VERSION "HNNBNNNYNNNNNNNNNNNNNNNNNNNNNNNNNNNNNNNNNN/4/%%%/4/'%**4NNN///"

NS_ :

BS_:

BU_: AEM BAP_Tester E_Sound FBK FLA Gateway Gateway_PAG ISE MRR_HL MRR_HR NightVision RDK SAK SAK2 SCR STH_MLBevo TopView

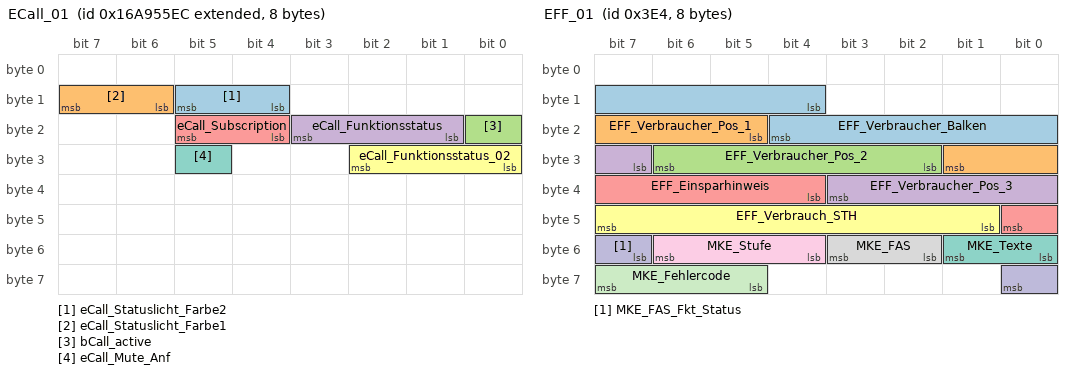
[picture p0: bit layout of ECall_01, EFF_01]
BO_ 2527679980 ECall_01: 8 Gateway
 SG_ eCall_Statuslicht_Farbe2 : 12|2@1+ (1.0,0.0) [0.0|3] ""  Vector__XXX
 SG_ eCall_Statuslicht_Farbe1 : 14|2@1+ (1.0,0.0) [0.0|3] ""  Vector__XXX
 SG_ bCall_active : 16|1@1+ (1.0,0.0) [0.0|1] ""  Vector__XXX
 SG_ eCall_Funktionsstatus : 17|3@1+ (1.0,0.0) [0.0|7] ""  Vector__XXX
 SG_ eCall_Subscription : 20|2@1+ (1.0,0.0) [0.0|3] ""  Vector__XXX
 SG_ eCall_Funktionsstatus_02 : 24|3@1+ (1.0,0.0) [0.0|7] ""  SAK,SAK2
 SG_ eCall_Mute_Anf : 29|1@1+ (1.0,0.0) [0.0|1] ""  SAK,SAK2

BO_ 996 EFF_01: 8 Gateway
 SG_ EFF_Verbraucher_Balken : 12|9@1+ (0.01,0) [0.00|5.09] "Unit_LiterPerHour"  Vector__XXX
 SG_ EFF_Verbraucher_Pos_1 : 21|5@1+ (1.0,0.0) [0.0|31] ""  Vector__XXX
 SG_ EFF_Verbraucher_Pos_2 : 26|5@1+ (1.0,0.0) [0.0|31] ""  Vector__XXX
 SG_ EFF_Verbraucher_Pos_3 : 31|5@1+ (1.0,0.0) [0.0|31] ""  Vector__XXX
 SG_ EFF_Einsparhinweis : 36|5@1+ (1.0,0.0) [0.0|31] ""  Vector__XXX
 SG_ EFF_Verbrauch_STH : 41|7@1+ (0.01,0) [0.00|1.26] "Unit_LiterPerHour"  Vector__XXX
 SG_ MKE_Texte : 48|2@1+ (1.0,0.0) [0.0|3] ""  NightVision
 SG_ MKE_FAS : 50|2@1+ (1.0,0.0) [0.0|3] ""  NightVision
 SG_ MKE_Stufe : 52|3@1+ (1.0,0.0) [0.0|7] ""  Vector__XXX
 SG_ MKE_FAS_Fkt_Status : 55|2@1+ (1.0,0.0) [0.0|3] ""  Vector__XXX
 SG_ MKE_Fehlercode : 61|3@1+ (1.0,0.0) [0.0|7] ""  Vector__XXX

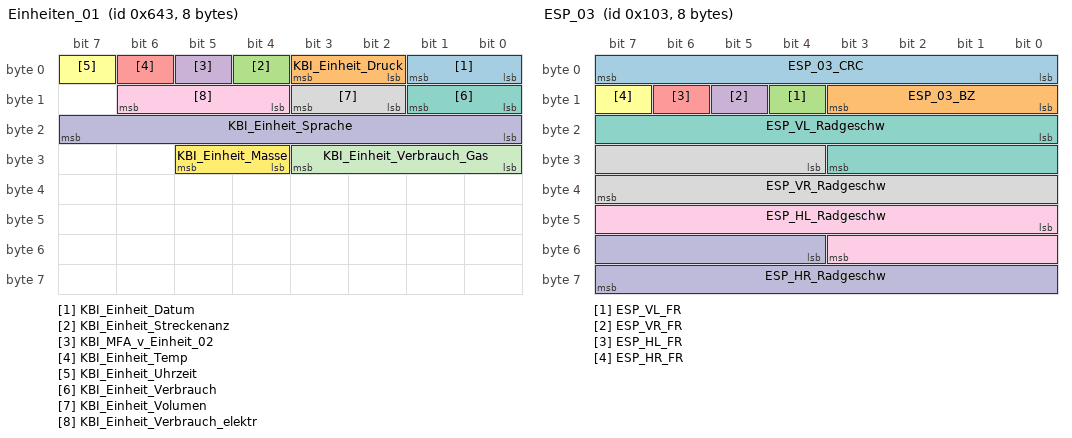
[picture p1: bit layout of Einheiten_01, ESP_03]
BO_ 1603 Einheiten_01: 8 Gateway
 SG_ KBI_Einheit_Datum : 0|2@1+ (1.0,0.0) [0.0|3] ""  Vector__XXX
 SG_ KBI_Einheit_Druck : 2|2@1+ (1.0,0.0) [0.0|3] ""  RDK
 SG_ KBI_Einheit_Streckenanz : 4|1@1+ (1.0,0.0) [0.0|1] ""  Vector__XXX
 SG_ KBI_MFA_v_Einheit_02 : 5|1@1+ (1.0,0.0) [0.0|1] ""  Vector__XXX
 SG_ KBI_Einheit_Temp : 6|1@1+ (1.0,0.0) [0.0|1] ""  RDK
 SG_ KBI_Einheit_Uhrzeit : 7|1@1+ (1.0,0.0) [0.0|1] ""  Vector__XXX
 SG_ KBI_Einheit_Verbrauch : 8|2@1+ (1.0,0.0) [0.0|3] ""  Vector__XXX
 SG_ KBI_Einheit_Volumen : 10|2@1+ (1.0,0.0) [0.0|3] ""  Vector__XXX
 SG_ KBI_Einheit_Verbrauch_elektr : 12|3@1+ (1.0,0.0) [0.0|7] ""  Vector__XXX
 SG_ KBI_Einheit_Sprache : 16|8@1+ (1,0) [0|255] ""  Vector__XXX
 SG_ KBI_Einheit_Verbrauch_Gas : 24|4@1+ (1.0,0.0) [0.0|15] ""  Vector__XXX
 SG_ KBI_Einheit_Masse : 28|2@1+ (1.0,0.0) [0.0|3] ""  Vector__XXX

BO_ 259 ESP_03: 8 Gateway
 SG_ ESP_03_CRC : 0|8@1+ (1,0) [0|255] ""  Vector__XXX
 SG_ ESP_03_BZ : 8|4@1+ (1,0) [0|15] ""  Vector__XXX
 SG_ ESP_VL_FR : 12|1@1+ (1.0,0.0) [0.0|1] ""  Vector__XXX
 SG_ ESP_VR_FR : 13|1@1+ (1.0,0.0) [0.0|1] ""  Vector__XXX
 SG_ ESP_HL_FR : 14|1@1+ (1.0,0.0) [0.0|1] ""  Vector__XXX
 SG_ ESP_HR_FR : 15|1@1+ (1.0,0.0) [0.0|1] ""  Vector__XXX
 SG_ ESP_VL_Radgeschw : 16|12@1+ (0.1,0) [0.0|409.2] "Unit_KiloMeterPerHour"  TopView
 SG_ ESP_VR_Radgeschw : 28|12@1+ (0.1,0) [0.0|409.2] "Unit_KiloMeterPerHour"  TopView
 SG_ ESP_HL_Radgeschw : 40|12@1+ (0.1,0) [0.0|409.2] "Unit_KiloMeterPerHour"  TopView
 SG_ ESP_HR_Radgeschw : 52|12@1+ (0.1,0) [0.0|409.2] "Unit_KiloMeterPerHour"  TopView

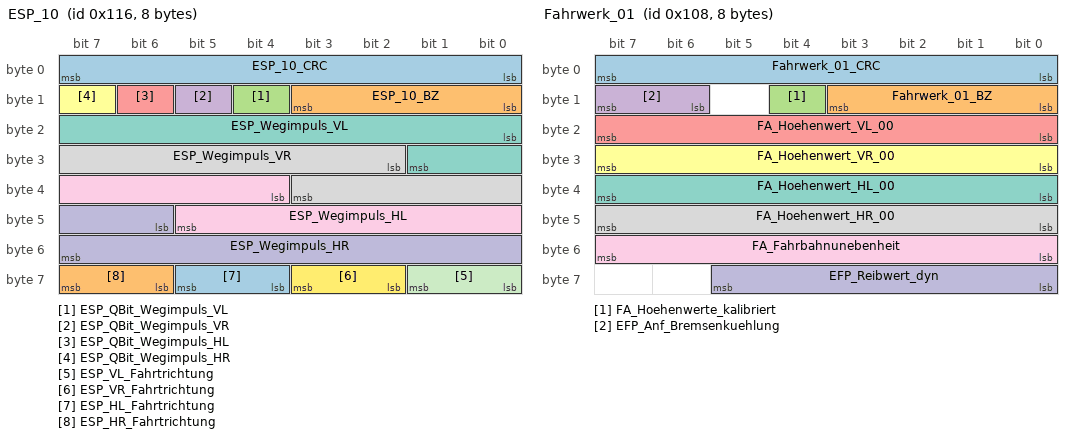
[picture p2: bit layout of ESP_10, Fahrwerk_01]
BO_ 278 ESP_10: 8 Gateway
 SG_ ESP_10_CRC : 0|8@1+ (1,0) [0|255] ""  Vector__XXX
 SG_ ESP_10_BZ : 8|4@1+ (1,0) [0|15] ""  Vector__XXX
 SG_ ESP_QBit_Wegimpuls_VL : 12|1@1+ (1.0,0.0) [0.0|1] ""  RDK,TopView
 SG_ ESP_QBit_Wegimpuls_VR : 13|1@1+ (1.0,0.0) [0.0|1] ""  RDK,TopView
 SG_ ESP_QBit_Wegimpuls_HL : 14|1@1+ (1.0,0.0) [0.0|1] ""  RDK,TopView
 SG_ ESP_QBit_Wegimpuls_HR : 15|1@1+ (1.0,0.0) [0.0|1] ""  RDK,TopView
 SG_ ESP_Wegimpuls_VL : 16|10@1+ (1,0) [0|1000] ""  RDK,TopView
 SG_ ESP_Wegimpuls_VR : 26|10@1+ (1,0) [0|1000] ""  RDK,TopView
 SG_ ESP_Wegimpuls_HL : 36|10@1+ (1,0) [0|1000] ""  RDK,TopView
 SG_ ESP_Wegimpuls_HR : 46|10@1+ (1,0) [0|1000] ""  RDK,TopView
 SG_ ESP_VL_Fahrtrichtung : 56|2@1+ (1.0,0.0) [0.0|3] ""  RDK,TopView
 SG_ ESP_VR_Fahrtrichtung : 58|2@1+ (1.0,0.0) [0.0|3] ""  RDK,TopView
 SG_ ESP_HL_Fahrtrichtung : 60|2@1+ (1.0,0.0) [0.0|3] ""  RDK,TopView
 SG_ ESP_HR_Fahrtrichtung : 62|2@1+ (1.0,0.0) [0.0|3] ""  RDK,TopView

BO_ 418 ESP_15: 8 Gateway
 SG_ ESP_15_CRC : 0|8@1+ (1,0) [0|255] ""  Vector__XXX
 SG_ ESP_15_BZ : 8|4@1+ (1,0) [0|15] ""  Vector__XXX
 SG_ HMS_P_beibehalten_GE : 12|2@1+ (1.0,0.0) [0.0|3] ""  Vector__XXX
 SG_ HMS_Konsistenz_GE : 14|1@1+ (1.0,0.0) [0.0|1] ""  Vector__XXX
 SG_ HMS_Konsistenz_IPA : 15|1@1+ (1.0,0.0) [0.0|1] ""  Vector__XXX
 SG_ HMS_Konsistenz_STA : 18|1@1+ (1.0,0.0) [0.0|1] ""  Vector__XXX
 SG_ HMS_Konsistenz_MO : 19|1@1+ (1.0,0.0) [0.0|1] ""  Vector__XXX
 SG_ HMS_halten_nicht_verfuegbar : 20|1@1+ (1.0,0.0) [0.0|1] ""  Vector__XXX
 SG_ NL_PRIM_STP_01_Status : 21|3@1+ (1.0,0.0) [0.0|7] ""  Vector__XXX
 SG_ VMM_Warnblinken : 24|1@1+ (1.0,0.0) [0.0|1] ""  Vector__XXX
 SG_ VZM_Status : 26|3@1+ (1.0,0.0) [0.0|7] ""  NightVision
 SG_ HMS_Notstopp_Status : 29|3@1+ (1.0,0.0) [0.0|7] ""  Vector__XXX
 SG_ HMS_parken_nicht_verfuegbar : 32|1@1+ (1.0,0.0) [0.0|1] ""  Vector__XXX
 SG_ HMS_Anforderung_GE : 33|3@1+ (1.0,0.0) [0.0|7] ""  Vector__XXX
 SG_ HMS_Systemstatus : 36|4@1+ (1.0,0.0) [0.0|15] ""  Vector__XXX
 SG_ HMS_Stillstand : 40|3@1+ (1.0,0.0) [0.0|7] ""  Vector__XXX
 SG_ HMS_aktives_System : 43|5@1+ (1.0,0.0) [0.0|31] ""  Vector__XXX
 SG_ HMS_Konsistenz_HVLM : 48|1@1+ (1.0,0.0) [0.0|1] ""  Vector__XXX
 SG_ HMS_Konsistenz_ACC : 49|1@1+ (1.0,0.0) [0.0|1] ""  Vector__XXX
 SG_ HMS_Fehlerstatus : 50|3@1+ (1.0,0.0) [0.0|7] ""  Vector__XXX
 SG_ ESP_Index_Haltemoment : 53|1@1+ (1.0,0.0) [0.0|1] ""  Vector__XXX
 SG_ ESP_Haltemoment : 54|10@1+ (10,0) [0|10210] "Unit_NewtoMeter"  Vector__XXX

BO_ 1629 ESP_20: 8 Gateway
 SG_ ESP_20_CRC : 0|8@1+ (1,0) [0|255] ""  Vector__XXX
 SG_ ESP_20_BZ : 8|4@1+ (1,0) [0|15] ""  Vector__XXX
 SG_ BR_Systemart : 12|2@1+ (1.0,0.0) [0.0|3] ""  Vector__XXX
 SG_ ESP_SpannungsAnf_02 : 14|2@1+ (1.0,0.0) [0.0|3] ""  Vector__XXX
 SG_ ESP_Zaehnezahl : 16|8@1+ (1,0) [0|255] ""  TopView
 SG_ ESP_Charisma_FahrPr : 24|4@1+ (1.0,0.0) [0.0|15] ""  Vector__XXX
 SG_ ESP_Charisma_Status : 28|2@1+ (1.0,0.0) [0.0|3] ""  Vector__XXX
 SG_ ESP_Wiederstart_Anz_01 : 30|1@1+ (1.0,0.0) [0.0|1] ""  Vector__XXX
 SG_ ESP_Wiederstart_Anz_02 : 31|1@1+ (1.0,0.0) [0.0|1] ""  Vector__XXX
 SG_ ESP_Wiederstart_Anz_03 : 32|1@1+ (1.0,0.0) [0.0|1] ""  Vector__XXX
 SG_ ESP_Wiederstart_Anz_04 : 33|1@1+ (1.0,0.0) [0.0|1] ""  Vector__XXX
 SG_ ESP_Stoppverbot_Anz_01 : 34|1@1+ (1.0,0.0) [0.0|1] ""  Vector__XXX
 SG_ ESP_Stoppverbot_Anz_02 : 35|1@1+ (1.0,0.0) [0.0|1] ""  Vector__XXX
 SG_ ESP_Stoppverbot_Anz_03 : 36|1@1+ (1.0,0.0) [0.0|1] ""  Vector__XXX
 SG_ ESP_Stoppverbot_Anz_04 : 37|1@1+ (1.0,0.0) [0.0|1] ""  Vector__XXX
 SG_ ESP_Stoppverbot_Anz_05 : 38|1@1+ (1.0,0.0) [0.0|1] ""  Vector__XXX
 SG_ ESP_Stoppverbot_Anz_06 : 39|1@1+ (1.0,0.0) [0.0|1] ""  Vector__XXX
 SG_ ESP_Stoppverbot_Anz_07 : 40|1@1+ (1.0,0.0) [0.0|1] ""  Vector__XXX
 SG_ ESP_Stoppverbot_Anz_Std : 41|1@1+ (1.0,0.0) [0.0|1] ""  Vector__XXX
 SG_ ESP_Dachrelingsensor : 42|2@1+ (1.0,0.0) [0.0|3] ""  Vector__XXX
 SG_ ESP_Stoppverbot_Anz_08 : 44|1@1+ (1.0,0.0) [0.0|1] ""  Vector__XXX
 SG_ HDC_Charisma_FahrPr : 45|4@1+ (1.0,0.0) [0.0|15] ""  Vector__XXX
 SG_ HDC_Charisma_Status : 49|2@1+ (1.0,0.0) [0.0|3] ""  Vector__XXX
 SG_ BR_QBit_Reifenumfang : 51|1@1+ (1.0,0.0) [0.0|1] ""  TopView
 SG_ BR_Reifenumfang : 52|12@1+ (1,0) [0|4095] "Unit_MilliMeter"  TopView

BO_ 253 ESP_21: 8 Gateway
 SG_ ESP_21_CRC : 0|8@1+ (1,0) [0|255] ""  Vector__XXX
 SG_ ESP_21_BZ : 8|4@1+ (1,0) [0|15] ""  Vector__XXX
 SG_ BR_Eingriffsmoment : 12|10@1+ (1,-509) [-509|509] ""  Vector__XXX
 SG_ MSR_verfuegbar : 22|1@1+ (1.0,0.0) [0.0|1] ""  Vector__XXX
 SG_ ESP_Diagnose : 23|1@1+ (1.0,0.0) [0.0|1] ""  Vector__XXX
 SG_ ESC_v_Signal_Qualifier_High_Low : 24|3@1+ (1.0,0.0) [0.0|7] ""  Vector__XXX
 SG_ ESP_Vorsteuerung : 28|1@1+ (1.0,0.0) [0.0|1] ""  Vector__XXX
 SG_ OBD_Schlechtweg : 30|1@1+ (1.0,0.0) [0.0|1] ""  AEM
 SG_ OBD_QBit_Schlechtweg : 31|1@1+ (1.0,0.0) [0.0|1] ""  Vector__XXX
 SG_ ESP_v_Signal : 32|16@1+ (0.01,0) [0.00|655.32] "Unit_KiloMeterPerHour"  AEM,E_Sound,FBK,FLA,ISE,NightVision,RDK,SAK,SAK2,SCR,STH_MLBevo,TopView
 SG_ ASR_Tastung_passiv : 48|1@1+ (1.0,0.0) [0.0|1] ""  TopView
 SG_ ESP_Tastung_passiv : 49|1@1+ (1.0,0.0) [0.0|1] ""  TopView
 SG_ ESP_Systemstatus : 50|1@1+ (1.0,0.0) [0.0|1] ""  TopView
 SG_ ASR_Schalteingriff : 51|2@1+ (1.0,0.0) [0.0|3] ""  Vector__XXX
 SG_ ESP_QBit_v_Signal : 55|1@1+ (1.0,0.0) [0.0|1] ""  FLA,NightVision,RDK,SCR,STH_MLBevo,TopView
 SG_ ABS_Bremsung : 56|1@1+ (1.0,0.0) [0.0|1] ""  TopView
 SG_ ASR_Anf : 57|1@1+ (1.0,0.0) [0.0|1] ""  TopView
 SG_ MSR_Anf : 58|1@1+ (1.0,0.0) [0.0|1] ""  TopView
 SG_ EBV_Eingriff : 59|1@1+ (1.0,0.0) [0.0|1] ""  TopView
 SG_ EDS_Eingriff : 60|1@1+ (1.0,0.0) [0.0|1] ""  TopView
 SG_ ESP_Eingriff : 61|1@1+ (1.0,0.0) [0.0|1] ""  ISE,TopView
 SG_ ESP_ASP : 62|1@1+ (1.0,0.0) [0.0|1] ""  Vector__XXX
 SG_ ESC_Neutralschaltung : 63|1@1+ (1.0,0.0) [0.0|1] ""  Vector__XXX

BO_ 427 ESP_33: 8 Gateway
 SG_ ESP_33_CRC : 0|8@1+ (1,0) [0|255] ""  Vector__XXX
 SG_ ESP_33_BZ : 8|4@1+ (1,0) [0|15] ""  Vector__XXX
 SG_ ESC_AHW_aktiv : 12|3@1+ (1.0,0.0) [0.0|7] ""  Vector__XXX
 SG_ ESC_AHW_nicht_verfuegbar : 15|1@1+ (1.0,0.0) [0.0|1] ""  Vector__XXX
 SG_ ESC_ANB_CM_aktiv : 16|2@1+ (1.0,0.0) [0.0|3] ""  Vector__XXX
 SG_ ESC_ANB_CM_nicht_verfuegbar : 18|1@1+ (1.0,0.0) [0.0|1] ""  Vector__XXX
 SG_ ESC_Warnruck_aktiv : 19|4@1+ (1.0,0.0) [0.0|15] ""  Vector__XXX
 SG_ ESC_Warnruck_nicht_verfuegbar : 23|1@1+ (1.0,0.0) [0.0|1] ""  Vector__XXX
 SG_ ESC_Prefill_aktiv : 24|1@1+ (1.0,0.0) [0.0|1] ""  NightVision
 SG_ ESC_Prefill_nicht_verfuegbar : 25|1@1+ (1.0,0.0) [0.0|1] ""  NightVision
 SG_ ESC_HBA_aktiv : 26|1@1+ (1.0,0.0) [0.0|1] ""  NightVision
 SG_ ESC_HBA_nicht_verfuegbar : 27|1@1+ (1.0,0.0) [0.0|1] ""  NightVision
 SG_ ESC_TSK_SRBM_Anf : 28|1@1+ (1.0,0.0) [0.0|1] ""  Vector__XXX
 SG_ ESC_TSK_SRBM_nicht_verfuegbar : 29|1@1+ (1.0,0.0) [0.0|1] ""  Vector__XXX
 SG_ ESC_Verz_Reg_aktiv : 30|4@1+ (1.0,0.0) [0.0|15] ""  Vector__XXX
 SG_ ESC_Verz_Reg_nicht_verfuegbar : 34|1@1+ (1.0,0.0) [0.0|1] ""  Vector__XXX
 SG_ ESC_Verz_Reg_TB_nicht_verfuegbar : 35|1@1+ (1.0,0.0) [0.0|1] ""  Vector__XXX
 SG_ ESC_Verz_Reg_ZB_nicht_verfuegbar : 36|1@1+ (1.0,0.0) [0.0|1] ""  Vector__XXX
 SG_ ESC_Bremslicht_unplausibel : 37|1@1+ (1.0,0.0) [0.0|1] ""  Vector__XXX
 SG_ ESC_Konsistenz_ACC : 38|1@1+ (1.0,0.0) [0.0|1] ""  Vector__XXX
 SG_ ESC_Konsistenz_AWV : 39|1@1+ (1.0,0.0) [0.0|1] ""  Vector__XXX
 SG_ ESC_Konsistenz_ARA : 40|1@1+ (1.0,0.0) [0.0|1] ""  Vector__XXX
 SG_ ESC_Konsistenz_IPA : 41|1@1+ (1.0,0.0) [0.0|1] ""  Vector__XXX
 SG_ ESC_Konsistenz_FCW : 42|1@1+ (1.0,0.0) [0.0|1] ""  Vector__XXX
 SG_ ESC_Konsistenz_NV : 43|1@1+ (1.0,0.0) [0.0|1] ""  NightVision
 SG_ ESC_Konsistenz_RCTA : 44|1@1+ (1.0,0.0) [0.0|1] ""  Vector__XXX
 SG_ ESC_Konsistenz_TSK : 45|1@1+ (1.0,0.0) [0.0|1] ""  Vector__XXX
 SG_ ESC_Konsistenz_vFGS : 46|1@1+ (1.0,0.0) [0.0|1] ""  Vector__XXX
 SG_ ESC_Konsistenz_STA : 47|1@1+ (1.0,0.0) [0.0|1] ""  Vector__XXX
 SG_ ESC_Fahrer_Bremsdruck_bestimmend : 48|1@1+ (1.0,0.0) [0.0|1] ""  Vector__XXX
 SG_ ESC_Konsistenz_EA : 49|1@1+ (1.0,0.0) [0.0|1] ""  Vector__XXX
 SG_ ESC_Konsistenz_BFF : 50|1@1+ (1.0,0.0) [0.0|1] ""  Vector__XXX
 SG_ ESC_Konsistenz_MKB : 51|1@1+ (1.0,0.0) [0.0|1] ""  Vector__XXX
 SG_ ESC_Verz_ASIL_Verfuegbarkeit : 52|3@1+ (1.0,0.0) [0.0|7] ""  Vector__XXX
 SG_ ESC_Pumpenanlauf_aktiv : 55|1@1+ (1.0,0.0) [0.0|1] ""  Vector__XXX
 SG_ ESC_Konsistenz_AGW : 56|1@1+ (1.0,0.0) [0.0|1] ""  Vector__XXX
 SG_ ESC_Konsistenz_KAS : 57|1@1+ (1.0,0.0) [0.0|1] ""  Vector__XXX
 SG_ ESC_Konsistenz_PCF : 58|1@1+ (1.0,0.0) [0.0|1] ""  Vector__XXX
 SG_ ESC_Konsistenz_FAS_VK : 59|1@1+ (1.0,0.0) [0.0|1] ""  Vector__XXX
 SG_ ESC_Verz_Begrenzung : 60|1@1+ (1.0,0.0) [0.0|1] ""  Vector__XXX
 SG_ ESC_Konsistenz_AWA : 61|1@1+ (1.0,0.0) [0.0|1] ""  Vector__XXX

BO_ 264 Fahrwerk_01: 8 Gateway
 SG_ Fahrwerk_01_CRC : 0|8@1+ (1,0) [0|255] ""  Vector__XXX
 SG_ Fahrwerk_01_BZ : 8|4@1+ (1,0) [0|15] ""  Vector__XXX
 SG_ FA_Hoehenwerte_kalibriert : 12|1@1+ (1.0,0.0) [0.0|1] ""  TopView
 SG_ EFP_Anf_Bremsenkuehlung : 14|2@1+ (1.0,0.0) [0.0|3] ""  Vector__XXX
 SG_ FA_Hoehenwert_VL_00 : 16|8@1+ (1,-127) [-127|126] "Unit_MilliMeter"  TopView
 SG_ FA_Hoehenwert_VR_00 : 24|8@1+ (1,-127) [-127|126] "Unit_MilliMeter"  TopView
 SG_ FA_Hoehenwert_HL_00 : 32|8@1+ (1,-127) [-127|126] "Unit_MilliMeter"  TopView
 SG_ FA_Hoehenwert_HR_00 : 40|8@1+ (1,-127) [-127|126] "Unit_MilliMeter"  TopView
 SG_ FA_Fahrbahnunebenheit : 48|8@1+ (1,0) [0|253] ""  Vector__XXX
 SG_ EFP_Reibwert_dyn : 56|6@1+ (0.03,0) [0.00|1.50] "Unit_None"  Vector__XXX

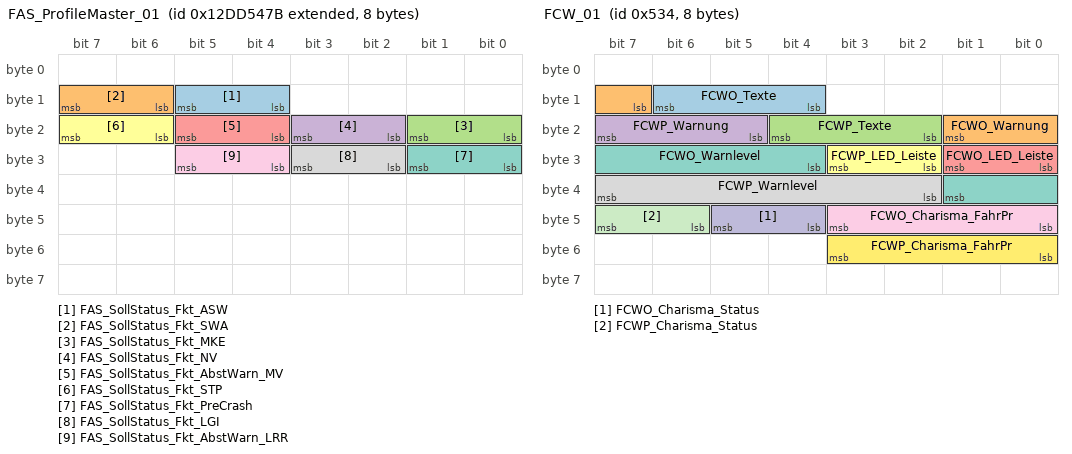
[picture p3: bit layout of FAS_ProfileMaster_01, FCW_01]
BO_ 2463978619 FAS_ProfileMaster_01: 8 Gateway
 SG_ FAS_SollStatus_Fkt_ASW : 12|2@1+ (1.0,0.0) [0.0|3] ""  MRR_HR
 SG_ FAS_SollStatus_Fkt_SWA : 14|2@1+ (1.0,0.0) [0.0|3] ""  MRR_HR
 SG_ FAS_SollStatus_Fkt_MKE : 16|2@1+ (1.0,0.0) [0.0|3] ""  Vector__XXX
 SG_ FAS_SollStatus_Fkt_NV : 18|2@1+ (1.0,0.0) [0.0|3] ""  NightVision
 SG_ FAS_SollStatus_Fkt_AbstWarn_MV : 20|2@1+ (1.0,0.0) [0.0|3] ""  Vector__XXX
 SG_ FAS_SollStatus_Fkt_STP : 22|2@1+ (1.0,0.0) [0.0|3] ""  Vector__XXX
 SG_ FAS_SollStatus_Fkt_PreCrash : 24|2@1+ (1.0,0.0) [0.0|3] ""  Vector__XXX
 SG_ FAS_SollStatus_Fkt_LGI : 26|2@1+ (1.0,0.0) [0.0|3] ""  Vector__XXX
 SG_ FAS_SollStatus_Fkt_AbstWarn_LRR : 28|2@1+ (1.0,0.0) [0.0|3] ""  Vector__XXX

BO_ 1332 FCW_01: 8 Vector__XXX
 SG_ FCWO_Texte : 12|3@1+ (1.0,0.0) [0.0|7] ""  Vector__XXX
 SG_ FCWO_Warnung : 15|3@1+ (1.0,0.0) [0.0|7] ""  NightVision
 SG_ FCWP_Texte : 18|3@1+ (1.0,0.0) [0.0|7] ""  Vector__XXX
 SG_ FCWP_Warnung : 21|3@1+ (1.0,0.0) [0.0|7] ""  NightVision
 SG_ FCWO_LED_Leiste : 24|2@1+ (1.0,0.0) [0.0|3] ""  Vector__XXX
 SG_ FCWP_LED_Leiste : 26|2@1+ (1.0,0.0) [0.0|3] ""  Vector__XXX
 SG_ FCWO_Warnlevel : 28|6@1+ (1.0,0.0) [0.0|63] ""  Vector__XXX
 SG_ FCWP_Warnlevel : 34|6@1+ (1.0,0.0) [0.0|63] ""  Vector__XXX
 SG_ FCWO_Charisma_FahrPr : 40|4@1+ (1.0,0.0) [0.0|15] ""  Vector__XXX
 SG_ FCWO_Charisma_Status : 44|2@1+ (1.0,0.0) [0.0|3] ""  Vector__XXX
 SG_ FCWP_Charisma_Status : 46|2@1+ (1.0,0.0) [0.0|3] ""  Vector__XXX
 SG_ FCWP_Charisma_FahrPr : 48|4@1+ (1.0,0.0) [0.0|15] ""  Vector__XXX

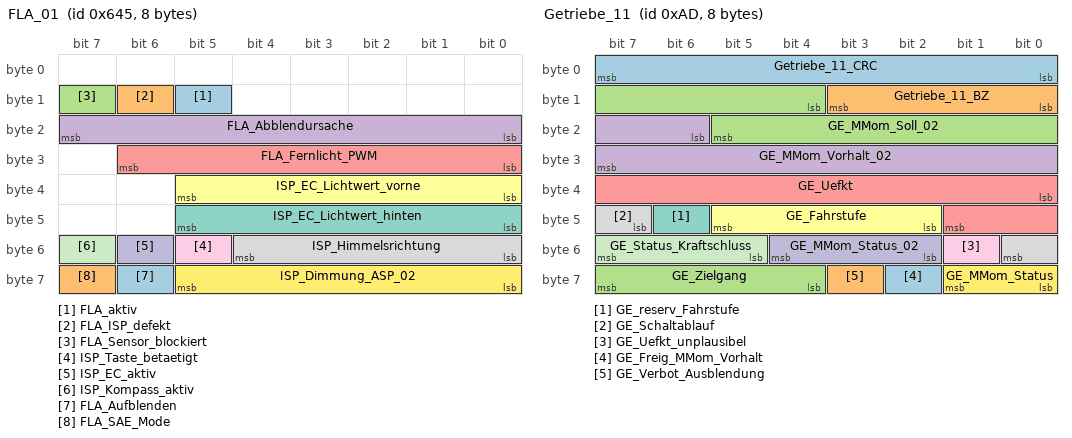
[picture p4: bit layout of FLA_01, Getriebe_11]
BO_ 1605 FLA_01: 8 FLA
 SG_ FLA_aktiv : 13|1@1+ (1.0,0.0) [0.0|1] ""  Gateway,Gateway_PAG
 SG_ FLA_ISP_defekt : 14|1@1+ (1.0,0.0) [0.0|1] ""  Gateway,Gateway_PAG
 SG_ FLA_Sensor_blockiert : 15|1@1+ (1.0,0.0) [0.0|1] ""  Gateway,Gateway_PAG
 SG_ FLA_Abblendursache : 16|8@1+ (1.0,0.0) [0.0|255] ""  Gateway,Gateway_PAG
 SG_ FLA_Fernlicht_PWM : 24|7@1+ (1,0) [0|100] "Unit_PerCent"  Gateway,Gateway_PAG
 SG_ ISP_EC_Lichtwert_vorne : 32|6@1+ (1,0) [0|61] "Unit_None"  Gateway,Gateway_PAG
 SG_ ISP_EC_Lichtwert_hinten : 40|6@1+ (1,0) [0|61] "Unit_None"  Gateway,Gateway_PAG
 SG_ ISP_Himmelsrichtung : 48|5@1+ (12,0) [0|348] "Unit_DegreOfArc"  Gateway,Gateway_PAG
 SG_ ISP_Taste_betaetigt : 53|1@1+ (1.0,0.0) [0.0|1] ""  Gateway,Gateway_PAG
 SG_ ISP_EC_aktiv : 54|1@1+ (1.0,0.0) [0.0|1] ""  Gateway,Gateway_PAG
 SG_ ISP_Kompass_aktiv : 55|1@1+ (1.0,0.0) [0.0|1] ""  Gateway,Gateway_PAG
 SG_ ISP_Dimmung_ASP_02 : 56|6@1+ (0.0226,0) [0.0000|1.4012] "Unit_Volt"  Gateway,Gateway_PAG
 SG_ FLA_Aufblenden : 62|1@1+ (1.0,0.0) [0.0|1] ""  Gateway,Gateway_PAG
 SG_ FLA_SAE_Mode : 63|1@1+ (1.0,0.0) [0.0|1] ""  Gateway,Gateway_PAG

BO_ 2589283684 FoD_01: 8 Gateway
 SG_ FoD_Transmission_Info : 60|2@1+ (1.0,0.0) [0.0|3] ""  MRR_HL,MRR_HR
 SG_ FoD_Anz_Funktionsabschaltung : 62|2@1+ (1.0,0.0) [0.0|3] ""  Vector__XXX

BO_ 2549875594 FoD_SWA_2_Req: 8 Gateway
 SG_ FoD_SWA_2_Req_Data : 0|64@1+ (1.0,0.0) [0.0|18446744073709551615] ""  MRR_HL

BO_ 2550006666 FoD_SWA_2_Resp: 8 MRR_HL
 SG_ FoD_SWA_2_Resp_Data : 0|64@1+ (1.0,0.0) [0.0|18446744073709551615] ""  Gateway,Gateway_PAG

BO_ 2549875534 FoD_SWA_Req: 8 Gateway
 SG_ FoD_SWA_Req_Data : 0|64@1+ (1.0,0.0) [0.0|18446744073709551615] ""  MRR_HR

BO_ 2550006606 FoD_SWA_Resp: 8 MRR_HR
 SG_ FoD_SWA_Resp_Data : 0|64@1+ (1.0,0.0) [0.0|18446744073709551615] ""  Gateway,Gateway_PAG

BO_ 173 Getriebe_11: 8 Gateway
 SG_ Getriebe_11_CRC : 0|8@1+ (1,0) [0|255] ""  Vector__XXX
 SG_ Getriebe_11_BZ : 8|4@1+ (1,0) [0|15] ""  Vector__XXX
 SG_ GE_MMom_Soll_02 : 12|10@1+ (1,-509) [-509|509] ""  Vector__XXX
 SG_ GE_MMom_Vorhalt_02 : 22|10@1+ (1,-509) [-509|509] ""  Vector__XXX
 SG_ GE_Uefkt : 32|10@1+ (0.1,0) [0.0|102.2] ""  Vector__XXX
 SG_ GE_Fahrstufe : 42|4@1+ (1.0,0.0) [0.0|15] ""  SAK,SAK2
 SG_ GE_reserv_Fahrstufe : 46|1@1+ (1,0) [0|1] ""  Vector__XXX
 SG_ GE_Schaltablauf : 47|2@1+ (1.0,0.0) [0.0|3] ""  Vector__XXX
 SG_ GE_Uefkt_unplausibel : 49|1@1+ (1.0,0.0) [0.0|1] ""  Vector__XXX
 SG_ GE_MMom_Status_02 : 50|3@1+ (1.0,0.0) [0.0|7] ""  Vector__XXX
 SG_ GE_Status_Kraftschluss : 53|3@1+ (1.0,0.0) [0.0|7] ""  Vector__XXX
 SG_ GE_MMom_Status : 56|2@1+ (1.0,0.0) [0.0|3] ""  Vector__XXX
 SG_ GE_Freig_MMom_Vorhalt : 58|1@1+ (1.0,0.0) [0.0|1] ""  Vector__XXX
 SG_ GE_Verbot_Ausblendung : 59|1@1+ (1.0,0.0) [0.0|1] ""  Vector__XXX
 SG_ GE_Zielgang : 60|4@1+ (1.0,0.0) [0.0|15] ""  Vector__XXX

BO_ 968 Getriebe_14: 8 Gateway
 SG_ GE_OBD_AbsperrVent : 12|4@1+ (1.0,0.0) [0.0|15] ""  Vector__XXX
 SG_ GE_amax_moeglich : 16|9@1+ (0.024,-2.016) [-2.016|10.224] "Unit_MeterPerSeconSquar"  Vector__XXX
 SG_ GE_Charisma_FahrPr : 25|4@1+ (1.0,0.0) [0.0|15] ""  Vector__XXX
 SG_ GE_Charisma_Status : 29|2@1+ (1.0,0.0) [0.0|3] ""  Vector__XXX
 SG_ GE_Freigabe_Verfallsinfo_WFS : 31|1@1+ (1.0,0.0) [0.0|1] ""  Vector__XXX
 SG_ GE_LaunchControl_LB : 32|4@1+ (1.0,0.0) [0.0|15] ""  Vector__XXX
 SG_ GE_Status_PaddleNeutral : 37|2@1+ (1.0,0.0) [0.0|3] ""  Vector__XXX
 SG_ GE_Remotestart_Betrieb : 39|1@1+ (1.0,0.0) [0.0|1] ""  Vector__XXX
 SG_ Freilauf_Charisma_FahrPr : 40|4@1+ (1.0,0.0) [0.0|15] ""  Vector__XXX
 SG_ Freilauf_Charisma_Status : 44|2@1+ (1.0,0.0) [0.0|3] ""  Vector__XXX
 SG_ GE_Freigabe_Info_WFS : 46|1@1+ (1.0,0.0) [0.0|1] ""  Vector__XXX
 SG_ GE_Sperr_Info_WFS : 47|1@1+ (1.0,0.0) [0.0|1] ""  Vector__XXX
 SG_ GE_Zustand_Kuppltemp : 48|2@1+ (1.0,0.0) [0.0|3] ""  Vector__XXX
 SG_ GE_Codierung_MSG : 50|1@1+ (1.0,0.0) [0.0|1] ""  Vector__XXX
 SG_ GE_LaunchControl : 51|1@1+ (1.0,0.0) [0.0|1] ""  E_Sound,ISE
 SG_ GE_Heizwunsch : 52|2@1+ (1.0,0.0) [0.0|3] ""  Vector__XXX
 SG_ GE_OBD_Status : 54|1@1+ (1.0,0.0) [0.0|1] ""  Vector__XXX
 SG_ GE_LFR_Adaption : 55|1@1+ (1.0,0.0) [0.0|1] ""  Vector__XXX
 SG_ GE_Sumpftemperatur : 56|8@1+ (1,-58) [-58|196] "Unit_DegreCelsi"  Vector__XXX

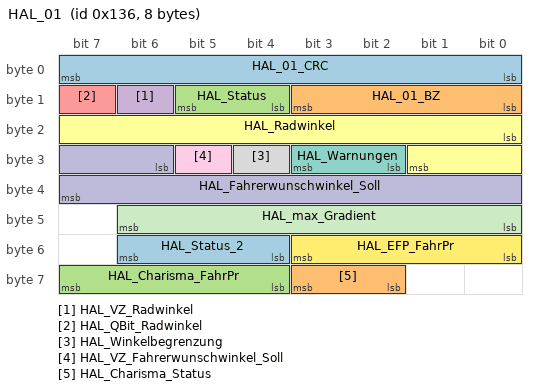
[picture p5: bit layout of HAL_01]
BO_ 310 HAL_01: 8 Gateway
 SG_ HAL_01_CRC : 0|8@1+ (1,0) [0|255] ""  Vector__XXX
 SG_ HAL_01_BZ : 8|4@1+ (1,0) [0|15] ""  Vector__XXX
 SG_ HAL_Status : 12|2@1+ (1.0,0.0) [0.0|3] ""  Vector__XXX
 SG_ HAL_VZ_Radwinkel : 14|1@1+ (1.0,0.0) [0.0|1] ""  TopView
 SG_ HAL_QBit_Radwinkel : 15|1@1+ (1.0,0.0) [0.0|1] ""  TopView
 SG_ HAL_Radwinkel : 16|10@1+ (0.01,0) [0.00|10.19] "Unit_DegreOfArc"  TopView
 SG_ HAL_Warnungen : 26|2@1+ (1.0,0.0) [0.0|3] ""  Vector__XXX
 SG_ HAL_Winkelbegrenzung : 28|1@1+ (1.0,0.0) [0.0|1] ""  Vector__XXX
 SG_ HAL_VZ_Fahrerwunschwinkel_Soll : 29|1@1+ (1.0,0.0) [0.0|1] ""  Vector__XXX
 SG_ HAL_Fahrerwunschwinkel_Soll : 30|10@1+ (0.01,0) [0.00|10.21] "Unit_DegreOfArc"  Vector__XXX
 SG_ HAL_max_Gradient : 40|7@1+ (0.1,0) [0.0|12.5] "Unit_DegreOfArcPerSecon"  Vector__XXX
 SG_ HAL_EFP_FahrPr : 48|4@1+ (1.0,0.0) [0.0|15] ""  Vector__XXX
 SG_ HAL_Status_2 : 52|3@1+ (1.0,0.0) [0.0|7] ""  Vector__XXX
 SG_ HAL_Charisma_Status : 58|2@1+ (1.0,0.0) [0.0|3] ""  Vector__XXX
 SG_ HAL_Charisma_FahrPr : 60|4@1+ (1.0,0.0) [0.0|15] ""  Vector__XXX

BO_ 1524 Innenlicht_11: 8 Gateway
 SG_ IL_Dimmung_V_Tuerkontur : 0|8@1+ (1,0) [0|100] "Unit_PerCent"  Vector__XXX
 SG_ IL_Dimmung_H_Tuerkontur : 8|8@1+ (1,0) [0|100] "Unit_PerCent"  Vector__XXX
 SG_ IL_Dimmung_Tuerinnengriff : 16|8@1+ (1,0) [0|100] "Unit_PerCent"  Vector__XXX
 SG_ IL_Dimmung_Umfeldbel : 24|8@1+ (1,0) [0|100] "Unit_PerCent"  Vector__XXX
 SG_ IL_Bel_FS_Ausstieg : 32|1@1+ (1.0,0.0) [0.0|1] ""  Vector__XXX
 SG_ IL_Bel_BFS_Ausstieg : 33|1@1+ (1.0,0.0) [0.0|1] ""  Vector__XXX
 SG_ IL_Bel_HFS_Ausstieg : 34|1@1+ (1.0,0.0) [0.0|1] ""  Vector__XXX
 SG_ IL_Bel_HBFS_Ausstieg : 35|1@1+ (1.0,0.0) [0.0|1] ""  Vector__XXX
 SG_ BCM1_Innenlicht_gedimmt_V : 36|1@1+ (1.0,0.0) [0.0|1] ""  Vector__XXX
 SG_ BCM1_Innenlicht_gedimmt_H : 37|1@1+ (1.0,0.0) [0.0|1] ""  Vector__XXX
 SG_ IL_Innenlicht_aktiv : 38|1@1+ (1.0,0.0) [0.0|1] ""  FLA
 SG_ IL_Klemme_30G_aktiv : 39|1@1+ (1.0,0.0) [0.0|1] ""  Vector__XXX
 SG_ BCM1_DI_Rampe_Innenlicht : 40|1@1+ (1.0,0.0) [0.0|1] ""  Vector__XXX
 SG_ BCM1_DI_Rampe_Leselicht : 41|1@1+ (1.0,0.0) [0.0|1] ""  Vector__XXX
 SG_ BCM1_Innenlicht_H : 42|1@1+ (1.0,0.0) [0.0|1] ""  Vector__XXX
 SG_ BCM1_Innenlicht_V : 43|1@1+ (1.0,0.0) [0.0|1] ""  Vector__XXX
 SG_ BCM1_Leselicht_Anf_hl : 44|1@1+ (1.0,0.0) [0.0|1] ""  Vector__XXX
 SG_ BCM1_Leselicht_Anf_hr : 45|1@1+ (1.0,0.0) [0.0|1] ""  Vector__XXX
 SG_ BCM1_Leselicht_Anf_vl : 46|1@1+ (1.0,0.0) [0.0|1] ""  Vector__XXX
 SG_ BCM1_Leselicht_Anf_vr : 47|1@1+ (1.0,0.0) [0.0|1] ""  Vector__XXX
 SG_ BCM1_Leuchten_Aus : 48|1@1+ (1.0,0.0) [0.0|1] ""  Vector__XXX
 SG_ AMB_Charisma_FahrPr : 49|4@1+ (1.0,0.0) [0.0|15] ""  Vector__XXX
 SG_ AMB_Charisma_Status : 53|2@1+ (1.0,0.0) [0.0|3] ""  Vector__XXX
 SG_ IL_Dimmung_Lautspr : 56|8@1+ (1,0) [0|100] "Unit_PerCent"  Vector__XXX

BO_ 1838 ISO_AEM_Req: 8 Gateway
 SG_ ISO_AEM_Req_Data : 0|64@1+ (1.0,0.0) [0.0|18446744073709551615] ""  AEM

BO_ 1944 ISO_AEM_Resp: 8 AEM
 SG_ ISO_AEM_Resp_Data : 0|64@1+ (1.0,0.0) [0.0|18446744073709551615] ""  Gateway,Gateway_PAG

BO_ 1892 ISO_AGA_Req: 8 Gateway
 SG_ ISO_AGA_Req_Data : 0|64@1+ (1.0,0.0) [0.0|18446744073709551615] ""  E_Sound,SAK2

BO_ 1998 ISO_AGA_Resp: 8 E_Sound
 SG_ ISO_AGA_Resp_Data : 0|64@1+ (1.0,0.0) [0.0|18446744073709551615] ""  Gateway,Gateway_PAG

BO_ 1840 ISO_FLA_Req: 8 Gateway
 SG_ ISO_FLA_Req_Data : 0|64@1+ (1.0,0.0) [0.0|18446744073709551615] ""  FLA

BO_ 1946 ISO_FLA_Resp: 8 FLA
 SG_ ISO_FLA_Resp_Data : 0|64@1+ (1.0,0.0) [0.0|18446744073709551615] ""  Gateway,Gateway_PAG

BO_ 1795 ISO_Funktionaler_Req_Abgas: 8 Gateway
 SG_ ISO_Funktionaler_Req_Abgas : 0|64@1+ (1.0,0.0) [0.0|18446744073709551615] ""  SCR

BO_ 1792 ISO_Funktionaler_Req_All: 8 Gateway
 SG_ ISO_ALL_01_Req_Data : 0|64@1+ (1.0,0.0) [0.0|18446744073709551615] ""  AEM,E_Sound,FLA,ISE,MRR_HL,MRR_HR,NightVision,RDK,SAK,SAK2,SCR,STH_MLBevo,TopView

BO_ 2015 ISO_Funktionaler_Req_OBD: 8 Gateway
 SG_ ISO_OBD_Funktionaler_Req_Data : 0|64@1+ (1.0,0.0) [0.0|18446744073709551615] ""  SCR

BO_ 1831 ISO_NightVision_Req: 8 Gateway
 SG_ ISO_NightVision_Req_Data : 0|64@1+ (1.0,0.0) [0.0|18446744073709551615] ""  NightVision

BO_ 1937 ISO_NightVision_Resp: 8 NightVision
 SG_ ISO_NightVision_Resp_Data : 0|64@1+ (1.0,0.0) [0.0|18446744073709551615] ""  Gateway,Gateway_PAG

BO_ 1803 ISO_RDK_Req: 8 Gateway
 SG_ ISO_RDK_Req_Data : 0|64@1+ (1.0,0.0) [0.0|18446744073709551615] ""  RDK

BO_ 1909 ISO_RDK_Resp: 8 RDK
 SG_ ISO_RDK_Resp_Data : 0|64@1+ (1.0,0.0) [0.0|18446744073709551615] ""  Gateway,Gateway_PAG

BO_ 1897 ISO_Rearview_Req: 8 Gateway
 SG_ ISO_Rearview_Req_Data : 0|64@1+ (1.0,0.0) [0.0|18446744073709551615] ""  TopView

BO_ 2003 ISO_Rearview_Resp: 8 TopView
 SG_ ISO_Rearview_Resp_Data : 0|64@1+ (1.0,0.0) [0.0|18446744073709551615] ""  Gateway,Gateway_PAG

BO_ 1834 ISO_SCR_Req: 8 Gateway
 SG_ ISO_SCR_Req_Data : 0|64@1+ (1.0,0.0) [0.0|18446744073709551615] ""  SCR

BO_ 1940 ISO_SCR_Resp: 8 SCR
 SG_ ISO_SCR_Resp_Data : 0|64@1+ (1.0,0.0) [0.0|18446744073709551615] ""  Gateway,Gateway_PAG

BO_ 1820 ISO_Soundaktor_Req: 8 Gateway
 SG_ ISO_Soundaktor_Req_Data : 0|64@1+ (1.0,0.0) [0.0|18446744073709551615] ""  ISE,SAK

BO_ 1926 ISO_Soundaktor_Resp: 8 ISE
 SG_ ISO_Soundaktor_Resp_Data : 0|64@1+ (1.0,0.0) [0.0|18446744073709551615] ""  Gateway,Gateway_PAG

BO_ 1898 ISO_STH_Req: 8 Gateway
 SG_ ISO_STH_Req_Data : 0|64@1+ (1.0,0.0) [0.0|18446744073709551615] ""  STH_MLBevo

BO_ 2004 ISO_STH_Resp: 8 STH_MLBevo
 SG_ ISO_STH_Resp_Data : 0|64@1+ (1.0,0.0) [0.0|18446744073709551615] ""  Gateway,Gateway_PAG

BO_ 1870 ISO_SWA_Req: 8 Gateway
 SG_ ISO_SWA_Req_Data : 0|64@1+ (1.0,0.0) [0.0|18446744073709551615] ""  MRR_HR

BO_ 1976 ISO_SWA_Resp: 8 MRR_HR
 SG_ ISO_SWA_Resp_Data : 0|64@1+ (1.0,0.0) [0.0|18446744073709551615] ""  Gateway,Gateway_PAG

BO_ 2549874826 ISOx_SWA_2_Req: 8 Gateway
 SG_ ISOx_SWA_2_Req_Data : 0|64@1+ (1.0,0.0) [0.0|18446744073709551615] ""  MRR_HL

BO_ 2550005898 ISOx_SWA_2_Resp: 8 MRR_HL
 SG_ ISOx_SWA_2_Resp_Data : 0|64@1+ (1.0,0.0) [0.0|18446744073709551615] ""  Gateway,Gateway_PAG

BO_ 497 Kessy_11: 8 Gateway
 SG_ KY_IDG_in_Reichweite : 12|1@1+ (1.0,0.0) [0.0|1] ""  Vector__XXX
 SG_ KY_Auf_Taste : 13|1@1+ (1.0,0.0) [0.0|1] ""  Vector__XXX
 SG_ KY_HDF_Taste : 14|1@1+ (1.0,0.0) [0.0|1] ""  Vector__XXX
 SG_ KY_Panik_Taste : 15|1@1+ (1.0,0.0) [0.0|1] ""  Vector__XXX
 SG_ KY_Zu_Taste : 16|1@1+ (1.0,0.0) [0.0|1] ""  Vector__XXX
 SG_ KY_FT_Entriegelung_Autorisiert : 17|1@1+ (1.0,0.0) [0.0|1] ""  Vector__XXX
 SG_ KY_FT_Verriegelung_Autorisiert : 18|1@1+ (1.0,0.0) [0.0|1] ""  Vector__XXX
 SG_ KY_BT_Entriegelung_Autorisiert : 19|1@1+ (1.0,0.0) [0.0|1] ""  Vector__XXX
 SG_ KY_BT_Verriegelung_Autorisiert : 20|1@1+ (1.0,0.0) [0.0|1] ""  Vector__XXX
 SG_ KY_HFS_Entriegelung_Autorisiert : 21|1@1+ (1.0,0.0) [0.0|1] ""  Vector__XXX
 SG_ KY_HFS_Verriegelung_Autorisiert : 22|1@1+ (1.0,0.0) [0.0|1] ""  Vector__XXX
 SG_ KY_HBFS_Entriegelung_Autorisiert : 23|1@1+ (1.0,0.0) [0.0|1] ""  Vector__XXX
 SG_ KY_HBFS_Verriegelung_Autorisiert : 24|1@1+ (1.0,0.0) [0.0|1] ""  Vector__XXX
 SG_ KY_Front_Entr_Autorisiert : 25|1@1+ (1.0,0.0) [0.0|1] ""  Vector__XXX
 SG_ KY_Front_Verr_Autorisiert : 26|1@1+ (1.0,0.0) [0.0|1] ""  Vector__XXX
 SG_ KY_HD_Entriegelung_Autorisiert : 27|1@1+ (1.0,0.0) [0.0|1] ""  Vector__XXX
 SG_ KY_HD_Verriegelung_Autorisiert : 28|1@1+ (1.0,0.0) [0.0|1] ""  Vector__XXX
 SG_ KY_Bereich : 29|3@1+ (1.0,0.0) [0.0|7] ""  Vector__XXX
 SG_ KY_Position : 32|3@1+ (1.0,0.0) [0.0|7] ""  Vector__XXX
 SG_ KY_ZV_Signatur : 35|11@1+ (1,0) [0|2047] "Unit_None"  Vector__XXX
 SG_ Schluesselnr_Personalisierung : 46|4@1+ (1.0,0.0) [0.0|15] ""  MRR_HL,MRR_HR,NightVision
 SG_ FFB_FDF_Taste : 50|1@1+ (1.0,0.0) [0.0|1] ""  Vector__XXX
 SG_ FFB_Joker_Taste : 51|1@1+ (1.0,0.0) [0.0|1] ""  Vector__XXX
 SG_ FFB_Park_Taste : 52|1@1+ (1.0,0.0) [0.0|1] ""  Vector__XXX
 SG_ FFB_Remotestart_Taste : 53|1@1+ (1.0,0.0) [0.0|1] ""  Vector__XXX
 SG_ FBS_Aktivierung_Pilot_Parken : 54|1@1+ (1.0,0.0) [0.0|1] ""  Vector__XXX
 SG_ KY_Schluessel_im_Fzg : 55|1@1+ (1.0,0.0) [0.0|1] ""  Vector__XXX
 SG_ KY_EasyClose_Abbruch : 56|1@1+ (1.0,0.0) [0.0|1] ""  Vector__XXX
 SG_ KY_EasyClose_Status : 57|3@1+ (1.0,0.0) [0.0|7] ""  Vector__XXX
 SG_ KY_HD_Auffahrt : 60|1@1+ (1.0,0.0) [0.0|1] ""  Vector__XXX
 SG_ KY_HD_Zufahrt : 61|1@1+ (1.0,0.0) [0.0|1] ""  Vector__XXX
 SG_ KY_LKL_1_Autorisierung : 62|1@1+ (1.0,0.0) [0.0|1] ""  Vector__XXX
 SG_ KY_LKL_2_Autorisierung : 63|1@1+ (1.0,0.0) [0.0|1] ""  Vector__XXX

BO_ 960 Klemmen_Status_01: 4 Gateway
 SG_ Klemmen_Status_01_CRC : 0|8@1+ (1,0) [0|255] ""  Vector__XXX
 SG_ Klemmen_Status_01_BZ : 8|4@1+ (1,0) [0|15] ""  Vector__XXX
 SG_ RSt_Fahrerhinweise : 12|4@1+ (1.0,0.0) [0.0|15] ""  Vector__XXX
 SG_ ZAS_Kl_S : 16|1@1+ (1.0,0.0) [0.0|1] ""  Vector__XXX
 SG_ ZAS_Kl_15 : 17|1@1+ (1.0,0.0) [0.0|1] ""  AEM,E_Sound,FBK,ISE,MRR_HL,MRR_HR,NightVision,RDK,SCR,STH_MLBevo,TopView
 SG_ ZAS_Kl_X : 18|1@1+ (1.0,0.0) [0.0|1] ""  Vector__XXX
 SG_ ZAS_Kl_50_Startanforderung : 19|1@1+ (1.0,0.0) [0.0|1] ""  MRR_HL,MRR_HR
 SG_ BCM_Remotestart_Betrieb : 20|1@1+ (1.0,0.0) [0.0|1] ""  Vector__XXX
 SG_ ZAS_Kl_Infotainment : 21|1@1+ (1.0,0.0) [0.0|1] ""  Vector__XXX
 SG_ BCM_Remotestart_KL15_Anf : 22|1@1+ (1.0,0.0) [0.0|1] ""  SCR
 SG_ BCM_Remotestart_MO_Start : 23|1@1+ (1.0,0.0) [0.0|1] ""  Vector__XXX
 SG_ KST_Warn_P1_ZST_def : 24|1@1+ (1.0,0.0) [0.0|1] ""  Vector__XXX
 SG_ KST_Warn_P2_ZST_def : 25|1@1+ (1.0,0.0) [0.0|1] ""  Vector__XXX
 SG_ KST_Fahrerhinweis_1 : 26|1@1+ (1.0,0.0) [0.0|1] ""  Vector__XXX
 SG_ KST_Fahrerhinweis_2 : 27|1@1+ (1.0,0.0) [0.0|1] ""  Vector__XXX
 SG_ BCM_Ausparken_Betrieb : 28|1@1+ (1.0,0.0) [0.0|1] ""  MRR_HL,MRR_HR,NightVision
 SG_ KST_Fahrerhinweis_4 : 29|1@1+ (1.0,0.0) [0.0|1] ""  Vector__XXX
 SG_ KST_Fahrerhinweis_5 : 30|1@1+ (1.0,0.0) [0.0|1] ""  Vector__XXX
 SG_ KST_Fahrerhinweis_6 : 31|1@1+ (1.0,0.0) [0.0|1] ""  Vector__XXX

BO_TX_BU_ 2527679980 :Gateway,Gateway_PAG;
BO_TX_BU_ 996 :Gateway,Gateway_PAG;
BO_TX_BU_ 1603 :Gateway,Gateway_PAG;
BO_TX_BU_ 259 :Gateway,Gateway_PAG;
BO_TX_BU_ 278 :Gateway,Gateway_PAG;
BO_TX_BU_ 418 :Gateway,Gateway_PAG;
BO_TX_BU_ 1629 :Gateway,Gateway_PAG;
BO_TX_BU_ 253 :Gateway,Gateway_PAG;
BO_TX_BU_ 427 :Gateway,Gateway_PAG;
BO_TX_BU_ 264 :Gateway,Gateway_PAG;
BO_TX_BU_ 2463978619 :Gateway,Gateway_PAG;
BO_TX_BU_ 2589283684 :Gateway,Gateway_PAG;
BO_TX_BU_ 2549875594 :Gateway,Gateway_PAG;
BO_TX_BU_ 2549875534 :Gateway,Gateway_PAG;
BO_TX_BU_ 173 :Gateway,Gateway_PAG;
BO_TX_BU_ 968 :Gateway,Gateway_PAG;
BO_TX_BU_ 310 :Gateway,Gateway_PAG;
BO_TX_BU_ 1524 :Gateway,Gateway_PAG;
BO_TX_BU_ 1838 :Gateway,Gateway_PAG;
BO_TX_BU_ 1892 :Gateway,Gateway_PAG;
BO_TX_BU_ 1998 :E_Sound,SAK2;
BO_TX_BU_ 1840 :Gateway,Gateway_PAG;
BO_TX_BU_ 1795 :Gateway,Gateway_PAG;
BO_TX_BU_ 1792 :Gateway,Gateway_PAG;
BO_TX_BU_ 2015 :Gateway,Gateway_PAG;
BO_TX_BU_ 1831 :Gateway,Gateway_PAG;
BO_TX_BU_ 1803 :Gateway,Gateway_PAG;
BO_TX_BU_ 1897 :Gateway,Gateway_PAG;
BO_TX_BU_ 1834 :Gateway,Gateway_PAG;
BO_TX_BU_ 1820 :Gateway,Gateway_PAG;
BO_TX_BU_ 1926 :ISE,SAK;
BO_TX_BU_ 1898 :Gateway,Gateway_PAG;
BO_TX_BU_ 1870 :Gateway,Gateway_PAG;
BO_TX_BU_ 2549874826 :Gateway,Gateway_PAG;
BO_TX_BU_ 497 :Gateway,Gateway_PAG;
BO_TX_BU_ 960 :Gateway,Gateway_PAG;
CM_ BO_ 1603 "ab MQB mit 8 Byte";
CM_ BO_ 259 "MLBevo - CRC-Absicherung";
CM_ BO_ 418 "MLBevo verlangsamte 100ms-Botschaft";
CM_ BO_ 1629 "neu im MQB";
CM_ BO_ 253 "Neue Momente im MQB
Struktur ab MQB mit CRC8 entstanden aus ESP_01";
CM_ BO_ 264 "ab MLBevo mit CRC";
CM_ BO_ 960 "MQB";

CM_ SG_ 2527679980 bCall_active "1: Breakdown call is active
0: BreakdownCall is inactive";
CM_ SG_ 2527679980 eCall_Funktionsstatus "HMI-Aufruf im Kombi (Broadcast)
Fehlerfälle die im Kombi angezeigt werden können";
CM_ SG_ 2527679980 eCall_Funktionsstatus_02 "Erweiterung des Funktionsstatus für andere Funktionen
ACN aktiv, MEC aktiv
MEC = manual emergency call = maueller Notruf
ACN = automatic emergency call = automatischer Notruf";
CM_ SG_ 2527679980 eCall_Mute_Anf "Signalisiert die Aufforderungen alle Soundquellen im Fahrzeug während eines aktiven Notrufs zu muten";
CM_ SG_ 2527679980 eCall_Statuslicht_Farbe1 "Steuerung Statuslicht (Farbe1) für Funktionsrückmeldungen Emergency Call / SOS Hilferuf,
z.B. LED-Anzeige im Dachmodul.";
CM_ SG_ 2527679980 eCall_Statuslicht_Farbe2 "Steuerung Statuslicht (Farbe2) für Funktionsrückmeldungen Emergency Call / SOS Hilferuf,
z.B. LED-Anzeige im Dachmodul.";
CM_ SG_ 2527679980 eCall_Subscription "Anzeige 'Service Unsubscribed' im Kombi - Aktualisierte Namensgebung";

CM_ SG_ 996 EFF_Einsparhinweis "Anforderung der Anzeige von veschiedenen Life-Tipps";
CM_ SG_ 996 EFF_Verbrauch_STH "Verbrauchsanteil der Standheizung im Komfortverbrauch (siehe EFF_Verbraucher_Balken)";
CM_ SG_ 996 EFF_Verbraucher_Balken "Anzeige der Zusatzverbraucher (Anzeige 0-5,09 l/h in 0,01 l/h - Schritten) für BCmE (Bordcomputer mit Effizienzprogramm)";
CM_ SG_ 996 EFF_Verbraucher_Pos_1 "Name des Zusatzverbraucher an Listenposition '1' der Top-Verbraucher für die Balkenanzeige 'Zusatzverbraucher'";
CM_ SG_ 996 EFF_Verbraucher_Pos_2 "Name des Zusatzverbraucher an Listenposition '2' der Top-Verbraucher für die Balkenanzeige 'Zusatzverbraucher'";
CM_ SG_ 996 EFF_Verbraucher_Pos_3 "Name des Zusatzverbraucher an Listenposition '3' der Top-Verbraucher für die Balkenanzeige 'Zusatzverbraucher'";
CM_ SG_ 996 MKE_FAS "Sicherheitshinweis für FAS.";
CM_ SG_ 996 MKE_FAS_Fkt_Status "Statussignal für FAS-Profilemaster.";
CM_ SG_ 996 MKE_Fehlercode "Fehlercode der Funktion Müdigkeitserkennung.";
CM_ SG_ 996 MKE_Stufe "Das Signal bildet die Müdigkeitsstufe im Kombi ab:
0 - deaktiviert
1 - nicht_verfügbar
2 - Stufe_1
3 - Stufe_2
4 - Stufe_3
5 - Stufe_4
6 - reserviert
7 - reserviert";
CM_ SG_ 996 MKE_Texte "Systemhinweis und Sicherheitshinweis für Anzeige im Kombi";

CM_ SG_ 1603 KBI_Einheit_Datum "Anzeigevariante des Datums";
CM_ SG_ 1603 KBI_Einheit_Druck "Einheit des Druckes";
CM_ SG_ 1603 KBI_Einheit_Masse "Einheit der Masse (Verwendung z.B. ASTA)";
CM_ SG_ 1603 KBI_Einheit_Sprache "Siehe BAP-Datenfestlegung UnitMaster";
CM_ SG_ 1603 KBI_Einheit_Streckenanz "Einheit der Streckenanzeige";
CM_ SG_ 1603 KBI_Einheit_Temp "Einheit der Temperatur";
CM_ SG_ 1603 KBI_Einheit_Uhrzeit "Anzeigevariante der Uhrzeit";
CM_ SG_ 1603 KBI_Einheit_Verbrauch "Einheit der Verbrauchs";
CM_ SG_ 1603 KBI_Einheit_Verbrauch_elektr "Einheit elektrischer Verbrauch";
CM_ SG_ 1603 KBI_Einheit_Verbrauch_Gas "Unterscheidung zwischen M3/h und kg/h für Komfortverbrauchsberechnung.";
CM_ SG_ 1603 KBI_Einheit_Volumen "Einheit des Volumens";
CM_ SG_ 1603 KBI_MFA_v_Einheit_02 "Einheit der Geschwindigkeit, die vom Fahrer im Car-Menü gewählt wurde. Veränderliche Grösse, im Gegensatz zur Einheit des Tachokranzes.

Redundant in der Einheiten_01 Botschaft definiert, um Konsistenz zur BAP-Festlegung zu haben.";

CM_ SG_ 259 ESP_03_CRC "Ab MQB und MLBevo:
'Berechnung siehe Lastenheft 'End-to-End Kommunikationsabsicherung''

Endwerte siehe Begleitdokument 'S-PDU Kennungsfolgen'";
CM_ SG_ 259 ESP_HL_FR "Fahrtrichtungserkennung Rad Hinten Links
";
CM_ SG_ 259 ESP_HL_Radgeschw "Radgeschwindigkeit hinten links";
CM_ SG_ 259 ESP_HR_FR "Fahrtrichtungserkennung Rad Hinten Rechts
";
CM_ SG_ 259 ESP_HR_Radgeschw "Radgeschwindigkeit hinten rechts";
CM_ SG_ 259 ESP_VL_FR "Fahrtrichtungserkennung Rad Vorne Links
";
CM_ SG_ 259 ESP_VL_Radgeschw "Radgeschwindigkeit vorne links";
CM_ SG_ 259 ESP_VR_FR "Fahrtrichtungserkennung Rad Vorne Rechts

";
CM_ SG_ 259 ESP_VR_Radgeschw "Radgeschwindigkeit vorne rechts";

CM_ SG_ 278 ESP_10_BZ "Botschaftszähler

Wird im Projekt D4 und D4Hybrid nicht verwendet!  Wird im D4 PA verwendet";
CM_ SG_ 278 ESP_10_CRC "Für MLB:
'Berechnung siehe Lastenheft 'Kommunikationsabsicherung für FlexRay und CAN''

Ab MQB und MLBevo:
'Berechnung siehe Lastenheft 'End-to-End Kommunikationsabsicherung''

Endwerte siehe Begleitdokument 'S-PDU Kennungsfolgen'

Wird im Projekt";
CM_ SG_ 278 ESP_HL_Fahrtrichtung "Drehrichtung Rad HL

Weiterführende Informationen im Lastenheft spezifiziert und in der entsprechenden Fachabteilung zu erfragen.

Wird im Projekt D4 und D4Hybrid nicht verwendet!  Wird im D4 PA verwendet";
CM_ SG_ 278 ESP_HR_Fahrtrichtung "Drehrichtung Rad HR

Weiterführende Informationen im Lastenheft spezifiziert und in der entsprechenden Fachabteilung zu erfragen.

Wird im Projekt D4 und D4Hybrid nicht verwendet!  Wird im D4 PA verwendet";
CM_ SG_ 278 ESP_QBit_Wegimpuls_HL "Qualifizierungsbit Wegimpulszähler HL

Wird im Projekt D4 und D4Hybrid nicht verwendet!  Wird im D4 PA verwendet";
CM_ SG_ 278 ESP_QBit_Wegimpuls_HR "Qualifizierungsbit Wegimpulszähler HR

Wird im Projekt D4 und D4Hybrid nicht verwendet!  Wird im D4 PA verwendet";
CM_ SG_ 278 ESP_QBit_Wegimpuls_VL "Qualifizierungsbit Wegimpulszähler VL

Wird im Projekt D4 und D4Hybrid nicht verwendet!  Wird im D4 PA verwendet";
CM_ SG_ 278 ESP_QBit_Wegimpuls_VR "Qualifizierungsbit Wegimpulszähler VR

Wird im Projekt D4 und D4Hybrid nicht verwendet!  Wird im D4 PA verwendet";
CM_ SG_ 278 ESP_VL_Fahrtrichtung "Drehrichtung Rad VL

Weiterführende Informationen im Lastenheft spezifiziert und in der entsprechenden Fachabteilung zu erfragen.

Wird im Projekt D4 und D4Hybrid nicht verwendet!  Wird im D4 PA verwendet";
CM_ SG_ 278 ESP_VR_Fahrtrichtung "Drehrichtung Rad VR

Weiterführende Informationen im Lastenheft spezifiziert und in der entsprechenden Fachabteilung zu erfragen.

Wird im Projekt D4 und D4Hybrid nicht verwendet!  Wird im D4 PA verwendet";
CM_ SG_ 278 ESP_Wegimpuls_HL "Wegimpulszähler HL.
Anzahl der Wegimpulse Hinterrad links (steigende und fallende Flanke)
Zähler läuft grundsätzlich vorwärts, auch bei Rückwärtsfahrt.
Nach SG-Reset ist immer, ohne Ausnahme, 1mal der Init Wert 1021 zu senden.

Wird im Projekt D4 und";
CM_ SG_ 278 ESP_Wegimpuls_HR "Wegimpulszähler HR.
Anzahl der Wegimpulse Hinterrad rechts (steigende und fallende Flanke)
Zähler läuft grundsätzlich vorwärts, auch bei Rückwärtsfahrt.
Nach SG-Reset ist immer, ohne Ausnahme, 1mal der Init Wert 1021 zu senden.

Wird im Projekt D4 un";
CM_ SG_ 278 ESP_Wegimpuls_VL "Wegimpulszähler VL.
Anzahl der Wegimpulse Vorderrad links (steigende und fallende Flanke)
Zähler läuft grundsätzlich vorwärts, auch bei Rückwärtsfahrt.
Nach SG-Reset ist immer, ohne Ausnahme, 1mal der Init Wert 1021 zu senden.

Wird im Projekt D4 und";
CM_ SG_ 278 ESP_Wegimpuls_VR "Wegimpulszähler VR.
Anzahl der Wegimpulse Vorderrad rechts (steigende und fallende Flanke)
Zähler läuft grundsätzlich vorwärts, auch bei Rückwärtsfahrt.
Nach SG-Reset ist immer, ohne Ausnahme, 1mal der Init Wert 1021 zu senden.

Wird im Projekt D4 un";

CM_ SG_ 418 ESP_15_BZ "Botschaftszähler
Botschaft asynchron geroutet. Zählerwert kann springen.";
CM_ SG_ 418 ESP_15_CRC "Für MLB:
'Berechnung siehe Lastenheft 'Kommunikationsabsicherung für FlexRay und CAN''

Ab MQB und MLBevo:
'Berechnung siehe Lastenheft 'End-to-End Kommunikationsabsicherung''

Endwerte siehe Begleitdokument 'S-PDU Kennungsfolgen'

Wird im Projekt";
CM_ SG_ 418 ESP_Haltemoment "Zeigt in Abhängigkeit von ESP_Index_Haltemoment das notwendige Summen-Radmoment an (bergab: Bremsmoment; bergauf: Antriebsmoment), das mindestens notwendig ist um das Fahrzeug an der aktuellen Neigung zu halten.";
CM_ SG_ 418 ESP_Index_Haltemoment "Zeigt an, ob das Summen-Radmoment von ESP_Haltemoment ein Bremsmoment (bergab) oder ein Antriebsmoment (bergauf) darstellt.";
CM_ SG_ 418 HMS_aktives_System "Zeigt an, von welchem System die Anforderung gerade umgesetzt wird.";
CM_ SG_ 418 HMS_Anforderung_GE "Fordert vom Getriebe bestimmte Schaltstellungen an.";
CM_ SG_ 418 HMS_Fehlerstatus "Zeigt den Fehlerstatus des Haltemanagementsystems HMS an.
Details zu den Werten 3/4:
3=Systemeinschränkung, Parken EPB oder GSG nicht möglich
4=Systemstörung bzw. Parken EPB und GSG nicht möglich  ";
CM_ SG_ 418 HMS_halten_nicht_verfuegbar "Rueckmeldung HMS-Teilfunktion 'Halten' nicht verfuegbar.";
CM_ SG_ 418 HMS_Konsistenz_ACC "Zeigt an, ob die Kommunikation und die Anforderungen plausibel sind.";
CM_ SG_ 418 HMS_Konsistenz_GE "Zeigt an, ob die Kommunikation und die Anforderungen plausibel sind.";
CM_ SG_ 418 HMS_Konsistenz_HVLM "Zeigt an, ob die Kommunikation und die Anforderungen plausibel sind.";
CM_ SG_ 418 HMS_Konsistenz_IPA "Zeigt an, ob die Kommunikation und die Anforderungen plausibel sind.
";
CM_ SG_ 418 HMS_Konsistenz_MO "Zeigt an, ob die Kommunikation und die Anforderungen plausibel sind.";
CM_ SG_ 418 HMS_Konsistenz_STA "Zeigt an, ob die Kommunikation und die Anforderungen plausibel sind.";
CM_ SG_ 418 HMS_Notstopp_Status "Statusinformation des Notstoppsystems an die beteiligten Systeme.";
CM_ SG_ 418 HMS_P_beibehalten_GE "Fordert das Getriebe auf in Stellung 'P' zu bleiben.";
CM_ SG_ 418 HMS_parken_nicht_verfuegbar "Rueckmeldung HMS-Teilfunktionen 'Parken' nicht verfuegbar.";
CM_ SG_ 418 HMS_Stillstand "Das Signal zeigt, basierend auf den vier ESP-Raddrehzahlinformatioen, gefiltert und/oder entprellt mehrstufig den Fahrzeuggeschwindigkeitszustand an.";
CM_ SG_ 418 HMS_Systemstatus "Zeigt den aktuellen Systemstatus des HMS an.";
CM_ SG_ 418 NL_PRIM_STP_01_Status "Das Primär- Bremsregelsystem übermittelt seinen Systemstatus an zFAS und Sekundär- Bremsregelsystem. 

Der Staupilot ermittelt sich über den Status des Primär-und des Sekundärbremsregelsystems den Gesamtzustand des Notlaufreglers.";
CM_ SG_ 418 VMM_Warnblinken "Über dieses Signal wird ein Warnblinken von Funktionen des VMM (VehicleMotionManagers) angefordert.";
CM_ SG_ 418 VZM_Status "Zeigt die Verfuegbarkeit und den Zustand der VZM Funktionen im ESC an";

CM_ SG_ 1629 BR_QBit_Reifenumfang "Gesetzt bei Ersatzwert, Init oder Fehler.";
CM_ SG_ 1629 BR_Reifenumfang "Mittlerer Radumfang gerechnet in Millimeter.
Von der Bremse plausibilisierter Wert (Kopie von KBI_Reifenumfang wenn dieser plausibel) oder Ersatzwert aus Bremse wenn KBI_Reifenumfang unplausibel. Bitte das QBit beachten!

Im MEB wird das Signal KBI_Rei";
CM_ SG_ 1629 BR_Systemart "Identifikation des verbauten Bremssystems

Dient dem Kombi zur Plausibilisierung";
CM_ SG_ 1629 ESP_20_BZ "Botschaft asynchron geroutet. Zählerwert kann springen.";
CM_ SG_ 1629 ESP_20_CRC "Für MLB:
'Berechnung siehe Lastenheft 'Kommunikationsabsicherung für FlexRay und CAN''

Ab MQB und MLBevo:
'Berechnung siehe Lastenheft 'End-to-End Kommunikationsabsicherung''

Endwerte siehe Begleitdokument 'S-PDU Kennungsfolgen'";
CM_ SG_ 1629 ESP_Charisma_FahrPr "MLBevo: Aktuelles Fahrprogramm des Charisma-Teilnehmers (siehe Systemlastenheft Drive Select)
MQB: Istwert der Kennlinie (siehe Systemlastenheft MQB FPA)";
CM_ SG_ 1629 ESP_Charisma_Status "Systemstatus des Charismateilnehmers

Wert 0x3 ist nur für Fahrzeuge ab MQB relevant";
CM_ SG_ 1629 ESP_Dachrelingsensor "Erkennung auf Verbau des Dachrelingsensors und Dachquerträger.";
CM_ SG_ 1629 ESP_SpannungsAnf_02 "Forderung des ESP-SG's zur Spannungsanhebung.";
CM_ SG_ 1629 ESP_Stoppverbot_Anz_01 "Dieses Signal gibt die detaillierte Begründung für ein Stoppverbot vom Bremsensteuergerät an.";
CM_ SG_ 1629 ESP_Stoppverbot_Anz_02 "Dieses Signal gibt die detaillierte Begründung für ein Stoppverbot vom Bremsensteuergerät an.";
CM_ SG_ 1629 ESP_Stoppverbot_Anz_03 "Dieses Signal gibt die detaillierte Begründung für ein Stoppverbot vom Bremsensteuergerät an.";
CM_ SG_ 1629 ESP_Stoppverbot_Anz_04 "Dieses Signal gibt die detaillierte Begründung für ein Stoppverbot vom Bremsensteuergerät an.";
CM_ SG_ 1629 ESP_Stoppverbot_Anz_05 "Dieses Signal gibt die detaillierte Begründung für ein Stoppverbot vom Bremsensteuergerät an.";
CM_ SG_ 1629 ESP_Stoppverbot_Anz_06 "Dieses Signal gibt die detaillierte Begründung für ein Stoppverbot vom Bremsensteuergerät an.";
CM_ SG_ 1629 ESP_Stoppverbot_Anz_07 "Dieses Signal gibt die detaillierte Begründung für ein Stoppverbot vom Bremsensteuergerät an.";
CM_ SG_ 1629 ESP_Stoppverbot_Anz_08 "Dieses Signal gibt die detaillierte Begründung für ein Stoppverbot vom Bremsensteuergerät an.";
CM_ SG_ 1629 ESP_Stoppverbot_Anz_Std "Dieses Signal gibt die detaillierte Begründung für ein Stoppverbot vom Bremsensteuergerät an.";
CM_ SG_ 1629 ESP_Wiederstart_Anz_01 "Dieses Signal gibt die detaillierte Begründung für einen Wiederstart vom Bremsensteuergerät an. ";
CM_ SG_ 1629 ESP_Wiederstart_Anz_02 "Dieses Signal gibt die detaillierte Begründung für einen Wiederstart vom Bremsensteuergerät an. ";
CM_ SG_ 1629 ESP_Wiederstart_Anz_03 "Dieses Signal gibt die detaillierte Begründung für einen Wiederstart vom Bremsensteuergerät an. ";
CM_ SG_ 1629 ESP_Wiederstart_Anz_04 "Dieses Signal gibt die detaillierte Begründung für einen Wiederstart vom Bremsensteuergerät an.";
CM_ SG_ 1629 ESP_Zaehnezahl "Konstanter Wert der Zähnezahl des verwendeten Impulsrades wird ausgegeben, jeder Empfänger der Wegimpulse muss die Zähnezahl einlesen, um eine volle Umdrehung des Rades zu erkennen. 

Weiterführende Informationen im Lastenheft spezifiziert und in der en";
CM_ SG_ 1629 HDC_Charisma_FahrPr "MLBevo: Aktuelles Fahrprogramm des Charisma-Teilnehmers (siehe Systemlastenheft Drive Select)
MQB: Istwert der Kennlinie (siehe Systemlastenheft MQB FPA)";
CM_ SG_ 1629 HDC_Charisma_Status "Systemstatus des Charismateilnehmers

Wert 0x3 ist nur für Fahrzeuge ab MQB relevant";

CM_ SG_ 253 ABS_Bremsung "Antiblockiersystem, Bit zeigt auch Druckabbau an (z.B. ESP hat zuviel Druck aufgebaut oder ungebremste Regelung auf Bahnübergang)
Weiterführende Informationen im Lastenheft spezifiziert und in der entsprechenden Fachabteilung zu erfragen.";
CM_ SG_ 253 ASR_Anf "MLB: Die Momentenanforderung 'ASR_MSR_Moment_schnell' und 'ASR_Moment_langsam' sind auszuführen
MQB: Die Momentenanforderung 'BR_Eingriffsmoment' ist auszuführen";
CM_ SG_ 253 ASR_Schalteingriff "Wunsch an das Getriebe während einer ASR Regelung

MLB: Es wird nur 0x0 und 0x1 genutzt

";
CM_ SG_ 253 ASR_Tastung_passiv "ASR deaktiviert oder Schwellen geändert (projektabhängig)
Weiterführende Informationen im Lastenheft spezifiziert und in der entsprechenden Fachabteilung zu erfragen.
";
CM_ SG_ 253 BR_Eingriffsmoment "Einheitenloser Wert! Faktor in MO_Faktor_Momente_02 in Motor_Code_01 beachten!
Schnelle reduzierende (ASR) oder erhöhende (MSR) Momentanforderung an den Motor.";
CM_ SG_ 253 EBV_Eingriff "Elektronische Bremskraftverteilung, aktueller Eingriff (Druckhalten, Druckabbau)

Im MLB: kein ABS / ESP-Eingriff ???";
CM_ SG_ 253 EDS_Eingriff "Elektronische Differentialsperre";
CM_ SG_ 253 ESC_Neutralschaltung "Aufforderung seitens ABS an das Getriebe die Momentenübertragung zu unterbrechen";
CM_ SG_ 253 ESC_v_Signal_Qualifier_High_Low "Das Qualifizerungssignal ESC_v_Signal_Qualifier_High_Low gibt eine Information über die Güte der vom Bremsregelsystem ausgegebenen Geschwindigkeitsinformation 'mittlere Geschwindigkeit', wobei Vertrauensbereiche für das ausgegebene Geschwindigkeitssignal ";
CM_ SG_ 253 ESP_21_CRC "Für MLB:
'Berechnung siehe Lastenheft 'Kommunikationsabsicherung für FlexRay und CAN''

Ab MQB und MLBevo:
'Berechnung siehe Lastenheft 'End-to-End Kommunikationsabsicherung''

Endwerte siehe Begleitdokument 'S-PDU Kennungsfolgen'";
CM_ SG_ 253 ESP_ASP "MLB: Anhaenger-Stabilisierungs-Programm
MQB: Gespannstabilisierung";
CM_ SG_ 253 ESP_Diagnose "MLB: Nach Diagnoseende wird ein SW-Reset ausgelöst welcher einen Kommunikatiosausfall für max. 150ms verursacht. Dies ist bei SG mit verschärfter Timeoutüberwachung (nicht nach Konzern-LH) zu beachten.

MQB: Weiterführende Informationen im Lastenheft sp";
CM_ SG_ 253 ESP_Eingriff "Eingriff des Fahrdynamikreglers";
CM_ SG_ 253 ESP_QBit_v_Signal "Geschwindigkeit wird vom ABS/ASR oder ESP aus Ersatzwerten errechnet, wenn Bit gesetzt ist. Güte des Signals ist verändert.";
CM_ SG_ 253 ESP_Systemstatus "Fehler steht für Stillegung ESP mit Fehlereintrag.

MLB: Flag wird bei Unterspannung im Stand bis einmalig 6km/h (AU48x) oder 10 km/h (AU641, AU57x) überschritten nicht gesetzt (Ausblendung Startvorgang)
Im AU64x, AU57x gilt ESP D4 Funktionsanforderung";
CM_ SG_ 253 ESP_Tastung_passiv "ESP deaktiviert oder Schwellen geändert (projektabhängig)
Weiterführende Informationen im Lastenheft spezifiziert und in der entsprechenden Fachabteilung zu erfragen.";
CM_ SG_ 253 ESP_v_Signal "Geschwindigkeitssignal vom ABS/ASR oder ESP. Mittelwert der angetriebenen Räder.
Bei MSR oder ABS Eingriffen wird die ABS-Referenzgeschwindigkeit für >= 200ms eingespiegelt (Zeit wird mit Aktiv-Flanke der Funktionsbits getriggert)

MQB: Bei Frontantrie";
CM_ SG_ 253 ESP_Vorsteuerung "zur Unterscheidung zwischen ESP-Vorsteuermaßnahmen und ESP-Regeleingriffen";
CM_ SG_ 253 MSR_Anf "MLB: Die Momentenanforderung 'ASR_MSR_Moment_schnell' ist auszuführen.
MQB: Die Momentenanforderung 'BR_Eingriffsmoment' ist auszuführen";
CM_ SG_ 253 MSR_verfuegbar "Anzeige Verfügbarkeit der MSR Funktion 
0 = verfuegbar (MSR_Vollsystem oder MSR_Backup)
1 = nicht_verfuegbar (Init und Fehler)";
CM_ SG_ 253 OBD_Schlechtweg "Für Ausblendung der Zündaussetzererkennung im Motorsteuergerät (Otto). Bit wird gesetzt, wenn Rad-Drehbeschleunigung im ESP > Grenzwert ist. Vorteil gegenüber Radgeschwindigkeiten, dass ESP alle 2 ms dynamisch die Rad-Drehbeschleunigung errechnet und dem ";

CM_ SG_ 427 ESC_AHW_aktiv "Rueckmeldung Anhaltewegregelung aktiv
";
CM_ SG_ 427 ESC_AHW_nicht_verfuegbar "Rueckmeldung Anhaltewegregelung nicht verfuegbar
";
CM_ SG_ 427 ESC_ANB_CM_aktiv "Rueckmeldung ANB_CM (Autom_Notbremsung_Collision_Mitigation) aktiv
";
CM_ SG_ 427 ESC_ANB_CM_nicht_verfuegbar "Rueckmeldung ANB_CM nicht verfuegbar
";
CM_ SG_ 427 ESC_Bremslicht_unplausibel "Plausibilisierung der Rückmeldeinformation von BCM/AAG bezüglich Anforderung ESC_Bremslicht";
CM_ SG_ 427 ESC_Fahrer_Bremsdruck_bestimmend "Das Signal zeigt an, dass der Fahrer Bremsdruck bestimmend ist";
CM_ SG_ 427 ESC_HBA_aktiv "Rueckmeldung HBA (hydraulischer Bremsassistent) aktiv";
CM_ SG_ 427 ESC_HBA_nicht_verfuegbar "Rueckmeldung HBA (hydraulischer Bremsassistent) nicht verfuegbar";
CM_ SG_ 427 ESC_Konsistenz_ACC "Rueckmeldung Konsistenz der ACC Botschaften";
CM_ SG_ 427 ESC_Konsistenz_AGW "Rückmeldung Konsistenz der AGW-Botschaft an das ESC.";
CM_ SG_ 427 ESC_Konsistenz_ARA "Rueckmeldung Konsistenz der ARA Botschaften";
CM_ SG_ 427 ESC_Konsistenz_AWA "Rueckmeldung Konsistenz der AWA-Botschaften";
CM_ SG_ 427 ESC_Konsistenz_AWV "Rueckmeldung Konsistenz der AWV Botschaften";
CM_ SG_ 427 ESC_Konsistenz_BFF "Rückmeldung Konsistenz der Verzögerungsanforderung an das ESC-Steuergerät der Funktion 'Bremsen im freien Fahren' vom PDC_PLA_ARA-Steuergerät";
CM_ SG_ 427 ESC_Konsistenz_EA "Rueckmeldung Konsistenz der EA Botschaften (HCA)";
CM_ SG_ 427 ESC_Konsistenz_FAS_VK "Rueckmeldung Konsistenz der FAS_VK Botschaften";
CM_ SG_ 427 ESC_Konsistenz_FCW "Rueckmeldung Konsistenz der FCW Botschaften";
CM_ SG_ 427 ESC_Konsistenz_IPA "Rueckmeldung Konsistenz der IPA Botschaften";
CM_ SG_ 427 ESC_Konsistenz_KAS "Rückmeldung Konsistenz für Kreuzungsassistent-Anforderungen";
CM_ SG_ 427 ESC_Konsistenz_MKB "Rückmeldung Konsistenz für MKB-Verzögerungsanfoorderung";
CM_ SG_ 427 ESC_Konsistenz_NV "Rueckmeldung Konsistenz der NightVision Botschaften";
CM_ SG_ 427 ESC_Konsistenz_PCF "Rückmeldung der Konsistenz der PCF-Anforderungen";
CM_ SG_ 427 ESC_Konsistenz_RCTA "Rueckmeldung Konsistenz der RCTA (Rear Cross Traffic Alert) Botschaften";
CM_ SG_ 427 ESC_Konsistenz_STA "Rueckmeldung Konsistenz der STA Botschaften";
CM_ SG_ 427 ESC_Konsistenz_TSK "Rueckmeldung Konsistenz der TSK Botschaften";
CM_ SG_ 427 ESC_Konsistenz_vFGS "Rueckmeldung Konsistenz der vFGS Botschaften";
CM_ SG_ 427 ESC_Prefill_aktiv "Rueckmeldung Prefill aktiv";
CM_ SG_ 427 ESC_Prefill_nicht_verfuegbar "Rueckmeldung Prefill nicht verfuegbar";
CM_ SG_ 427 ESC_Pumpenanlauf_aktiv "Bestätigung der Durchführung eines Vorsteuerpumpenanlaufes";
CM_ SG_ 427 ESC_TSK_SRBM_Anf "Quittierung fuer TSK (SRBM=Summenradbremsmoment) Anforderung";
CM_ SG_ 427 ESC_TSK_SRBM_nicht_verfuegbar "Rueckmeldung TSK (SRBM= Summenradbremsmoment) nicht verfuegbar";
CM_ SG_ 427 ESC_Verz_ASIL_Verfuegbarkeit "Gibt die Verfuegbarkeit der VZM-Regelung an, wobei folgende Zustaende beruecksichtigt werden:
-Nicht Verfuegbarkeit wegen Sonderbetriebszustaenden (z.B. Produktionsmodus)
-ueber VZM abgebaute Fahrzeuggeschwindigkeit bei Verzögerungen a>5m/s², wobei gilt";
CM_ SG_ 427 ESC_Verz_Begrenzung "Rückmeldung angeforderte Verzögerung oder Summenradbremsmoment wird begrenzt umgesetzt  ";
CM_ SG_ 427 ESC_Verz_Reg_aktiv "Rueckmeldung Verzoegerungsregelung aktiv";
CM_ SG_ 427 ESC_Verz_Reg_nicht_verfuegbar "Rueckmeldung Verzoegerungsregelung nicht verfuegbar";
CM_ SG_ 427 ESC_Verz_Reg_TB_nicht_verfuegbar "Rueckmeldung Verzoegerungsregelung (Teilbremsung) nicht verfuegbar";
CM_ SG_ 427 ESC_Verz_Reg_ZB_nicht_verfuegbar "Rueckmeldung Verzoegerungsregelung ZB (Zielbremsung) nicht verfuegbar";
CM_ SG_ 427 ESC_Warnruck_aktiv "Rueckmeldung Warnruck aktiv";
CM_ SG_ 427 ESC_Warnruck_nicht_verfuegbar "Rueckmeldung Warnruck nicht verfuegbar";
CM_ SG_ 427 ESP_33_BZ "Botschaft asynchron geroutet. Zählerwert kann springen.";
CM_ SG_ 427 ESP_33_CRC "Für MLB:
'Berechnung siehe Lastenheft 'Kommunikationsabsicherung für FlexRay und CAN''

Ab MQB und MLBevo:
'Berechnung siehe Lastenheft 'End-to-End Kommunikationsabsicherung''

Endwerte siehe Begleitdokument 'S-PDU Kennungsfolgen'";

CM_ SG_ 264 EFP_Anf_Bremsenkuehlung "Signal steuert das Oeffnen des Bremsenkuehlkanals und ggf. das Aktivieren eines unterstützenden Lüfters.";
CM_ SG_ 264 EFP_Reibwert_dyn "Dynamisch geschaetzter Reibwert zwischen Reifen und Strasse im Grenzbereich (Variante 2)";
CM_ SG_ 264 FA_Fahrbahnunebenheit "Informationsbeschreibung des Fahrbahnzustandes";
CM_ SG_ 264 FA_Hoehenwert_HL_00 "Aktueller Höhenwert (kalibriert) Hinten Links; ungefiltertes Signal
Einheit, Offset und Faktor sind abhänig von 'FA_Hoehenwert_kalibriert'

Achtung:
Wird im AUDI B8 nicht bedient";
CM_ SG_ 264 FA_Hoehenwert_HR_00 "Aktueller Höhenwert (kalibriert) Hinten Rechts; ungefiltertes Signal
Einheit, Offset und Faktor sind abhänig von 'FA_Hoehenwert_kalibriert'

Achtung:
Wird im AUDI B8 nicht bedient";
CM_ SG_ 264 FA_Hoehenwert_VL_00 "Aktueller Höhenwert (kalibriert) Vorne Links; ungefiltertes Signal
Einheit, Offset und Faktor sind abhänig von 'FA_Hoehenwert_kalibriert'

Achtung:
Wird im AUDI B8 nicht bedient";
CM_ SG_ 264 FA_Hoehenwert_VR_00 "Aktueller Höhenwert (kalibriert) Vorne Rechts; ungefiltertes Signal
Einheit, Offset und Faktor sind abhänig von 'FA_Hoehenwert_kalibriert'

Achtung:
Wird im AUDI B8 nicht bedient";
CM_ SG_ 264 FA_Hoehenwerte_kalibriert "Legt fest, wie die Höhensensorwerte interpretiert werden müssen. Umschaltung kalibrierte Höhenwerte / Rohsignale in Byte 3-6

Achtung:
Im AUDI B8 Konstante: 0x1. D.h. es werden nur Rohwerte bedient!
Im AUDI D4 Konstante: 0x0. D.h. es werden nur Millim";
CM_ SG_ 264 Fahrwerk_01_BZ "Botschaft asynchron geroutet. Zählerwert kann springen.";
CM_ SG_ 264 Fahrwerk_01_CRC "Für MLB:
'Berechnung siehe Lastenheft 'Kommunikationsabsicherung für FlexRay und CAN''

Ab MQB und MLBevo:
'Berechnung siehe Lastenheft 'End-to-End Kommunikationsabsicherung''

Endwerte siehe Begleitdokument 'S-PDU Kennungsfolgen'";

CM_ SG_ 2463978619 FAS_SollStatus_Fkt_AbstWarn_LRR "FAS-ProfileMaster Sollstatus der Kundenfunktion";
CM_ SG_ 2463978619 FAS_SollStatus_Fkt_AbstWarn_MV "FAS-ProfileMaster Sollstatus der Kundenfunktion";
CM_ SG_ 2463978619 FAS_SollStatus_Fkt_ASW "FAS-ProfileMaster Sollstatus der Kundenfunktion";
CM_ SG_ 2463978619 FAS_SollStatus_Fkt_LGI "FAS-ProfileMaster Sollstatus der Kundenfunktion";
CM_ SG_ 2463978619 FAS_SollStatus_Fkt_MKE "FAS-ProfileMaster Sollstatus der Kundenfunktion";
CM_ SG_ 2463978619 FAS_SollStatus_Fkt_NV "FAS-ProfileMaster Sollstatus der Kundenfunktion";
CM_ SG_ 2463978619 FAS_SollStatus_Fkt_PreCrash "FAS-ProfileMaster Sollstatus der Kundenfunktion";
CM_ SG_ 2463978619 FAS_SollStatus_Fkt_STP "FAS-ProfileMaster Sollstatus der Kundenfunktion";
CM_ SG_ 2463978619 FAS_SollStatus_Fkt_SWA "FAS-ProfileMaster Sollstatus der Kundenfunktion";

CM_ SG_ 1332 FCWO_Charisma_FahrPr "MLBevo: Aktuelles Fahrprogramm des Charisma-Teilnehmers (siehe Systemlastenheft Drive Select)";
CM_ SG_ 1332 FCWO_Charisma_Status "Verfügbarkeit der Funktion FCWO für die Ansteuerung durch den Charisma-Koordinator";
CM_ SG_ 1332 FCWO_LED_Leiste "Ansteuerung der LED-Leiste durch kamerabasierte Kollisionswarnung (FCWO)";
CM_ SG_ 1332 FCWO_Texte "Hinweisanzeige im Kombi 'Hauptdisplay' durch kamerabasierte Kollisionswarnung (FCWO)

3 = Demomodus --> nur für VW
4 = System_aus --> nur für PAG
6 = ESC_aus --> nur für AUDI";
CM_ SG_ 1332 FCWO_Warnlevel "aktueller Warnlevel des kamerabasierten Forward-Collision-Warning";
CM_ SG_ 1332 FCWO_Warnung "Warnungsanzeige im Kombi 'Hauptdisplay' durch kamerabasierte Kollisionswarnung (FCWO)";
CM_ SG_ 1332 FCWP_Charisma_FahrPr "Aktuell eingestelltes Fahrprogramm der Funktion FCWP (Forward Collision Warning Pedestrian)";
CM_ SG_ 1332 FCWP_Charisma_Status "Verfügbarkeit der Funktion FCWP für die Ansteuerung durch den Charisma-Koordinator";
CM_ SG_ 1332 FCWP_LED_Leiste "Ansteuerung der LED-Leiste durch kamerabasierte Fußgängerwarnung (FCWP)";
CM_ SG_ 1332 FCWP_Texte "Hinweisanzeige im Kombi 'Hauptdisplay' durch kamerabasierte Fußgängerwarnung (FCWP)

3 = Demomodus => nur für VW
4 = System aus => nur für PAG
6 = ESC aus => nur für AUDI";
CM_ SG_ 1332 FCWP_Warnlevel "Warnlevel der Fußgaengerwarnung";
CM_ SG_ 1332 FCWP_Warnung "Warnungsanzeige im Kombi 'Hauptdisplay' durch kamerabasierte Fußgängerwarnung (FCWP)";

CM_ SG_ 1605 FLA_Abblendursache "FLA Abblendursache
(20ms Task)";
CM_ SG_ 1605 FLA_aktiv "FLA aktiv  (200ms Task)";
CM_ SG_ 1605 FLA_Aufblenden "FLA Aufblenden (20ms Task)";
CM_ SG_ 1605 FLA_Fernlicht_PWM "FLA PWM Vorgabe Fernlicht
(20ms Task)";
CM_ SG_ 1605 FLA_ISP_defekt "FLA defekt (Innenspiegelkamera oder Multifunktionskamera)
interner Fehler  (200ms Task)";
CM_ SG_ 1605 FLA_SAE_Mode "Rückmeldung an den Fahrer, über Wechsel in den SAE Modus --> wird nur für den amerikanischen Markt benötigt.";
CM_ SG_ 1605 FLA_Sensor_blockiert "FLA Sensor blockiert
Sichtbeeinträchtigung der Kamera  (200ms Task)";
CM_ SG_ 1605 ISP_Dimmung_ASP_02 "Dimmwertvorgabe für Aussenspiegel
Es wird 1:1 die Spannung am Innenspiegel nach außen übertragen.";
CM_ SG_ 1605 ISP_EC_aktiv "Status Innenspiegel (EC-Spiegel)";
CM_ SG_ 1605 ISP_EC_Lichtwert_hinten "Innenspiegel: Lichtwert hinten
";
CM_ SG_ 1605 ISP_EC_Lichtwert_vorne "Innenspiegel: Lichtwert vorne
";
CM_ SG_ 1605 ISP_Himmelsrichtung "Himmelsrichtung Kompass im EC Spiegel
Wertebereich 0-29 (12°-Schritte, 0-348°)
";
CM_ SG_ 1605 ISP_Kompass_aktiv "Status Kompass Innenspiegel";
CM_ SG_ 1605 ISP_Taste_betaetigt "ISP Taste betätigt
(200ms Task)";

CM_ SG_ 2589283684 FoD_Anz_Funktionsabschaltung "Signal triggert Aufschaltung eines Popups, um dem Fahrer die Abschaltung einer Funktion zu melden.";
CM_ SG_ 2589283684 FoD_Transmission_Info "Mit dem Signal zeigt der FoD-Master allen FoD-Slaves den Beginn und das Ende eines Freischaltuebertragungszykluses (FS-ID-Zyklus) an.";

CM_ SG_ 2549875594 FoD_SWA_2_Req_Data "FoD - Function On Demand
ISO-TP Datenkanal - FID2NA
Request Funktion 0x03 FoD-Master

FoD-Master an Slave";

CM_ SG_ 2550006666 FoD_SWA_2_Resp_Data "FoD - Function On Demand
ISO-TP Datenkanal - FID2NA
Response Knoten 0x8A

Slave an FoD Master";

CM_ SG_ 2549875534 FoD_SWA_Req_Data "FoD - Function On Demand
ISO-TP Datenkanal - FID2NA
Request Funktion 0x03 FoD-Master

FoD-Master an Heckradar/ HRE_Gen3_Master";

CM_ SG_ 2550006606 FoD_SWA_Resp_Data "FoD - Function On Demand
ISO-TP Datenkanal - FID2NA
Response Knoten 0x4E Heckradar/ HRE_Gen3_Master

Heckradar/ HRE_Gen3_Master an FoD Master";

CM_ SG_ 173 GE_Fahrstufe "Fahrprogramm des Getriebes

Hinweis: Zwischenstellung '0x0' darf nur für Zustandswechsel P/R, R/N, N/D ausgegeben werden, nicht für D/S oder D/Tippgasse wegen Abschaltkriterium GRA/ACC";
CM_ SG_ 173 GE_Freig_MMom_Vorhalt "Freigabe für die Anforderung einer Momentenreserve durch das Getriebe über das Signal
MLB: GE_MMom_Vorhalt
MQB/MLBevo: GE_MMom_Vorhalt_02";
CM_ SG_ 173 GE_MMom_Soll_02 "Momenteneingriff an den Motor.
Fordert vom MSG eine kurzfristige Reduzierung oder Anhebung des Moments.
Das Signal ist nur gültig in Kombination mit GE_MMom_Status (bei MQB) bzw. GE_MMom_Status_02 (bei MLBevo).

Achtung:
Einheitenloser Wert! Faktor i";
CM_ SG_ 173 GE_MMom_Status "Qualifiziert 
MLB: GE_MMom_Soll
MQB: GE_MMom_Soll_02";
CM_ SG_ 173 GE_MMom_Status_02 "Das Signal qualifiziert GE_MMom_Soll_02 und gibt an, wie der Wert aus GE_MMom_soll – vorbehaltlich der Umsetzbarkeit aufgrund motorinterner Restriktionen – umgesetzt werden soll.
Werte:
0= kein Eingriff
1=   absoluter reduzierender Eingriff auf Gesamt ";
CM_ SG_ 173 GE_MMom_Vorhalt_02 "Anforderung einer Momentenreserve durch das Getriebe, gilt nur mit Freigabe durch 
GE_Freig_MMom_Vorhalt

Anforderung wird als Absolut-Wert umgesetzt, nicht als Relativ-Wert/Delta zum aktuellen Ist-Moment (d. h. eine Momentenreserve wird eingestellt, w";
CM_ SG_ 173 GE_reserv_Fahrstufe "reserviert, falls künftig Erweiterung von GE_Fahrstufe nötig";
CM_ SG_ 173 GE_Schaltablauf "Das Signal zeigt den aktuellen Status eines Schaltvorgangs.

Bei Signal = 0 liegt kein Schaltvorgang vor.
Bei Signal =2 liegt die Befüllphase der zuschaltenden Kupplung bzw. 
                      die Vorbereitungsphase dazu vor.

Mit den unterschie";
CM_ SG_ 173 GE_Status_Kraftschluss "Zeigt den Ist-Status des Kraftschlusses im Getriebe.
(Anmerkung: meist wird damit der Zustand des Anfahrelements beschrieben, d.h. bei DL/DQ die Kupplung;  bei AQ/AL der Wandler incl. Überbrückungskupplung)
0 = offen, kein Kraftschluss
1 = offen mit Kr";
CM_ SG_ 173 GE_Uefkt "Übertragungsfunktion des Getriebes
Drehzahlverhältnis = Eingangsdrehzahl / Ausgangsdrehzahl

AL: Wandlerverstärkung x Drehzahlverhältnis
VL: Drehzahlverhältnis
DL: Drehzahlverhältnis der aktiven und kraftschluß führenden Welle zum Abtrieb, bei Schalt";
CM_ SG_ 173 GE_Uefkt_unplausibel "Das Signal darf nur im Reku-Manager in Hybrid-Varianten verwendet werden.
Zeigt an, ob die Plausibilisierung Momenten-Verhältnis zu Drehzahl-Verhältnis i.O. ist.
Ein gesetztes Signal meldet eine unplausible GE_Uefkt bzw. GE_Uefkt_02.";
CM_ SG_ 173 GE_Verbot_Ausblendung "Verbot Einspritzausblendung für komfortable Schaltungen";
CM_ SG_ 173 GE_Zielgang "VL-Getriebe:
Signalisiert den Zielgang im manuellen Modus während eines Schaltvorgangs bzw. die momentane simulierte Gangstufe wenn kein Schaltvorgang aktiv ist. In den Fahrprogrammen 'D' und 'S' ist die Übersetzung variabel und somit wird dauerhaft 'Ist";
CM_ SG_ 173 Getriebe_11_BZ "Botschaftszähler
Botschaft asynchron geroutet. Zählerwert kann springen.";
CM_ SG_ 173 Getriebe_11_CRC "Für MLB:
'Berechnung siehe Lastenheft 'Kommunikationsabsicherung für FlexRay und CAN''

Ab MQB und MLBevo:
'Berechnung siehe Lastenheft 'End-to-End Kommunikationsabsicherung''

Endwerte siehe Begleitdokument 'S-PDU Kennungsfolgen'";

CM_ SG_ 968 Freilauf_Charisma_FahrPr "MLBevo: Aktuelles Fahrprogramm des Charisma-Teilnehmers (siehe Systemlastenheft Drive Select)
MQB: Istwert der Kennlinie (siehe Systemlastenheft MQB FPA)";
CM_ SG_ 968 Freilauf_Charisma_Status "Charisma Systemstatus des Charisma-Teilnehmers

Wert 0x3 ist nur für Fahrzeuge ab MQB relevant";
CM_ SG_ 968 GE_amax_moeglich "AL/DL: maximal mögliche Beschleunigung unter Berücksichtigung aller möglichen Gänge.

Eine Reduzierung des maximalen Motormoments durch Efficiency wird in dem Signal berücksichtigt.

VL: maximal mögliche Beschleunigung bei Nenndrehzahl (Efficency wird";
CM_ SG_ 968 GE_Charisma_FahrPr "MLBevo: Aktuelles Fahrprogramm des Charisma-Teilnehmers (siehe Systemlastenheft Drive Select)
MQB: Istwert der Kennlinie (siehe Systemlastenheft MQB FPA)";
CM_ SG_ 968 GE_Charisma_Status "Charisma Systemstatus des Charisma-Teilnehmers

Wert 0x3 ist nur für Fahrzeuge ab MQB relevant";
CM_ SG_ 968 GE_Codierung_MSG "Statusausgabe der Diagnose für Falschverbau. Plausibilisierung der empfangenen Motor- und Getriebevariante mit der erwarteten Motor- und Getriebevarianten.";
CM_ SG_ 968 GE_Freigabe_Info_WFS "WFS-Freigabeinformation";
CM_ SG_ 968 GE_Freigabe_Verfallsinfo_WFS "WFS";
CM_ SG_ 968 GE_LaunchControl "Während einer LaunchControl-Anfahrt sendet das Getriebesteuergerät das Bit LaunchControl aktiv.
Die Bremse wertet dieses Bit aus, um während einer solchen Anfahrt die Regelgrenzen der Schlupfregelung zu erweitern.
Im Motor Nutzung zur Verbesserung des A";
CM_ SG_ 968 GE_LaunchControl_LB "LB launch control status";
CM_ SG_ 968 GE_LFR_Adaption "Qualifiziert das ausgegeben Motorbelastungsmoment (durch GE_Vorsteuermoment) für die Verwendung zur LFR (Leerlauffüllungsregelung) im Moto";
CM_ SG_ 968 GE_OBD_AbsperrVent "Das Getriebesteuergerät führt eine elektrische Diagnose des von ihm angesteuerten Absperrventils für den Öl-Wasser-Wärmetauscher durch und übermittelt das Ergebnis an das MSG (Standard-4Bit-OBD-Status, nicht alle Zustände müssen genutzt werden; so sind z.";
CM_ SG_ 968 GE_OBD_Status "Dieses Bit steuert die MIL-Lampe an (Motorsteuergerät reicht diese Info an Kombi weiter).";
CM_ SG_ 968 GE_Remotestart_Betrieb "Das GSG ist für den Remotestart-Betrieb bereit. Nach Empfang der Motorstartanforderung für RSt-Betrieb durch BCM wird der Fahrzeugmotor gestartet und solange der Motor läuft, bleibt dieses Bit aktiv. Dieses Signal ist nur zur Verwendung durch das BCM zur ";
CM_ SG_ 968 GE_Sperr_Info_WFS "WFS-Sperrinformation";
CM_ SG_ 968 GE_Status_PaddleNeutral "Status Ablauf der Paddle Neutral Funktion";
CM_ SG_ 968 GE_Sumpftemperatur "Getriebesumpftemperatur wird über den Temperatursensor auf der Getriebeplatine ermittelt. Die absolute Sumpftemperatur wird vom Motor empfangen, um entsprechende Kühlleistung für das Getriebe einzustellen.";
CM_ SG_ 968 GE_Zustand_Kuppltemp "Dieses Signal gibt den Temperaturzustand der Kupplung im DQ-Getriebe (z. Zt. DQ2x0, DQ500) an das ACC-System.";

CM_ SG_ 310 HAL_01_CRC "Für MLB:
'Berechnung siehe Lastenheft 'Kommunikationsabsicherung für FlexRay und CAN''

Ab MQB und MLBevo:
'Berechnung siehe Lastenheft 'End-to-End Kommunikationsabsicherung''

Endwerte siehe Begleitdokument 'S-PDU Kennungsfolgen'
";
CM_ SG_ 310 HAL_Charisma_FahrPr "MLBevo: Aktuelles Fahrprogramm des Charisma-Teilnehmers (siehe Systemlastenheft Drive Select)
MQB: Istwert der Kennlinie (siehe Systemlastenheft MQB FPA)";
CM_ SG_ 310 HAL_Charisma_Status "Rückmeldung an den Charisma-Master";
CM_ SG_ 310 HAL_EFP_FahrPr "Aktueller Ist-Zustand der HAL";
CM_ SG_ 310 HAL_Fahrerwunschwinkel_Soll "Zielwinkel (=Fahrerwunschwinkel) am Rad Hinterachslenkung in Grad";
CM_ SG_ 310 HAL_max_Gradient "maximaler Zustellgradient für die Stabilisierungsfunktion mit HAL durch ESP";
CM_ SG_ 310 HAL_QBit_Radwinkel "Wenn Bit gesetzt, dann entspreicht das Signal nicht mehr ASIL-D. (z.B. Ausfall der redundanten Sensorik)";
CM_ SG_ 310 HAL_Radwinkel "Zusätzlich durch die HAL gestellter Radwinkeloffset an der Hinterachse in Grad";
CM_ SG_ 310 HAL_Status "Status der Hinterachslenkung
0: normaler Betrieb 
1: HAL verriegelt (z.B. harter Fehler, nicht kalibriert)
2: Rücknahme der Leistung, Funktion eingeschränkt/Derating aktiv 
3: HAL deaktiviert";
CM_ SG_ 310 HAL_Status_2 "Zustand der Hinterachlenkung in der Smart application";
CM_ SG_ 310 HAL_VZ_Fahrerwunschwinkel_Soll "Soll-Lenkrichtung der HAL";
CM_ SG_ 310 HAL_VZ_Radwinkel "Lenkrichtung der HAL";
CM_ SG_ 310 HAL_Warnungen "Warnmeldungsanforderung von der Hinterachslenkung an das Kombiinstrumnent";
CM_ SG_ 310 HAL_Winkelbegrenzung "Signal liefert die Info über eine aktive Winkelbegrenzung in der HAL aufgrund Bauteilschutz";

CM_ SG_ 1524 AMB_Charisma_FahrPr "MLBevo: Aktuelles Fahrprogramm des Charisma-Teilnehmers (siehe Systemlastenheft Drive Select)
MQB: Istwert der Kennlinie (siehe Systemlastenheft MQB FPA)";
CM_ SG_ 1524 AMB_Charisma_Status "Systemstatus des Charismateilnehmers

Wert 0x3 ist nur für Fahrzeuge ab MQB relevant";
CM_ SG_ 1524 BCM1_DI_Rampe_Innenlicht "Dimmrampe Innenlicht";
CM_ SG_ 1524 BCM1_DI_Rampe_Leselicht "Dimmrampe Leselicht";
CM_ SG_ 1524 BCM1_Innenlicht_gedimmt_H "Steuerung von BCM_Innenlicht_H";
CM_ SG_ 1524 BCM1_Innenlicht_gedimmt_V "Steuerung von BCM_Innenlicht_V";
CM_ SG_ 1524 BCM1_Innenlicht_H "Anforderung Innenlicht hinten";
CM_ SG_ 1524 BCM1_Innenlicht_V "Anforderung Innenlicht vorne";
CM_ SG_ 1524 BCM1_Leselicht_Anf_hl " Leselicht hinten links Anforderung";
CM_ SG_ 1524 BCM1_Leselicht_Anf_hr "Leselicht hinten rechts Anforderung";
CM_ SG_ 1524 BCM1_Leselicht_Anf_vl "Leselicht vorne links Anforderung";
CM_ SG_ 1524 BCM1_Leselicht_Anf_vr "Leselicht vorne rechts Anforderung";
CM_ SG_ 1524 BCM1_Leuchten_Aus "Innenbeleuchtung ausschalten (keine Änderung / ausschalten)";
CM_ SG_ 1524 IL_Bel_BFS_Ausstieg "Einschalten der Ausstiegsleuchten oder Türwarnleuchten in Tür oder im Schweller";
CM_ SG_ 1524 IL_Bel_FS_Ausstieg "Einschalten der Ausstiegsleuchten oder Türwarnleuchten in Tür oder im Schweller";
CM_ SG_ 1524 IL_Bel_HBFS_Ausstieg "Einschalten der Ausstiegsleuchten oder Türwarnleuchten in Tür oder im Schweller";
CM_ SG_ 1524 IL_Bel_HFS_Ausstieg "Einschalten der Ausstiegsleuchten oder Türwarnleuchten in Tür oder im Schweller";
CM_ SG_ 1524 IL_Dimmung_H_Tuerkontur "Dimmung Türkontur hinten (bei Änderung im 30 ms Raster)";
CM_ SG_ 1524 IL_Dimmung_Lautspr "Dimmung Umfeldbeleuchtung an Türaußenseite oder Außenspiegel";
CM_ SG_ 1524 IL_Dimmung_Tuerinnengriff "Dimmung Türinnengriff";
CM_ SG_ 1524 IL_Dimmung_Umfeldbel "Dimmung Umfeldbeleuchtung an Türaußenseite oder Außenspiegel";
CM_ SG_ 1524 IL_Dimmung_V_Tuerkontur "Dimmung Türkontur vorne (bei Änderung im 30 ms Raster)";
CM_ SG_ 1524 IL_Innenlicht_aktiv "Status Innenlicht";
CM_ SG_ 1524 IL_Klemme_30G_aktiv "Synchrones Abschalten";

CM_ SG_ 1838 ISO_AEM_Req_Data "OffBoard Tester Diagnose Request AEM";

CM_ SG_ 1944 ISO_AEM_Resp_Data "OffBoard Tester Diagnose Response AEM";

CM_ SG_ 1892 ISO_AGA_Req_Data "Diagnose Request Aussensoundaktuator";

CM_ SG_ 1998 ISO_AGA_Resp_Data "Diagnose Response Aussensoundaktuator";

CM_ SG_ 1840 ISO_FLA_Req_Data "Diagnose Request Fernlichtassistent";

CM_ SG_ 1946 ISO_FLA_Resp_Data "Diagnose Response Fernlichtassistent";

CM_ SG_ 1795 ISO_Funktionaler_Req_Abgas "Funktionaler Request für abgasrelevante Steuergeraete";

CM_ SG_ 1792 ISO_ALL_01_Req_Data "Funktionaler Request ALL";

CM_ SG_ 2015 ISO_OBD_Funktionaler_Req_Data "Funktionaler Request für OBD relevante Steuergeraete";

CM_ SG_ 1831 ISO_NightVision_Req_Data "Diagnose Request Nightvision Kamera";

CM_ SG_ 1937 ISO_NightVision_Resp_Data "Diagnose Response Nightvision Kamera";

CM_ SG_ 1803 ISO_RDK_Req_Data "OffBoard Tester Diagnose Request RDK";

CM_ SG_ 1909 ISO_RDK_Resp_Data "OffBoard Tester Diagnose Response RDK";

CM_ SG_ 1897 ISO_Rearview_Req_Data "OffBoard Tester Diagnose Request Rearview";

CM_ SG_ 2003 ISO_Rearview_Resp_Data "OffBoard Tester Diagnose Response Rearview";

CM_ SG_ 1834 ISO_SCR_Req_Data "OffBoard Tester Diagnose Request SCR";

CM_ SG_ 1940 ISO_SCR_Resp_Data "OffBoard Tester Diagnose Response SCR";

CM_ SG_ 1820 ISO_Soundaktor_Req_Data "Diagnose Request Soundaktuator innen";

CM_ SG_ 1926 ISO_Soundaktor_Resp_Data "Diagnose Response Soundaktuator innen";

CM_ SG_ 1898 ISO_STH_Req_Data "Diagnose Request Standheizung";

CM_ SG_ 2004 ISO_STH_Resp_Data "OffBoard Tester Diagnose Response STH";

CM_ SG_ 1870 ISO_SWA_Req_Data "Diagnose Request Spurwechselassistent (Master)";

CM_ SG_ 1976 ISO_SWA_Resp_Data "Diagnose Response Spurwechselassistent (Master)";

CM_ SG_ 2549874826 ISOx_SWA_2_Req_Data "Diagnose Request Spurwechselassistent (Slave)";

CM_ SG_ 2550005898 ISOx_SWA_2_Resp_Data "Diagnose Response Spurwechselassistent (Slave)";

CM_ SG_ 497 FBS_Aktivierung_Pilot_Parken "Aktivierung der Funktion pilotiertes Parken";
CM_ SG_ 497 FFB_FDF_Taste "FDF Taste am Funkschluessel";
CM_ SG_ 497 FFB_Joker_Taste "Frei konfigurierbare Taste auf der Funkfernbedienung (für Verdecktaste, UGDO Taste).
";
CM_ SG_ 497 FFB_Park_Taste "Parktaste Funkschluessel";
CM_ SG_ 497 FFB_Remotestart_Taste "Remotestart Taste Funkschluessel";
CM_ SG_ 497 KY_Auf_Taste "Auf-Taste Funkschluessel";
CM_ SG_ 497 KY_Bereich "Schlüsselentfernung für Funktionen Annäherungslicht, automatisches Entriegeln";
CM_ SG_ 497 KY_BT_Entriegelung_Autorisiert "Erkennung / Authorisierung Keyless BT
";
CM_ SG_ 497 KY_BT_Verriegelung_Autorisiert "Authorisierung Verriegelungssensor Keyless BT
";
CM_ SG_ 497 KY_EasyClose_Abbruch "ID-Geber während HD-Zufahrt im Nahbereich EasyClose erkannt";
CM_ SG_ 497 KY_EasyClose_Status "Signal zur LED Ansteuerung im HD-Verriegelungstaster für die Funktion EasyClose.";
CM_ SG_ 497 KY_Front_Entr_Autorisiert "Erkennung / Authorisierung Keyless Front";
CM_ SG_ 497 KY_Front_Verr_Autorisiert "Authorisierung Verriegelungssensor Keyless Front";
CM_ SG_ 497 KY_FT_Entriegelung_Autorisiert "Erkennung / Authorisierung Keyless FT
";
CM_ SG_ 497 KY_FT_Verriegelung_Autorisiert "Authorisierung Verriegelungssensor Keyless FT
";
CM_ SG_ 497 KY_HBFS_Entriegelung_Autorisiert "Erkennung / Authorisierung Keyless HBFS
";
CM_ SG_ 497 KY_HBFS_Verriegelung_Autorisiert "Authorisierung Verriegelungssensor Keyless HBFS


";
CM_ SG_ 497 KY_HD_Auffahrt "Auffahrt HD nach Wiedereintritt ID-Geber in EasyClose Nahbereich";
CM_ SG_ 497 KY_HD_Entriegelung_Autorisiert "Erkennung / Authorisierung Keyless Heck
";
CM_ SG_ 497 KY_HD_Verriegelung_Autorisiert "Autorisierung der Schließanforderung über Verriegelungsinnentaster";
CM_ SG_ 497 KY_HD_Zufahrt "Zufahrt HD nach erfolgreicher Funktion EasyClose";
CM_ SG_ 497 KY_HDF_Taste "HDF Taste am Funkschluessel";
CM_ SG_ 497 KY_HFS_Entriegelung_Autorisiert "Erkennung / Authorisierung Keyless HFS
";
CM_ SG_ 497 KY_HFS_Verriegelung_Autorisiert "Authorisierung Verriegelungssensor Keyless HFS

";
CM_ SG_ 497 KY_IDG_in_Reichweite "Für elektrisch betätigte Türen und Klappen muss für eine Betätigung über Funk eine Reichweitenbegrenzung eingeführt werden. Diese Bit zeigt an, dass sich der Funkschlüssel innerhalb der geforderten Reichweite befindet";
CM_ SG_ 497 KY_LKL_1_Autorisierung "Schlüsselstatus für Anfragen der Ladeklappe 1";
CM_ SG_ 497 KY_LKL_2_Autorisierung "Schlüsselstatus für Anfragen der Ladeklappe 2";
CM_ SG_ 497 KY_Panik_Taste "Panik Taste Funkschluessel";
CM_ SG_ 497 KY_Position "Schlüsselposition für Funktionen Annäherungslicht, automatisches Entriegeln";
CM_ SG_ 497 KY_Schluessel_im_Fzg "Zeigt einen erkannten Schlüssel im Fzg an.";
CM_ SG_ 497 KY_Zu_Taste "Zu-Taste Funkschluessel";
CM_ SG_ 497 KY_ZV_Signatur "Signatur der ZV";
CM_ SG_ 497 Schluesselnr_Personalisierung "Signal gibt die jewels aktuelle Schlüsselnummer für die Personalisierung wieder";

CM_ SG_ 960 BCM_Ausparken_Betrieb "Anforderung zur erneuten Lampenaufprüfung und Anzeige von Warnhinweisen nach einem pilotierten Ausparkvorgang (Trigger: fallende Flanke)";
CM_ SG_ 960 BCM_Remotestart_Betrieb "Zeigt den Status des RemoteStarts an, d.h. KL15_RSt ist aktiviert und der Motorlauf ist im RSt-Betrieb aktiv.";
CM_ SG_ 960 BCM_Remotestart_KL15_Anf "Zeigt den Status der Aktivierung der KL15_RST durch das BCM an.";
CM_ SG_ 960 BCM_Remotestart_MO_Start "Nachdem das BCM die Remotestart MSG Freigabe sicher erkannt hat, fordert das BCM wiederum über dieses Signal vom MSG einen Motorstart durchzuführen.";
CM_ SG_ 960 Klemmen_Status_01_BZ "4bit Botschaftszaehler; wird in jeder Sendebotschaft inkrementiert";
CM_ SG_ 960 Klemmen_Status_01_CRC "Für MLB:
'Berechnung siehe Lastenheft 'Kommunikationsabsicherung für FlexRay und CAN''

Ab MQB und MLBevo:
'Berechnung siehe Lastenheft 'End-to-End Kommunikationsabsicherung''

Endwerte siehe Begleitdokument 'S-PDU Kennungsfolgen'";
CM_ SG_ 960 KST_Fahrerhinweis_1 "Signalisierung Fahrerhinweis 1 der Klemmensteuerung an das Kombi";
CM_ SG_ 960 KST_Fahrerhinweis_2 "Signalisierung Fahrerhinweis 2 der Klemmensteuerung an das Kombi";
CM_ SG_ 960 KST_Fahrerhinweis_4 "Signalisierung Fahrerhinweis 4 der Klemmensteuerung an das Kombi";
CM_ SG_ 960 KST_Fahrerhinweis_5 "Anzeigesignal für RemoteStart";
CM_ SG_ 960 KST_Fahrerhinweis_6 "Signal aktiviert die Kombi-Anzeigeinstrumente (Drehzahl, Tankinhalt, Kühlmitteltemperatur) während aktiviertem RemoteStart-Betrieb";
CM_ SG_ 960 KST_Warn_P1_ZST_def "Kombi Prio Warnung Klemmensteuerung 
Zündschloß defekt, Service aufsuchen!";
CM_ SG_ 960 KST_Warn_P2_ZST_def "Kombi Prio Warnung Klemmensteuerung
Zündschloß defekt!
";
CM_ SG_ 960 RSt_Fahrerhinweise "Über das Signal fordert das BCM Fahrerhinweise im Kombi für die Funktion RemoteStart an.";
CM_ SG_ 960 ZAS_Kl_15 "Klemme 15: Zuendung (SW-Kl.15)
";
CM_ SG_ 960 ZAS_Kl_50_Startanforderung "Klemme 50: Startwunsch Fahrer
";
CM_ SG_ 960 ZAS_Kl_Infotainment "Separate Klemmeninformation für das Infotainment. Signal entspricht im wesentlichen einer Klemme S Information, kann aber über einen Vor - bzw. Nachlauf zu Klemme S verfügen. 
Ein konkreter Anwendungsfall für einen Nachlauf ist die Abschaltung der Klemme";
CM_ SG_ 960 ZAS_Kl_S "Klemme S: S-Kontakt (Schluessel steckt)
";
CM_ SG_ 960 ZAS_Kl_X "Klemme 75
";
BA_DEF_REL_ BU_SG_REL_  "GenSigTimeoutTime" INT 0 65535;
BA_DEF_ BO_  "DiagRequest" ENUM "No", "Yes";
BA_DEF_ BO_  "DiagResponse" ENUM "No", "Yes";
BA_DEF_ BO_  "DiagState" ENUM "No", "Yes";
BA_DEF_ BO_  "GenMsgChkConstant" HEX 0 4095;
BA_DEF_ BO_  "GenMsgCycleTime" INT 0 65535;
BA_DEF_ BO_  "GenMsgCycleTimeFast" INT 0 65535;
BA_DEF_ BO_  "GenMsgDelayTime" INT 0 100000;
BA_DEF_ BO_  "GenMsgILSupport" ENUM "No", "Yes";
BA_DEF_ BO_  "GenMsgNrOfRepetition" INT 0 100;
BA_DEF_ BO_  "GenMsgPDUConstants" STRING;
BA_DEF_ BO_  "GenMsgSendType" ENUM "Cyclic", "not_used", "not_used", "not_used", "not_used", "not_used", "not_used", "IfActive", "NoMsgSendType";
BA_DEF_ BO_  "GenMsgStartDelayTime" INT 0 100000;
BA_DEF_ BO_  "NmMessage" ENUM "No", "Yes";
BA_DEF_ BO_  "NmhMessage" ENUM "No", "Yes";
BA_DEF_ BO_  "MsgType" ENUM "Application", "NM ", "NMH", "TP2.0", "ISO-TP ", "BAP", "EID", "KS", "XCP_PRE_CONFIGURED", "XCP_RUNTIME_CONFIGURED";
BA_DEF_ BO_  "VAGTP20_API" HEX 0 255;
BA_DEF_ BO_  "VAGTP20_DynConnection" ENUM "No", "Yes";
BA_DEF_ BO_  "VAGTP20_DynSetup" ENUM "No", "Yes";
BA_DEF_ BO_  "VAGTP20_StatConnection" ENUM "No", "Yes";
BA_DEF_ SG_  "GenSigActiveRepetitions" INT -2147483648 2147483647;
BA_DEF_ SG_  "GenSigInactiveValue" INT -2147483648 2147483647;
BA_DEF_ SG_  "GenSigSendType" ENUM "Cyclic", "OnWrite", "OnWriteWithRepetition", "OnChange", "OnChangeWithRepetition", "IfActive", "IfActiveWithRepetition", "NoSigSendType", "OnChangeAndIfActive", "OnChangeAndIfActiveWithRepetition";
BA_DEF_ SG_  "GenSigStartValue" INT -2147483648 2147483647;
BA_DEF_ SG_  "NWM-WakeupAllowed" ENUM "No", "Yes";
BA_DEF_ SG_  "GenSigFuncType" ENUM "NoFunction", "MsgCounter", "CRC-8", "XOR", "XOR-2", "DatedBit", "SW-Kl15", "CHK", "Constant", "Protocol", "CRC-8-SAE_J1850", "CRC-32", "DataLength", "DataID", "MsgCounter16", "SOK-Signatur", "Cluster";
BA_DEF_ SG_  "GenSigSwitchedByIgnition" ENUM "No", "Yes";
BA_DEF_ SG_  "Fehlerwert" HEX 0 2147483647;
BA_DEF_ SG_  "GenSigMissingSourceValue" HEX 0 2147483647;
BA_DEF_DEF_REL_  "GenSigTimeoutTime" 0;
BA_DEF_DEF_  "DiagRequest" "No";
BA_DEF_DEF_  "DiagResponse" "No";
BA_DEF_DEF_  "DiagState" "No";
BA_DEF_DEF_  "GenMsgChkConstant" 0;
BA_DEF_DEF_  "GenMsgCycleTime" 0;
BA_DEF_DEF_  "GenMsgCycleTimeFast" 0;
BA_DEF_DEF_  "GenMsgDelayTime" 0;
BA_DEF_DEF_  "GenMsgILSupport" "No";
BA_DEF_DEF_  "GenMsgNrOfRepetition" 0;
BA_DEF_DEF_  "GenMsgPDUConstants" "";
BA_DEF_DEF_  "GenMsgSendType" "NoMsgSendType";
BA_DEF_DEF_  "GenMsgStartDelayTime" 0;
BA_DEF_DEF_  "NmMessage" "No";
BA_DEF_DEF_  "NmhMessage" "No";
BA_DEF_DEF_  "MsgType" "Application";
BA_DEF_DEF_  "VAGTP20_API" 0;
BA_DEF_DEF_  "VAGTP20_DynConnection" "No";
BA_DEF_DEF_  "VAGTP20_DynSetup" "No";
BA_DEF_DEF_  "VAGTP20_StatConnection" "No";
BA_DEF_DEF_  "GenSigActiveRepetitions" 0;
BA_DEF_DEF_  "GenSigInactiveValue" 0;
BA_DEF_DEF_  "GenSigSendType" "NoSigSendType";
BA_DEF_DEF_  "GenSigStartValue" 0;
BA_DEF_DEF_  "NWM-WakeupAllowed" "No";
BA_DEF_DEF_  "GenSigFuncType" "NoFunction";
BA_DEF_DEF_  "GenSigSwitchedByIgnition" "Yes";
BA_DEF_DEF_  "Fehlerwert" 0;
BA_DEF_DEF_  "GenSigMissingSourceValue" 0;
BA_ "GenMsgCycleTime" BO_ 2527679980 500;
BA_ "GenMsgDelayTime" BO_ 2527679980 50;
BA_ "GenMsgILSupport" BO_ 2527679980 1;
BA_ "GenMsgSendType" BO_ 2527679980 0;
BA_ "GenMsgCycleTime" BO_ 996 1000;
BA_ "GenMsgDelayTime" BO_ 996 50;
BA_ "GenMsgILSupport" BO_ 996 1;
BA_ "GenMsgSendType" BO_ 996 0;
BA_ "GenMsgStartDelayTime" BO_ 996 80;
BA_ "GenMsgCycleTime" BO_ 1603 1000;
BA_ "GenMsgDelayTime" BO_ 1603 100;
BA_ "GenMsgILSupport" BO_ 1603 1;
BA_ "GenMsgSendType" BO_ 1603 0;
BA_ "GenMsgChkConstant" BO_ 259 2;
BA_ "GenMsgCycleTime" BO_ 259 20;
BA_ "GenMsgILSupport" BO_ 259 1;
BA_ "GenMsgPDUConstants" BO_ 259 "0x02,0x02,0x02,0x02,0x02,0x02,0x02,0x02,0x02,0x02,0x02,0x02,0x02,0x02,0x02,0x02";
BA_ "GenMsgSendType" BO_ 259 0;
BA_ "GenMsgChkConstant" BO_ 278 172;
BA_ "GenMsgCycleTime" BO_ 278 20;
BA_ "GenMsgILSupport" BO_ 278 1;
BA_ "GenMsgPDUConstants" BO_ 278 "0xac,0xac,0xac,0xac,0xac,0xac,0xac,0xac,0xac,0xac,0xac,0xac,0xac,0xac,0xac,0xac";
BA_ "GenMsgSendType" BO_ 278 0;
BA_ "GenMsgCycleTime" BO_ 418 200;
BA_ "GenMsgDelayTime" BO_ 418 20;
BA_ "GenMsgILSupport" BO_ 418 1;
BA_ "GenMsgPDUConstants" BO_ 418 "0xcb,0x47,0xd7,0xd2,0x56,0x3e,0x20,0xea,0x6e,0x6d,0x8c,0x1b,0xdf,0x49,0xaa,0xab";
BA_ "GenMsgSendType" BO_ 418 0;
BA_ "GenMsgStartDelayTime" BO_ 418 20;
BA_ "GenMsgCycleTime" BO_ 1629 160;
BA_ "GenMsgILSupport" BO_ 1629 1;
BA_ "GenMsgPDUConstants" BO_ 1629 "0xac,0xb3,0xab,0xeb,0x7a,0xe1,0x3b,0xf7,0x73,0xba,0x7c,0x9e,0x06,0x5f,0x02,0xd9";
BA_ "GenMsgSendType" BO_ 1629 0;
BA_ "GenMsgCycleTime" BO_ 253 20;
BA_ "GenMsgILSupport" BO_ 253 1;
BA_ "GenMsgPDUConstants" BO_ 253 "0xb4,0xef,0xf8,0x49,0x1e,0xe5,0xc2,0xc0,0x97,0x19,0x3c,0xc9,0xf1,0x98,0xd6,0x61";
BA_ "GenMsgSendType" BO_ 253 0;
BA_ "GenMsgCycleTime" BO_ 427 200;
BA_ "GenMsgDelayTime" BO_ 427 20;
BA_ "GenMsgILSupport" BO_ 427 1;
BA_ "GenMsgPDUConstants" BO_ 427 "0x13,0x21,0x9b,0x6a,0x9a,0x62,0xd4,0x65,0x18,0xf1,0xab,0x16,0x32,0x89,0xe7,0x26";
BA_ "GenMsgSendType" BO_ 427 0;
BA_ "GenMsgChkConstant" BO_ 264 9;
BA_ "GenMsgCycleTime" BO_ 264 1000;
BA_ "GenMsgILSupport" BO_ 264 1;
BA_ "GenMsgPDUConstants" BO_ 264 "0x09,0x09,0x09,0x09,0x09,0x09,0x09,0x09,0x09,0x09,0x09,0x09,0x09,0x09,0x09,0x09";
BA_ "GenMsgSendType" BO_ 264 0;
BA_ "GenMsgCycleTime" BO_ 2463978619 960;
BA_ "GenMsgCycleTimeFast" BO_ 2463978619 40;
BA_ "GenMsgDelayTime" BO_ 2463978619 40;
BA_ "GenMsgILSupport" BO_ 2463978619 1;
BA_ "GenMsgNrOfRepetition" BO_ 2463978619 10;
BA_ "GenMsgSendType" BO_ 2463978619 0;
BA_ "GenMsgCycleTime" BO_ 1332 200;
BA_ "GenMsgDelayTime" BO_ 1332 40;
BA_ "GenMsgILSupport" BO_ 1332 1;
BA_ "GenMsgSendType" BO_ 1332 0;
BA_ "GenMsgCycleTime" BO_ 1605 1000;
BA_ "GenMsgDelayTime" BO_ 1605 20;
BA_ "GenMsgILSupport" BO_ 1605 1;
BA_ "GenMsgSendType" BO_ 1605 0;
BA_ "GenMsgCycleTime" BO_ 2589283684 960;
BA_ "GenMsgDelayTime" BO_ 2589283684 320;
BA_ "GenMsgILSupport" BO_ 2589283684 1;
BA_ "GenMsgSendType" BO_ 2589283684 0;
BA_ "GenMsgStartDelayTime" BO_ 2589283684 320;
BA_ "MsgType" BO_ 2549875594 4;
BA_ "MsgType" BO_ 2550006666 4;
BA_ "MsgType" BO_ 2549875534 4;
BA_ "MsgType" BO_ 2550006606 4;
BA_ "GenMsgCycleTime" BO_ 173 100;
BA_ "GenMsgDelayTime" BO_ 173 10;
BA_ "GenMsgILSupport" BO_ 173 1;
BA_ "GenMsgPDUConstants" BO_ 173 "0x3f,0x69,0x39,0xdc,0x94,0xf9,0x14,0x64,0xd8,0x6a,0x34,0xce,0xa2,0x55,0xb5,0x2c";
BA_ "GenMsgSendType" BO_ 173 0;
BA_ "GenMsgStartDelayTime" BO_ 173 5;
BA_ "GenMsgCycleTime" BO_ 968 80;
BA_ "GenMsgDelayTime" BO_ 968 20;
BA_ "GenMsgILSupport" BO_ 968 1;
BA_ "GenMsgSendType" BO_ 968 0;
BA_ "GenMsgChkConstant" BO_ 310 55;
BA_ "GenMsgCycleTime" BO_ 310 10;
BA_ "GenMsgILSupport" BO_ 310 1;
BA_ "GenMsgPDUConstants" BO_ 310 "0x37,0x37,0x37,0x37,0x37,0x37,0x37,0x37,0x37,0x37,0x37,0x37,0x37,0x37,0x37,0x37";
BA_ "GenMsgSendType" BO_ 310 0;
BA_ "GenMsgCycleTime" BO_ 1524 500;
BA_ "GenMsgDelayTime" BO_ 1524 50;
BA_ "GenMsgILSupport" BO_ 1524 1;
BA_ "GenMsgSendType" BO_ 1524 0;
BA_ "DiagRequest" BO_ 1838 1;
BA_ "MsgType" BO_ 1838 4;
BA_ "DiagResponse" BO_ 1944 1;
BA_ "MsgType" BO_ 1944 4;
BA_ "DiagRequest" BO_ 1892 1;
BA_ "MsgType" BO_ 1892 4;
BA_ "DiagResponse" BO_ 1998 1;
BA_ "MsgType" BO_ 1998 4;
BA_ "DiagRequest" BO_ 1840 1;
BA_ "MsgType" BO_ 1840 4;
BA_ "DiagResponse" BO_ 1946 1;
BA_ "MsgType" BO_ 1946 4;
BA_ "DiagState" BO_ 1795 1;
BA_ "MsgType" BO_ 1795 4;
BA_ "DiagState" BO_ 1792 1;
BA_ "MsgType" BO_ 1792 4;
BA_ "DiagState" BO_ 2015 1;
BA_ "MsgType" BO_ 2015 4;
BA_ "DiagRequest" BO_ 1831 1;
BA_ "MsgType" BO_ 1831 4;
BA_ "DiagResponse" BO_ 1937 1;
BA_ "MsgType" BO_ 1937 4;
BA_ "DiagRequest" BO_ 1803 1;
BA_ "MsgType" BO_ 1803 4;
BA_ "DiagResponse" BO_ 1909 1;
BA_ "MsgType" BO_ 1909 4;
BA_ "DiagRequest" BO_ 1897 1;
BA_ "MsgType" BO_ 1897 4;
BA_ "DiagResponse" BO_ 2003 1;
BA_ "MsgType" BO_ 2003 4;
BA_ "DiagRequest" BO_ 1834 1;
BA_ "MsgType" BO_ 1834 4;
BA_ "DiagResponse" BO_ 1940 1;
BA_ "MsgType" BO_ 1940 4;
BA_ "DiagRequest" BO_ 1820 1;
BA_ "MsgType" BO_ 1820 4;
BA_ "DiagResponse" BO_ 1926 1;
BA_ "MsgType" BO_ 1926 4;
BA_ "DiagRequest" BO_ 1898 1;
BA_ "MsgType" BO_ 1898 4;
BA_ "DiagResponse" BO_ 2004 1;
BA_ "MsgType" BO_ 2004 4;
BA_ "DiagRequest" BO_ 1870 1;
BA_ "MsgType" BO_ 1870 4;
BA_ "DiagResponse" BO_ 1976 1;
BA_ "MsgType" BO_ 1976 4;
BA_ "DiagRequest" BO_ 2549874826 1;
BA_ "MsgType" BO_ 2549874826 4;
BA_ "DiagResponse" BO_ 2550005898 1;
BA_ "MsgType" BO_ 2550005898 4;
BA_ "GenMsgCycleTime" BO_ 497 500;
BA_ "GenMsgCycleTimeFast" BO_ 497 40;
BA_ "GenMsgDelayTime" BO_ 497 20;
BA_ "GenMsgILSupport" BO_ 497 1;
BA_ "GenMsgNrOfRepetition" BO_ 497 7;
BA_ "GenMsgSendType" BO_ 497 0;
BA_ "GenMsgChkConstant" BO_ 960 195;
BA_ "GenMsgCycleTime" BO_ 960 100;
BA_ "GenMsgDelayTime" BO_ 960 10;
BA_ "GenMsgILSupport" BO_ 960 1;
BA_ "GenMsgPDUConstants" BO_ 960 "0xc3,0xc3,0xc3,0xc3,0xc3,0xc3,0xc3,0xc3,0xc3,0xc3,0xc3,0xc3,0xc3,0xc3,0xc3,0xc3";
BA_ "GenMsgSendType" BO_ 960 0;
BA_ "GenSigSendType" SG_ 2527679980 bCall_active 3;
BA_ "GenSigSwitchedByIgnition" SG_ 2527679980 bCall_active 0;
BA_ "GenSigSendType" SG_ 2527679980 eCall_Funktionsstatus 3;
BA_ "GenSigSwitchedByIgnition" SG_ 2527679980 eCall_Funktionsstatus 0;
BA_ "GenSigSendType" SG_ 2527679980 eCall_Funktionsstatus_02 3;
BA_ "GenSigStartValue" SG_ 2527679980 eCall_Funktionsstatus_02 7;
BA_ "GenSigSwitchedByIgnition" SG_ 2527679980 eCall_Funktionsstatus_02 0;
BA_ "GenSigSendType" SG_ 2527679980 eCall_Mute_Anf 3;
BA_ "GenSigSwitchedByIgnition" SG_ 2527679980 eCall_Mute_Anf 0;
BA_ "GenSigSendType" SG_ 2527679980 eCall_Statuslicht_Farbe1 3;
BA_ "GenSigSwitchedByIgnition" SG_ 2527679980 eCall_Statuslicht_Farbe1 0;
BA_ "GenSigSendType" SG_ 2527679980 eCall_Statuslicht_Farbe2 3;
BA_ "GenSigSwitchedByIgnition" SG_ 2527679980 eCall_Statuslicht_Farbe2 0;
BA_ "GenSigSendType" SG_ 2527679980 eCall_Subscription 3;
BA_ "GenSigSwitchedByIgnition" SG_ 2527679980 eCall_Subscription 0;
BA_ "GenSigSendType" SG_ 996 EFF_Einsparhinweis 3;
BA_ "GenSigSwitchedByIgnition" SG_ 996 EFF_Einsparhinweis 0;
BA_ "GenSigSendType" SG_ 996 EFF_Verbrauch_STH 3;
BA_ "GenSigSwitchedByIgnition" SG_ 996 EFF_Verbrauch_STH 0;
BA_ "Fehlerwert" SG_ 996 EFF_Verbrauch_STH 127;
BA_ "GenSigSendType" SG_ 996 EFF_Verbraucher_Balken 3;
BA_ "GenSigStartValue" SG_ 996 EFF_Verbraucher_Balken 510;
BA_ "GenSigSwitchedByIgnition" SG_ 996 EFF_Verbraucher_Balken 0;
BA_ "Fehlerwert" SG_ 996 EFF_Verbraucher_Balken 511;
BA_ "GenSigSendType" SG_ 996 EFF_Verbraucher_Pos_1 3;
BA_ "GenSigSwitchedByIgnition" SG_ 996 EFF_Verbraucher_Pos_1 0;
BA_ "GenSigSendType" SG_ 996 EFF_Verbraucher_Pos_2 3;
BA_ "GenSigSwitchedByIgnition" SG_ 996 EFF_Verbraucher_Pos_2 0;
BA_ "GenSigSendType" SG_ 996 EFF_Verbraucher_Pos_3 3;
BA_ "GenSigSwitchedByIgnition" SG_ 996 EFF_Verbraucher_Pos_3 0;
BA_ "GenSigSendType" SG_ 996 MKE_FAS 3;
BA_ "GenSigSwitchedByIgnition" SG_ 996 MKE_FAS 0;
BA_ "GenSigSendType" SG_ 996 MKE_FAS_Fkt_Status 0;
BA_ "GenSigSwitchedByIgnition" SG_ 996 MKE_FAS_Fkt_Status 0;
BA_ "Fehlerwert" SG_ 996 MKE_FAS_Fkt_Status 3;
BA_ "GenSigSendType" SG_ 996 MKE_Fehlercode 3;
BA_ "GenSigSwitchedByIgnition" SG_ 996 MKE_Fehlercode 0;
BA_ "GenSigSendType" SG_ 996 MKE_Stufe 0;
BA_ "GenSigSwitchedByIgnition" SG_ 996 MKE_Stufe 0;
BA_ "GenSigSendType" SG_ 996 MKE_Texte 0;
BA_ "GenSigSwitchedByIgnition" SG_ 996 MKE_Texte 0;
BA_ "GenSigSendType" SG_ 1603 KBI_Einheit_Datum 3;
BA_ "GenSigSwitchedByIgnition" SG_ 1603 KBI_Einheit_Datum 0;
BA_ "GenSigSendType" SG_ 1603 KBI_Einheit_Druck 3;
BA_ "GenSigSwitchedByIgnition" SG_ 1603 KBI_Einheit_Druck 0;
BA_ "GenSigSendType" SG_ 1603 KBI_Einheit_Masse 3;
BA_ "GenSigSwitchedByIgnition" SG_ 1603 KBI_Einheit_Masse 0;
BA_ "GenSigSendType" SG_ 1603 KBI_Einheit_Sprache 3;
BA_ "GenSigSwitchedByIgnition" SG_ 1603 KBI_Einheit_Sprache 0;
BA_ "GenSigSendType" SG_ 1603 KBI_Einheit_Streckenanz 3;
BA_ "GenSigSwitchedByIgnition" SG_ 1603 KBI_Einheit_Streckenanz 0;
BA_ "GenSigSendType" SG_ 1603 KBI_Einheit_Temp 3;
BA_ "GenSigSwitchedByIgnition" SG_ 1603 KBI_Einheit_Temp 0;
BA_ "GenSigSendType" SG_ 1603 KBI_Einheit_Uhrzeit 3;
BA_ "GenSigSwitchedByIgnition" SG_ 1603 KBI_Einheit_Uhrzeit 0;
BA_ "GenSigSendType" SG_ 1603 KBI_Einheit_Verbrauch 3;
BA_ "GenSigSwitchedByIgnition" SG_ 1603 KBI_Einheit_Verbrauch 0;
BA_ "GenSigSendType" SG_ 1603 KBI_Einheit_Verbrauch_elektr 3;
BA_ "GenSigSwitchedByIgnition" SG_ 1603 KBI_Einheit_Verbrauch_elektr 0;
BA_ "GenSigSendType" SG_ 1603 KBI_Einheit_Verbrauch_Gas 3;
BA_ "GenSigSwitchedByIgnition" SG_ 1603 KBI_Einheit_Verbrauch_Gas 0;
BA_ "GenSigSendType" SG_ 1603 KBI_Einheit_Volumen 3;
BA_ "GenSigSwitchedByIgnition" SG_ 1603 KBI_Einheit_Volumen 0;
BA_ "GenSigSendType" SG_ 1603 KBI_MFA_v_Einheit_02 3;
BA_ "GenSigSwitchedByIgnition" SG_ 1603 KBI_MFA_v_Einheit_02 0;
BA_ "GenSigSendType" SG_ 259 ESP_03_BZ 0;
BA_ "GenSigFuncType" SG_ 259 ESP_03_BZ 1;
BA_ "GenSigSwitchedByIgnition" SG_ 259 ESP_03_BZ 0;
BA_ "GenSigSendType" SG_ 259 ESP_03_CRC 0;
BA_ "GenSigFuncType" SG_ 259 ESP_03_CRC 2;
BA_ "GenSigSwitchedByIgnition" SG_ 259 ESP_03_CRC 0;
BA_ "GenSigSendType" SG_ 259 ESP_HL_FR 0;
BA_ "GenSigSwitchedByIgnition" SG_ 259 ESP_HL_FR 0;
BA_ "GenSigSendType" SG_ 259 ESP_HL_Radgeschw 0;
BA_ "GenSigStartValue" SG_ 259 ESP_HL_Radgeschw 4094;
BA_ "GenSigSwitchedByIgnition" SG_ 259 ESP_HL_Radgeschw 0;
BA_ "Fehlerwert" SG_ 259 ESP_HL_Radgeschw 4095;
BA_ "GenSigSendType" SG_ 259 ESP_HR_FR 0;
BA_ "GenSigSwitchedByIgnition" SG_ 259 ESP_HR_FR 0;
BA_ "GenSigSendType" SG_ 259 ESP_HR_Radgeschw 0;
BA_ "GenSigStartValue" SG_ 259 ESP_HR_Radgeschw 4094;
BA_ "GenSigSwitchedByIgnition" SG_ 259 ESP_HR_Radgeschw 0;
BA_ "Fehlerwert" SG_ 259 ESP_HR_Radgeschw 4095;
BA_ "GenSigSendType" SG_ 259 ESP_VL_FR 0;
BA_ "GenSigSwitchedByIgnition" SG_ 259 ESP_VL_FR 0;
BA_ "GenSigSendType" SG_ 259 ESP_VL_Radgeschw 0;
BA_ "GenSigStartValue" SG_ 259 ESP_VL_Radgeschw 4094;
BA_ "GenSigSwitchedByIgnition" SG_ 259 ESP_VL_Radgeschw 0;
BA_ "Fehlerwert" SG_ 259 ESP_VL_Radgeschw 4095;
BA_ "GenSigSendType" SG_ 259 ESP_VR_FR 0;
BA_ "GenSigSwitchedByIgnition" SG_ 259 ESP_VR_FR 0;
BA_ "GenSigSendType" SG_ 259 ESP_VR_Radgeschw 0;
BA_ "GenSigStartValue" SG_ 259 ESP_VR_Radgeschw 4094;
BA_ "GenSigSwitchedByIgnition" SG_ 259 ESP_VR_Radgeschw 0;
BA_ "Fehlerwert" SG_ 259 ESP_VR_Radgeschw 4095;
BA_ "GenSigSendType" SG_ 278 ESP_10_BZ 0;
BA_ "GenSigFuncType" SG_ 278 ESP_10_BZ 1;
BA_ "GenSigSwitchedByIgnition" SG_ 278 ESP_10_BZ 0;
BA_ "GenSigSendType" SG_ 278 ESP_10_CRC 0;
BA_ "GenSigFuncType" SG_ 278 ESP_10_CRC 2;
BA_ "GenSigSwitchedByIgnition" SG_ 278 ESP_10_CRC 0;
BA_ "GenSigSendType" SG_ 278 ESP_HL_Fahrtrichtung 0;
BA_ "GenSigStartValue" SG_ 278 ESP_HL_Fahrtrichtung 2;
BA_ "GenSigSwitchedByIgnition" SG_ 278 ESP_HL_Fahrtrichtung 0;
BA_ "GenSigSendType" SG_ 278 ESP_HR_Fahrtrichtung 0;
BA_ "GenSigStartValue" SG_ 278 ESP_HR_Fahrtrichtung 2;
BA_ "GenSigSwitchedByIgnition" SG_ 278 ESP_HR_Fahrtrichtung 0;
BA_ "GenSigSendType" SG_ 278 ESP_QBit_Wegimpuls_HL 0;
BA_ "GenSigStartValue" SG_ 278 ESP_QBit_Wegimpuls_HL 1;
BA_ "GenSigSwitchedByIgnition" SG_ 278 ESP_QBit_Wegimpuls_HL 0;
BA_ "GenSigSendType" SG_ 278 ESP_QBit_Wegimpuls_HR 0;
BA_ "GenSigStartValue" SG_ 278 ESP_QBit_Wegimpuls_HR 1;
BA_ "GenSigSwitchedByIgnition" SG_ 278 ESP_QBit_Wegimpuls_HR 0;
BA_ "GenSigSendType" SG_ 278 ESP_QBit_Wegimpuls_VL 0;
BA_ "GenSigStartValue" SG_ 278 ESP_QBit_Wegimpuls_VL 1;
BA_ "GenSigSwitchedByIgnition" SG_ 278 ESP_QBit_Wegimpuls_VL 0;
BA_ "GenSigSendType" SG_ 278 ESP_QBit_Wegimpuls_VR 0;
BA_ "GenSigStartValue" SG_ 278 ESP_QBit_Wegimpuls_VR 1;
BA_ "GenSigSwitchedByIgnition" SG_ 278 ESP_QBit_Wegimpuls_VR 0;
BA_ "GenSigSendType" SG_ 278 ESP_VL_Fahrtrichtung 0;
BA_ "GenSigStartValue" SG_ 278 ESP_VL_Fahrtrichtung 2;
BA_ "GenSigSwitchedByIgnition" SG_ 278 ESP_VL_Fahrtrichtung 0;
BA_ "GenSigSendType" SG_ 278 ESP_VR_Fahrtrichtung 0;
BA_ "GenSigStartValue" SG_ 278 ESP_VR_Fahrtrichtung 2;
BA_ "GenSigSwitchedByIgnition" SG_ 278 ESP_VR_Fahrtrichtung 0;
BA_ "GenSigSendType" SG_ 278 ESP_Wegimpuls_HL 0;
BA_ "GenSigStartValue" SG_ 278 ESP_Wegimpuls_HL 1021;
BA_ "GenSigSwitchedByIgnition" SG_ 278 ESP_Wegimpuls_HL 0;
BA_ "Fehlerwert" SG_ 278 ESP_Wegimpuls_HL 1023;
BA_ "GenSigSendType" SG_ 278 ESP_Wegimpuls_HR 0;
BA_ "GenSigStartValue" SG_ 278 ESP_Wegimpuls_HR 1021;
BA_ "GenSigSwitchedByIgnition" SG_ 278 ESP_Wegimpuls_HR 0;
BA_ "Fehlerwert" SG_ 278 ESP_Wegimpuls_HR 1023;
BA_ "GenSigSendType" SG_ 278 ESP_Wegimpuls_VL 0;
BA_ "GenSigStartValue" SG_ 278 ESP_Wegimpuls_VL 1021;
BA_ "GenSigSwitchedByIgnition" SG_ 278 ESP_Wegimpuls_VL 0;
BA_ "Fehlerwert" SG_ 278 ESP_Wegimpuls_VL 1023;
BA_ "GenSigSendType" SG_ 278 ESP_Wegimpuls_VR 0;
BA_ "GenSigStartValue" SG_ 278 ESP_Wegimpuls_VR 1021;
BA_ "GenSigSwitchedByIgnition" SG_ 278 ESP_Wegimpuls_VR 0;
BA_ "Fehlerwert" SG_ 278 ESP_Wegimpuls_VR 1023;
BA_ "GenSigSendType" SG_ 418 ESP_15_BZ 0;
BA_ "GenSigFuncType" SG_ 418 ESP_15_BZ 1;
BA_ "GenSigSwitchedByIgnition" SG_ 418 ESP_15_BZ 0;
BA_ "GenSigSendType" SG_ 418 ESP_15_CRC 0;
BA_ "GenSigFuncType" SG_ 418 ESP_15_CRC 2;
BA_ "GenSigSwitchedByIgnition" SG_ 418 ESP_15_CRC 0;
BA_ "GenSigSendType" SG_ 418 ESP_Haltemoment 0;
BA_ "GenSigStartValue" SG_ 418 ESP_Haltemoment 1022;
BA_ "GenSigSwitchedByIgnition" SG_ 418 ESP_Haltemoment 0;
BA_ "Fehlerwert" SG_ 418 ESP_Haltemoment 1023;
BA_ "GenSigSendType" SG_ 418 ESP_Index_Haltemoment 0;
BA_ "GenSigSwitchedByIgnition" SG_ 418 ESP_Index_Haltemoment 0;
BA_ "GenSigSendType" SG_ 418 HMS_aktives_System 3;
BA_ "GenSigSwitchedByIgnition" SG_ 418 HMS_aktives_System 0;
BA_ "GenSigSendType" SG_ 418 HMS_Anforderung_GE 0;
BA_ "GenSigSwitchedByIgnition" SG_ 418 HMS_Anforderung_GE 0;
BA_ "GenSigSendType" SG_ 418 HMS_Fehlerstatus 3;
BA_ "GenSigSwitchedByIgnition" SG_ 418 HMS_Fehlerstatus 0;
BA_ "GenSigSendType" SG_ 418 HMS_halten_nicht_verfuegbar 0;
BA_ "GenSigSwitchedByIgnition" SG_ 418 HMS_halten_nicht_verfuegbar 0;
BA_ "GenSigSendType" SG_ 418 HMS_Konsistenz_ACC 0;
BA_ "GenSigSwitchedByIgnition" SG_ 418 HMS_Konsistenz_ACC 0;
BA_ "GenSigSendType" SG_ 418 HMS_Konsistenz_GE 0;
BA_ "GenSigSwitchedByIgnition" SG_ 418 HMS_Konsistenz_GE 0;
BA_ "GenSigSendType" SG_ 418 HMS_Konsistenz_HVLM 3;
BA_ "GenSigSwitchedByIgnition" SG_ 418 HMS_Konsistenz_HVLM 0;
BA_ "GenSigSendType" SG_ 418 HMS_Konsistenz_IPA 3;
BA_ "GenSigSwitchedByIgnition" SG_ 418 HMS_Konsistenz_IPA 0;
BA_ "GenSigSendType" SG_ 418 HMS_Konsistenz_MO 0;
BA_ "GenSigSwitchedByIgnition" SG_ 418 HMS_Konsistenz_MO 0;
BA_ "GenSigSendType" SG_ 418 HMS_Konsistenz_STA 0;
BA_ "GenSigSwitchedByIgnition" SG_ 418 HMS_Konsistenz_STA 0;
BA_ "GenSigSendType" SG_ 418 HMS_Notstopp_Status 0;
BA_ "GenSigSwitchedByIgnition" SG_ 418 HMS_Notstopp_Status 0;
BA_ "GenSigSendType" SG_ 418 HMS_P_beibehalten_GE 0;
BA_ "GenSigStartValue" SG_ 418 HMS_P_beibehalten_GE 2;
BA_ "GenSigSwitchedByIgnition" SG_ 418 HMS_P_beibehalten_GE 0;
BA_ "Fehlerwert" SG_ 418 HMS_P_beibehalten_GE 3;
BA_ "GenSigSendType" SG_ 418 HMS_parken_nicht_verfuegbar 0;
BA_ "GenSigSwitchedByIgnition" SG_ 418 HMS_parken_nicht_verfuegbar 0;
BA_ "GenSigSendType" SG_ 418 HMS_Stillstand 3;
BA_ "GenSigStartValue" SG_ 418 HMS_Stillstand 6;
BA_ "GenSigSwitchedByIgnition" SG_ 418 HMS_Stillstand 0;
BA_ "Fehlerwert" SG_ 418 HMS_Stillstand 7;
BA_ "GenSigSendType" SG_ 418 HMS_Systemstatus 3;
BA_ "GenSigStartValue" SG_ 418 HMS_Systemstatus 14;
BA_ "GenSigSwitchedByIgnition" SG_ 418 HMS_Systemstatus 0;
BA_ "Fehlerwert" SG_ 418 HMS_Systemstatus 15;
BA_ "GenSigSendType" SG_ 418 NL_PRIM_STP_01_Status 0;
BA_ "GenSigSwitchedByIgnition" SG_ 418 NL_PRIM_STP_01_Status 0;
BA_ "GenSigSendType" SG_ 418 VMM_Warnblinken 3;
BA_ "GenSigSwitchedByIgnition" SG_ 418 VMM_Warnblinken 0;
BA_ "GenSigSendType" SG_ 418 VZM_Status 0;
BA_ "GenSigSwitchedByIgnition" SG_ 418 VZM_Status 0;
BA_ "Fehlerwert" SG_ 418 VZM_Status 4;
BA_ "GenSigSendType" SG_ 1629 BR_QBit_Reifenumfang 0;
BA_ "GenSigStartValue" SG_ 1629 BR_QBit_Reifenumfang 1;
BA_ "GenSigSwitchedByIgnition" SG_ 1629 BR_QBit_Reifenumfang 0;
BA_ "GenSigSendType" SG_ 1629 BR_Reifenumfang 0;
BA_ "GenSigSwitchedByIgnition" SG_ 1629 BR_Reifenumfang 0;
BA_ "GenSigSendType" SG_ 1629 BR_Systemart 0;
BA_ "GenSigFuncType" SG_ 1629 BR_Systemart 8;
BA_ "GenSigSwitchedByIgnition" SG_ 1629 BR_Systemart 0;
BA_ "GenSigSendType" SG_ 1629 ESP_20_BZ 0;
BA_ "GenSigFuncType" SG_ 1629 ESP_20_BZ 1;
BA_ "GenSigSwitchedByIgnition" SG_ 1629 ESP_20_BZ 0;
BA_ "GenSigSendType" SG_ 1629 ESP_20_CRC 0;
BA_ "GenSigFuncType" SG_ 1629 ESP_20_CRC 2;
BA_ "GenSigSwitchedByIgnition" SG_ 1629 ESP_20_CRC 0;
BA_ "GenSigSendType" SG_ 1629 ESP_Charisma_FahrPr 0;
BA_ "GenSigSwitchedByIgnition" SG_ 1629 ESP_Charisma_FahrPr 0;
BA_ "GenSigSendType" SG_ 1629 ESP_Charisma_Status 0;
BA_ "GenSigSwitchedByIgnition" SG_ 1629 ESP_Charisma_Status 0;
BA_ "GenSigSendType" SG_ 1629 ESP_Dachrelingsensor 0;
BA_ "GenSigSwitchedByIgnition" SG_ 1629 ESP_Dachrelingsensor 0;
BA_ "Fehlerwert" SG_ 1629 ESP_Dachrelingsensor 3;
BA_ "GenSigSendType" SG_ 1629 ESP_SpannungsAnf_02 0;
BA_ "GenSigSwitchedByIgnition" SG_ 1629 ESP_SpannungsAnf_02 0;
BA_ "GenSigSendType" SG_ 1629 ESP_Stoppverbot_Anz_01 0;
BA_ "GenSigSwitchedByIgnition" SG_ 1629 ESP_Stoppverbot_Anz_01 0;
BA_ "GenSigSendType" SG_ 1629 ESP_Stoppverbot_Anz_02 0;
BA_ "GenSigSwitchedByIgnition" SG_ 1629 ESP_Stoppverbot_Anz_02 0;
BA_ "GenSigSendType" SG_ 1629 ESP_Stoppverbot_Anz_03 0;
BA_ "GenSigSwitchedByIgnition" SG_ 1629 ESP_Stoppverbot_Anz_03 0;
BA_ "GenSigSendType" SG_ 1629 ESP_Stoppverbot_Anz_04 0;
BA_ "GenSigSwitchedByIgnition" SG_ 1629 ESP_Stoppverbot_Anz_04 0;
BA_ "GenSigSendType" SG_ 1629 ESP_Stoppverbot_Anz_05 0;
BA_ "GenSigSwitchedByIgnition" SG_ 1629 ESP_Stoppverbot_Anz_05 0;
BA_ "GenSigSendType" SG_ 1629 ESP_Stoppverbot_Anz_06 0;
BA_ "GenSigSwitchedByIgnition" SG_ 1629 ESP_Stoppverbot_Anz_06 0;
BA_ "GenSigSendType" SG_ 1629 ESP_Stoppverbot_Anz_07 0;
BA_ "GenSigSwitchedByIgnition" SG_ 1629 ESP_Stoppverbot_Anz_07 0;
BA_ "GenSigSendType" SG_ 1629 ESP_Stoppverbot_Anz_08 0;
BA_ "GenSigSwitchedByIgnition" SG_ 1629 ESP_Stoppverbot_Anz_08 0;
BA_ "GenSigSendType" SG_ 1629 ESP_Stoppverbot_Anz_Std 0;
BA_ "GenSigSwitchedByIgnition" SG_ 1629 ESP_Stoppverbot_Anz_Std 0;
BA_ "GenSigSendType" SG_ 1629 ESP_Wiederstart_Anz_01 0;
BA_ "GenSigSwitchedByIgnition" SG_ 1629 ESP_Wiederstart_Anz_01 0;
BA_ "GenSigSendType" SG_ 1629 ESP_Wiederstart_Anz_02 0;
BA_ "GenSigSwitchedByIgnition" SG_ 1629 ESP_Wiederstart_Anz_02 0;
BA_ "GenSigSendType" SG_ 1629 ESP_Wiederstart_Anz_03 0;
BA_ "GenSigSwitchedByIgnition" SG_ 1629 ESP_Wiederstart_Anz_03 0;
BA_ "GenSigSendType" SG_ 1629 ESP_Wiederstart_Anz_04 0;
BA_ "GenSigSwitchedByIgnition" SG_ 1629 ESP_Wiederstart_Anz_04 0;
BA_ "GenSigSendType" SG_ 1629 ESP_Zaehnezahl 0;
BA_ "GenSigFuncType" SG_ 1629 ESP_Zaehnezahl 8;
BA_ "GenSigSwitchedByIgnition" SG_ 1629 ESP_Zaehnezahl 0;
BA_ "GenSigSendType" SG_ 1629 HDC_Charisma_FahrPr 0;
BA_ "GenSigSwitchedByIgnition" SG_ 1629 HDC_Charisma_FahrPr 0;
BA_ "GenSigSendType" SG_ 1629 HDC_Charisma_Status 0;
BA_ "GenSigSwitchedByIgnition" SG_ 1629 HDC_Charisma_Status 0;
BA_ "GenSigSendType" SG_ 253 ABS_Bremsung 0;
BA_ "GenSigSwitchedByIgnition" SG_ 253 ABS_Bremsung 0;
BA_ "GenSigSendType" SG_ 253 ASR_Anf 0;
BA_ "GenSigSwitchedByIgnition" SG_ 253 ASR_Anf 0;
BA_ "GenSigSendType" SG_ 253 ASR_Schalteingriff 0;
BA_ "GenSigSwitchedByIgnition" SG_ 253 ASR_Schalteingriff 0;
BA_ "GenSigSendType" SG_ 253 ASR_Tastung_passiv 0;
BA_ "GenSigSwitchedByIgnition" SG_ 253 ASR_Tastung_passiv 0;
BA_ "GenSigSendType" SG_ 253 BR_Eingriffsmoment 0;
BA_ "GenSigStartValue" SG_ 253 BR_Eingriffsmoment 1022;
BA_ "GenSigSwitchedByIgnition" SG_ 253 BR_Eingriffsmoment 0;
BA_ "Fehlerwert" SG_ 253 BR_Eingriffsmoment 1023;
BA_ "GenSigSendType" SG_ 253 EBV_Eingriff 0;
BA_ "GenSigSwitchedByIgnition" SG_ 253 EBV_Eingriff 0;
BA_ "GenSigSendType" SG_ 253 EDS_Eingriff 0;
BA_ "GenSigSwitchedByIgnition" SG_ 253 EDS_Eingriff 0;
BA_ "GenSigSendType" SG_ 253 ESC_Neutralschaltung 0;
BA_ "GenSigSwitchedByIgnition" SG_ 253 ESC_Neutralschaltung 0;
BA_ "GenSigSendType" SG_ 253 ESC_v_Signal_Qualifier_High_Low 0;
BA_ "GenSigStartValue" SG_ 253 ESC_v_Signal_Qualifier_High_Low 6;
BA_ "GenSigSwitchedByIgnition" SG_ 253 ESC_v_Signal_Qualifier_High_Low 0;
BA_ "Fehlerwert" SG_ 253 ESC_v_Signal_Qualifier_High_Low 7;
BA_ "GenSigSendType" SG_ 253 ESP_21_BZ 0;
BA_ "GenSigFuncType" SG_ 253 ESP_21_BZ 1;
BA_ "GenSigSwitchedByIgnition" SG_ 253 ESP_21_BZ 0;
BA_ "GenSigSendType" SG_ 253 ESP_21_CRC 0;
BA_ "GenSigFuncType" SG_ 253 ESP_21_CRC 2;
BA_ "GenSigSwitchedByIgnition" SG_ 253 ESP_21_CRC 0;
BA_ "GenSigSendType" SG_ 253 ESP_ASP 0;
BA_ "GenSigSwitchedByIgnition" SG_ 253 ESP_ASP 0;
BA_ "GenSigSendType" SG_ 253 ESP_Diagnose 0;
BA_ "GenSigSwitchedByIgnition" SG_ 253 ESP_Diagnose 0;
BA_ "GenSigSendType" SG_ 253 ESP_Eingriff 0;
BA_ "GenSigSwitchedByIgnition" SG_ 253 ESP_Eingriff 0;
BA_ "GenSigSendType" SG_ 253 ESP_QBit_v_Signal 0;
BA_ "GenSigStartValue" SG_ 253 ESP_QBit_v_Signal 1;
BA_ "GenSigSwitchedByIgnition" SG_ 253 ESP_QBit_v_Signal 0;
BA_ "GenSigSendType" SG_ 253 ESP_Systemstatus 0;
BA_ "GenSigSwitchedByIgnition" SG_ 253 ESP_Systemstatus 0;
BA_ "GenSigSendType" SG_ 253 ESP_Tastung_passiv 0;
BA_ "GenSigSwitchedByIgnition" SG_ 253 ESP_Tastung_passiv 0;
BA_ "GenSigSendType" SG_ 253 ESP_v_Signal 0;
BA_ "GenSigStartValue" SG_ 253 ESP_v_Signal 65534;
BA_ "GenSigSwitchedByIgnition" SG_ 253 ESP_v_Signal 0;
BA_ "Fehlerwert" SG_ 253 ESP_v_Signal 65535;
BA_ "GenSigMissingSourceValue" SG_ 253 ESP_v_Signal 65534;
BA_ "GenSigSendType" SG_ 253 ESP_Vorsteuerung 0;
BA_ "GenSigSwitchedByIgnition" SG_ 253 ESP_Vorsteuerung 0;
BA_ "GenSigSendType" SG_ 253 MSR_Anf 0;
BA_ "GenSigSwitchedByIgnition" SG_ 253 MSR_Anf 0;
BA_ "GenSigSendType" SG_ 253 MSR_verfuegbar 0;
BA_ "GenSigStartValue" SG_ 253 MSR_verfuegbar 1;
BA_ "GenSigSwitchedByIgnition" SG_ 253 MSR_verfuegbar 0;
BA_ "GenSigSendType" SG_ 253 OBD_QBit_Schlechtweg 0;
BA_ "GenSigStartValue" SG_ 253 OBD_QBit_Schlechtweg 1;
BA_ "GenSigSwitchedByIgnition" SG_ 253 OBD_QBit_Schlechtweg 0;
BA_ "GenSigSendType" SG_ 253 OBD_Schlechtweg 0;
BA_ "GenSigSwitchedByIgnition" SG_ 253 OBD_Schlechtweg 0;
BA_ "GenSigSendType" SG_ 427 ESC_AHW_aktiv 3;
BA_ "GenSigSwitchedByIgnition" SG_ 427 ESC_AHW_aktiv 0;
BA_ "GenSigSendType" SG_ 427 ESC_AHW_nicht_verfuegbar 3;
BA_ "GenSigSwitchedByIgnition" SG_ 427 ESC_AHW_nicht_verfuegbar 0;
BA_ "GenSigSendType" SG_ 427 ESC_ANB_CM_aktiv 0;
BA_ "GenSigSwitchedByIgnition" SG_ 427 ESC_ANB_CM_aktiv 0;
BA_ "GenSigSendType" SG_ 427 ESC_ANB_CM_nicht_verfuegbar 0;
BA_ "GenSigSwitchedByIgnition" SG_ 427 ESC_ANB_CM_nicht_verfuegbar 0;
BA_ "GenSigSendType" SG_ 427 ESC_Bremslicht_unplausibel 3;
BA_ "GenSigSwitchedByIgnition" SG_ 427 ESC_Bremslicht_unplausibel 0;
BA_ "GenSigSendType" SG_ 427 ESC_Fahrer_Bremsdruck_bestimmend 0;
BA_ "GenSigSwitchedByIgnition" SG_ 427 ESC_Fahrer_Bremsdruck_bestimmend 0;
BA_ "GenSigSendType" SG_ 427 ESC_HBA_aktiv 3;
BA_ "GenSigSwitchedByIgnition" SG_ 427 ESC_HBA_aktiv 0;
BA_ "GenSigSendType" SG_ 427 ESC_HBA_nicht_verfuegbar 3;
BA_ "GenSigSwitchedByIgnition" SG_ 427 ESC_HBA_nicht_verfuegbar 0;
BA_ "GenSigSendType" SG_ 427 ESC_Konsistenz_ACC 0;
BA_ "GenSigSwitchedByIgnition" SG_ 427 ESC_Konsistenz_ACC 0;
BA_ "GenSigSendType" SG_ 427 ESC_Konsistenz_AGW 0;
BA_ "GenSigSwitchedByIgnition" SG_ 427 ESC_Konsistenz_AGW 0;
BA_ "GenSigSendType" SG_ 427 ESC_Konsistenz_ARA 3;
BA_ "GenSigSwitchedByIgnition" SG_ 427 ESC_Konsistenz_ARA 0;
BA_ "GenSigSendType" SG_ 427 ESC_Konsistenz_AWA 0;
BA_ "GenSigSwitchedByIgnition" SG_ 427 ESC_Konsistenz_AWA 0;
BA_ "GenSigSendType" SG_ 427 ESC_Konsistenz_AWV 0;
BA_ "GenSigSwitchedByIgnition" SG_ 427 ESC_Konsistenz_AWV 0;
BA_ "GenSigSendType" SG_ 427 ESC_Konsistenz_BFF 0;
BA_ "GenSigSwitchedByIgnition" SG_ 427 ESC_Konsistenz_BFF 0;
BA_ "GenSigSendType" SG_ 427 ESC_Konsistenz_EA 0;
BA_ "GenSigSwitchedByIgnition" SG_ 427 ESC_Konsistenz_EA 0;
BA_ "GenSigSendType" SG_ 427 ESC_Konsistenz_FAS_VK 0;
BA_ "GenSigSwitchedByIgnition" SG_ 427 ESC_Konsistenz_FAS_VK 0;
BA_ "GenSigSendType" SG_ 427 ESC_Konsistenz_FCW 0;
BA_ "GenSigSwitchedByIgnition" SG_ 427 ESC_Konsistenz_FCW 0;
BA_ "GenSigSendType" SG_ 427 ESC_Konsistenz_IPA 0;
BA_ "GenSigSwitchedByIgnition" SG_ 427 ESC_Konsistenz_IPA 0;
BA_ "GenSigSendType" SG_ 427 ESC_Konsistenz_KAS 0;
BA_ "GenSigSwitchedByIgnition" SG_ 427 ESC_Konsistenz_KAS 0;
BA_ "GenSigSendType" SG_ 427 ESC_Konsistenz_MKB 0;
BA_ "GenSigSwitchedByIgnition" SG_ 427 ESC_Konsistenz_MKB 0;
BA_ "GenSigSendType" SG_ 427 ESC_Konsistenz_NV 3;
BA_ "GenSigSwitchedByIgnition" SG_ 427 ESC_Konsistenz_NV 0;
BA_ "GenSigSendType" SG_ 427 ESC_Konsistenz_PCF 0;
BA_ "GenSigSwitchedByIgnition" SG_ 427 ESC_Konsistenz_PCF 0;
BA_ "GenSigSendType" SG_ 427 ESC_Konsistenz_RCTA 3;
BA_ "GenSigSwitchedByIgnition" SG_ 427 ESC_Konsistenz_RCTA 0;
BA_ "GenSigSendType" SG_ 427 ESC_Konsistenz_STA 0;
BA_ "GenSigSwitchedByIgnition" SG_ 427 ESC_Konsistenz_STA 0;
BA_ "GenSigSendType" SG_ 427 ESC_Konsistenz_TSK 0;
BA_ "GenSigSwitchedByIgnition" SG_ 427 ESC_Konsistenz_TSK 0;
BA_ "GenSigSendType" SG_ 427 ESC_Konsistenz_vFGS 0;
BA_ "GenSigSwitchedByIgnition" SG_ 427 ESC_Konsistenz_vFGS 0;
BA_ "GenSigSendType" SG_ 427 ESC_Prefill_aktiv 3;
BA_ "GenSigSwitchedByIgnition" SG_ 427 ESC_Prefill_aktiv 0;
BA_ "GenSigSendType" SG_ 427 ESC_Prefill_nicht_verfuegbar 3;
BA_ "GenSigSwitchedByIgnition" SG_ 427 ESC_Prefill_nicht_verfuegbar 0;
BA_ "GenSigSendType" SG_ 427 ESC_Pumpenanlauf_aktiv 0;
BA_ "GenSigSwitchedByIgnition" SG_ 427 ESC_Pumpenanlauf_aktiv 0;
BA_ "GenSigSendType" SG_ 427 ESC_TSK_SRBM_Anf 0;
BA_ "GenSigSwitchedByIgnition" SG_ 427 ESC_TSK_SRBM_Anf 0;
BA_ "GenSigSendType" SG_ 427 ESC_TSK_SRBM_nicht_verfuegbar 0;
BA_ "GenSigSwitchedByIgnition" SG_ 427 ESC_TSK_SRBM_nicht_verfuegbar 0;
BA_ "GenSigSendType" SG_ 427 ESC_Verz_ASIL_Verfuegbarkeit 0;
BA_ "GenSigSwitchedByIgnition" SG_ 427 ESC_Verz_ASIL_Verfuegbarkeit 0;
BA_ "GenSigSendType" SG_ 427 ESC_Verz_Begrenzung 0;
BA_ "GenSigSwitchedByIgnition" SG_ 427 ESC_Verz_Begrenzung 0;
BA_ "GenSigSendType" SG_ 427 ESC_Verz_Reg_aktiv 3;
BA_ "GenSigSwitchedByIgnition" SG_ 427 ESC_Verz_Reg_aktiv 0;
BA_ "GenSigSendType" SG_ 427 ESC_Verz_Reg_nicht_verfuegbar 0;
BA_ "GenSigSwitchedByIgnition" SG_ 427 ESC_Verz_Reg_nicht_verfuegbar 0;
BA_ "GenSigSendType" SG_ 427 ESC_Verz_Reg_TB_nicht_verfuegbar 0;
BA_ "GenSigSwitchedByIgnition" SG_ 427 ESC_Verz_Reg_TB_nicht_verfuegbar 0;
BA_ "GenSigSendType" SG_ 427 ESC_Verz_Reg_ZB_nicht_verfuegbar 0;
BA_ "GenSigSwitchedByIgnition" SG_ 427 ESC_Verz_Reg_ZB_nicht_verfuegbar 0;
BA_ "GenSigSendType" SG_ 427 ESC_Warnruck_aktiv 3;
BA_ "GenSigSwitchedByIgnition" SG_ 427 ESC_Warnruck_aktiv 0;
BA_ "GenSigSendType" SG_ 427 ESC_Warnruck_nicht_verfuegbar 3;
BA_ "GenSigSwitchedByIgnition" SG_ 427 ESC_Warnruck_nicht_verfuegbar 0;
BA_ "GenSigSendType" SG_ 427 ESP_33_BZ 0;
BA_ "GenSigFuncType" SG_ 427 ESP_33_BZ 1;
BA_ "GenSigSwitchedByIgnition" SG_ 427 ESP_33_BZ 0;
BA_ "GenSigSendType" SG_ 427 ESP_33_CRC 0;
BA_ "GenSigFuncType" SG_ 427 ESP_33_CRC 2;
BA_ "GenSigSwitchedByIgnition" SG_ 427 ESP_33_CRC 0;
BA_ "GenSigSendType" SG_ 264 EFP_Anf_Bremsenkuehlung 0;
BA_ "GenSigSwitchedByIgnition" SG_ 264 EFP_Anf_Bremsenkuehlung 0;
BA_ "GenSigSendType" SG_ 264 EFP_Reibwert_dyn 0;
BA_ "GenSigStartValue" SG_ 264 EFP_Reibwert_dyn 62;
BA_ "GenSigSwitchedByIgnition" SG_ 264 EFP_Reibwert_dyn 0;
BA_ "Fehlerwert" SG_ 264 EFP_Reibwert_dyn 63;
BA_ "GenSigSendType" SG_ 264 FA_Fahrbahnunebenheit 0;
BA_ "GenSigStartValue" SG_ 264 FA_Fahrbahnunebenheit 254;
BA_ "GenSigSwitchedByIgnition" SG_ 264 FA_Fahrbahnunebenheit 0;
BA_ "Fehlerwert" SG_ 264 FA_Fahrbahnunebenheit 255;
BA_ "GenSigSendType" SG_ 264 FA_Hoehenwert_HL_00 0;
BA_ "GenSigStartValue" SG_ 264 FA_Hoehenwert_HL_00 254;
BA_ "Fehlerwert" SG_ 264 FA_Hoehenwert_HL_00 255;
BA_ "GenSigSendType" SG_ 264 FA_Hoehenwert_HR_00 0;
BA_ "GenSigStartValue" SG_ 264 FA_Hoehenwert_HR_00 254;
BA_ "Fehlerwert" SG_ 264 FA_Hoehenwert_HR_00 255;
BA_ "GenSigSendType" SG_ 264 FA_Hoehenwert_VL_00 0;
BA_ "GenSigStartValue" SG_ 264 FA_Hoehenwert_VL_00 254;
BA_ "Fehlerwert" SG_ 264 FA_Hoehenwert_VL_00 255;
BA_ "GenSigSendType" SG_ 264 FA_Hoehenwert_VR_00 0;
BA_ "GenSigStartValue" SG_ 264 FA_Hoehenwert_VR_00 254;
BA_ "Fehlerwert" SG_ 264 FA_Hoehenwert_VR_00 255;
BA_ "GenSigSendType" SG_ 264 FA_Hoehenwerte_kalibriert 0;
BA_ "GenSigSendType" SG_ 264 Fahrwerk_01_BZ 0;
BA_ "GenSigFuncType" SG_ 264 Fahrwerk_01_BZ 1;
BA_ "GenSigSendType" SG_ 264 Fahrwerk_01_CRC 0;
BA_ "GenSigFuncType" SG_ 264 Fahrwerk_01_CRC 2;
BA_ "GenSigSendType" SG_ 2463978619 FAS_SollStatus_Fkt_AbstWarn_LRR 3;
BA_ "GenSigSwitchedByIgnition" SG_ 2463978619 FAS_SollStatus_Fkt_AbstWarn_LRR 0;
BA_ "GenSigSendType" SG_ 2463978619 FAS_SollStatus_Fkt_AbstWarn_MV 3;
BA_ "GenSigSwitchedByIgnition" SG_ 2463978619 FAS_SollStatus_Fkt_AbstWarn_MV 0;
BA_ "GenSigSendType" SG_ 2463978619 FAS_SollStatus_Fkt_ASW 3;
BA_ "GenSigSwitchedByIgnition" SG_ 2463978619 FAS_SollStatus_Fkt_ASW 0;
BA_ "GenSigSendType" SG_ 2463978619 FAS_SollStatus_Fkt_LGI 3;
BA_ "GenSigSwitchedByIgnition" SG_ 2463978619 FAS_SollStatus_Fkt_LGI 0;
BA_ "GenSigSendType" SG_ 2463978619 FAS_SollStatus_Fkt_MKE 3;
BA_ "GenSigSwitchedByIgnition" SG_ 2463978619 FAS_SollStatus_Fkt_MKE 0;
BA_ "GenSigActiveRepetitions" SG_ 2463978619 FAS_SollStatus_Fkt_NV 10;
BA_ "GenSigSendType" SG_ 2463978619 FAS_SollStatus_Fkt_NV 4;
BA_ "GenSigSwitchedByIgnition" SG_ 2463978619 FAS_SollStatus_Fkt_NV 0;
BA_ "GenSigSendType" SG_ 2463978619 FAS_SollStatus_Fkt_PreCrash 3;
BA_ "GenSigSwitchedByIgnition" SG_ 2463978619 FAS_SollStatus_Fkt_PreCrash 0;
BA_ "GenSigSendType" SG_ 2463978619 FAS_SollStatus_Fkt_STP 3;
BA_ "GenSigSwitchedByIgnition" SG_ 2463978619 FAS_SollStatus_Fkt_STP 0;
BA_ "GenSigSendType" SG_ 2463978619 FAS_SollStatus_Fkt_SWA 3;
BA_ "GenSigSwitchedByIgnition" SG_ 2463978619 FAS_SollStatus_Fkt_SWA 0;
BA_ "GenSigSendType" SG_ 1332 FCWO_Charisma_FahrPr 0;
BA_ "GenSigSendType" SG_ 1332 FCWO_Charisma_Status 0;
BA_ "GenSigSendType" SG_ 1332 FCWO_LED_Leiste 3;
BA_ "GenSigSendType" SG_ 1332 FCWO_Texte 3;
BA_ "GenSigSendType" SG_ 1332 FCWO_Warnlevel 3;
BA_ "GenSigSendType" SG_ 1332 FCWO_Warnung 3;
BA_ "GenSigSwitchedByIgnition" SG_ 1332 FCWO_Warnung 0;
BA_ "GenSigSendType" SG_ 1332 FCWP_Charisma_FahrPr 0;
BA_ "GenSigSendType" SG_ 1332 FCWP_Charisma_Status 0;
BA_ "GenSigSendType" SG_ 1332 FCWP_LED_Leiste 3;
BA_ "GenSigSendType" SG_ 1332 FCWP_Texte 3;
BA_ "GenSigSendType" SG_ 1332 FCWP_Warnlevel 3;
BA_ "GenSigSendType" SG_ 1332 FCWP_Warnung 3;
BA_ "GenSigSwitchedByIgnition" SG_ 1332 FCWP_Warnung 0;
BA_ "GenSigSendType" SG_ 1605 FLA_Abblendursache 3;
BA_ "Fehlerwert" SG_ 1605 FLA_Abblendursache 255;
BA_ "GenSigSendType" SG_ 1605 FLA_aktiv 3;
BA_ "GenSigSendType" SG_ 1605 FLA_Aufblenden 3;
BA_ "GenSigSendType" SG_ 1605 FLA_Fernlicht_PWM 3;
BA_ "GenSigStartValue" SG_ 1605 FLA_Fernlicht_PWM 100;
BA_ "Fehlerwert" SG_ 1605 FLA_Fernlicht_PWM 127;
BA_ "GenSigSendType" SG_ 1605 FLA_ISP_defekt 3;
BA_ "GenSigSendType" SG_ 1605 FLA_SAE_Mode 3;
BA_ "GenSigSendType" SG_ 1605 FLA_Sensor_blockiert 3;
BA_ "GenSigSendType" SG_ 1605 ISP_Dimmung_ASP_02 3;
BA_ "GenSigSendType" SG_ 1605 ISP_EC_aktiv 3;
BA_ "GenSigStartValue" SG_ 1605 ISP_EC_aktiv 1;
BA_ "GenSigSendType" SG_ 1605 ISP_EC_Lichtwert_hinten 3;
BA_ "GenSigStartValue" SG_ 1605 ISP_EC_Lichtwert_hinten 62;
BA_ "Fehlerwert" SG_ 1605 ISP_EC_Lichtwert_hinten 63;
BA_ "GenSigSendType" SG_ 1605 ISP_EC_Lichtwert_vorne 3;
BA_ "GenSigStartValue" SG_ 1605 ISP_EC_Lichtwert_vorne 62;
BA_ "Fehlerwert" SG_ 1605 ISP_EC_Lichtwert_vorne 63;
BA_ "GenSigSendType" SG_ 1605 ISP_Himmelsrichtung 3;
BA_ "GenSigStartValue" SG_ 1605 ISP_Himmelsrichtung 30;
BA_ "Fehlerwert" SG_ 1605 ISP_Himmelsrichtung 31;
BA_ "GenSigSendType" SG_ 1605 ISP_Kompass_aktiv 3;
BA_ "GenSigStartValue" SG_ 1605 ISP_Kompass_aktiv 1;
BA_ "GenSigSendType" SG_ 1605 ISP_Taste_betaetigt 3;
BA_ "GenSigSendType" SG_ 2589283684 FoD_Anz_Funktionsabschaltung 3;
BA_ "GenSigSwitchedByIgnition" SG_ 2589283684 FoD_Anz_Funktionsabschaltung 0;
BA_ "GenSigSendType" SG_ 2589283684 FoD_Transmission_Info 3;
BA_ "GenSigSwitchedByIgnition" SG_ 2589283684 FoD_Transmission_Info 0;
BA_ "GenSigSendType" SG_ 2549875594 FoD_SWA_2_Req_Data 3;
BA_ "GenSigFuncType" SG_ 2549875594 FoD_SWA_2_Req_Data 9;
BA_ "GenSigSwitchedByIgnition" SG_ 2549875594 FoD_SWA_2_Req_Data 0;
BA_ "GenSigSendType" SG_ 2550006666 FoD_SWA_2_Resp_Data 3;
BA_ "GenSigFuncType" SG_ 2550006666 FoD_SWA_2_Resp_Data 9;
BA_ "GenSigSwitchedByIgnition" SG_ 2550006666 FoD_SWA_2_Resp_Data 0;
BA_ "GenSigSendType" SG_ 2549875534 FoD_SWA_Req_Data 3;
BA_ "GenSigFuncType" SG_ 2549875534 FoD_SWA_Req_Data 9;
BA_ "GenSigSwitchedByIgnition" SG_ 2549875534 FoD_SWA_Req_Data 0;
BA_ "GenSigSendType" SG_ 2550006606 FoD_SWA_Resp_Data 3;
BA_ "GenSigFuncType" SG_ 2550006606 FoD_SWA_Resp_Data 9;
BA_ "GenSigSwitchedByIgnition" SG_ 2550006606 FoD_SWA_Resp_Data 0;
BA_ "GenSigSendType" SG_ 173 GE_Fahrstufe 3;
BA_ "GenSigStartValue" SG_ 173 GE_Fahrstufe 1;
BA_ "GenSigSwitchedByIgnition" SG_ 173 GE_Fahrstufe 0;
BA_ "Fehlerwert" SG_ 173 GE_Fahrstufe 15;
BA_ "GenSigSendType" SG_ 173 GE_Freig_MMom_Vorhalt 0;
BA_ "GenSigSwitchedByIgnition" SG_ 173 GE_Freig_MMom_Vorhalt 0;
BA_ "GenSigSendType" SG_ 173 GE_MMom_Soll_02 0;
BA_ "GenSigStartValue" SG_ 173 GE_MMom_Soll_02 1022;
BA_ "GenSigSwitchedByIgnition" SG_ 173 GE_MMom_Soll_02 0;
BA_ "Fehlerwert" SG_ 173 GE_MMom_Soll_02 1023;
BA_ "GenSigSendType" SG_ 173 GE_MMom_Status 0;
BA_ "GenSigSwitchedByIgnition" SG_ 173 GE_MMom_Status 0;
BA_ "GenSigSendType" SG_ 173 GE_MMom_Status_02 0;
BA_ "GenSigSwitchedByIgnition" SG_ 173 GE_MMom_Status_02 0;
BA_ "GenSigSendType" SG_ 173 GE_MMom_Vorhalt_02 0;
BA_ "GenSigStartValue" SG_ 173 GE_MMom_Vorhalt_02 1022;
BA_ "GenSigSwitchedByIgnition" SG_ 173 GE_MMom_Vorhalt_02 0;
BA_ "Fehlerwert" SG_ 173 GE_MMom_Vorhalt_02 1023;
BA_ "GenSigSendType" SG_ 173 GE_reserv_Fahrstufe 0;
BA_ "GenSigSwitchedByIgnition" SG_ 173 GE_reserv_Fahrstufe 0;
BA_ "GenSigSendType" SG_ 173 GE_Schaltablauf 0;
BA_ "GenSigSwitchedByIgnition" SG_ 173 GE_Schaltablauf 0;
BA_ "GenSigSendType" SG_ 173 GE_Status_Kraftschluss 0;
BA_ "GenSigSwitchedByIgnition" SG_ 173 GE_Status_Kraftschluss 0;
BA_ "GenSigSendType" SG_ 173 GE_Uefkt 0;
BA_ "GenSigSwitchedByIgnition" SG_ 173 GE_Uefkt 0;
BA_ "Fehlerwert" SG_ 173 GE_Uefkt 1023;
BA_ "GenSigSendType" SG_ 173 GE_Uefkt_unplausibel 0;
BA_ "GenSigSwitchedByIgnition" SG_ 173 GE_Uefkt_unplausibel 0;
BA_ "GenSigSendType" SG_ 173 GE_Verbot_Ausblendung 0;
BA_ "GenSigSwitchedByIgnition" SG_ 173 GE_Verbot_Ausblendung 0;
BA_ "GenSigSendType" SG_ 173 GE_Zielgang 0;
BA_ "GenSigSwitchedByIgnition" SG_ 173 GE_Zielgang 0;
BA_ "Fehlerwert" SG_ 173 GE_Zielgang 15;
BA_ "GenSigSendType" SG_ 173 Getriebe_11_BZ 0;
BA_ "GenSigFuncType" SG_ 173 Getriebe_11_BZ 1;
BA_ "GenSigSwitchedByIgnition" SG_ 173 Getriebe_11_BZ 0;
BA_ "GenSigSendType" SG_ 173 Getriebe_11_CRC 0;
BA_ "GenSigFuncType" SG_ 173 Getriebe_11_CRC 2;
BA_ "GenSigSwitchedByIgnition" SG_ 173 Getriebe_11_CRC 0;
BA_ "GenSigSendType" SG_ 968 Freilauf_Charisma_FahrPr 0;
BA_ "GenSigSwitchedByIgnition" SG_ 968 Freilauf_Charisma_FahrPr 0;
BA_ "GenSigSendType" SG_ 968 Freilauf_Charisma_Status 0;
BA_ "GenSigSwitchedByIgnition" SG_ 968 Freilauf_Charisma_Status 0;
BA_ "GenSigSendType" SG_ 968 GE_amax_moeglich 0;
BA_ "GenSigStartValue" SG_ 968 GE_amax_moeglich 84;
BA_ "GenSigSwitchedByIgnition" SG_ 968 GE_amax_moeglich 0;
BA_ "GenSigSendType" SG_ 968 GE_Charisma_FahrPr 0;
BA_ "GenSigSwitchedByIgnition" SG_ 968 GE_Charisma_FahrPr 0;
BA_ "GenSigSendType" SG_ 968 GE_Charisma_Status 0;
BA_ "GenSigSwitchedByIgnition" SG_ 968 GE_Charisma_Status 0;
BA_ "GenSigSendType" SG_ 968 GE_Codierung_MSG 0;
BA_ "GenSigSwitchedByIgnition" SG_ 968 GE_Codierung_MSG 0;
BA_ "GenSigSendType" SG_ 968 GE_Freigabe_Info_WFS 3;
BA_ "GenSigSwitchedByIgnition" SG_ 968 GE_Freigabe_Info_WFS 0;
BA_ "GenSigSendType" SG_ 968 GE_Freigabe_Verfallsinfo_WFS 0;
BA_ "GenSigSwitchedByIgnition" SG_ 968 GE_Freigabe_Verfallsinfo_WFS 0;
BA_ "GenSigSendType" SG_ 968 GE_Heizwunsch 0;
BA_ "GenSigStartValue" SG_ 968 GE_Heizwunsch 1;
BA_ "GenSigSwitchedByIgnition" SG_ 968 GE_Heizwunsch 0;
BA_ "GenSigSendType" SG_ 968 GE_LaunchControl 0;
BA_ "GenSigSwitchedByIgnition" SG_ 968 GE_LaunchControl 0;
BA_ "GenSigSendType" SG_ 968 GE_LaunchControl_LB 0;
BA_ "GenSigSwitchedByIgnition" SG_ 968 GE_LaunchControl_LB 0;
BA_ "GenSigSendType" SG_ 968 GE_LFR_Adaption 0;
BA_ "GenSigSwitchedByIgnition" SG_ 968 GE_LFR_Adaption 0;
BA_ "GenSigSendType" SG_ 968 GE_OBD_AbsperrVent 0;
BA_ "GenSigSwitchedByIgnition" SG_ 968 GE_OBD_AbsperrVent 0;
BA_ "GenSigSendType" SG_ 968 GE_OBD_Status 0;
BA_ "GenSigSwitchedByIgnition" SG_ 968 GE_OBD_Status 0;
BA_ "GenSigSendType" SG_ 968 GE_Remotestart_Betrieb 0;
BA_ "GenSigSwitchedByIgnition" SG_ 968 GE_Remotestart_Betrieb 0;
BA_ "GenSigSendType" SG_ 968 GE_Sperr_Info_WFS 3;
BA_ "GenSigSwitchedByIgnition" SG_ 968 GE_Sperr_Info_WFS 0;
BA_ "GenSigSendType" SG_ 968 GE_Status_PaddleNeutral 3;
BA_ "GenSigSwitchedByIgnition" SG_ 968 GE_Status_PaddleNeutral 0;
BA_ "GenSigSendType" SG_ 968 GE_Sumpftemperatur 0;
BA_ "GenSigSwitchedByIgnition" SG_ 968 GE_Sumpftemperatur 0;
BA_ "Fehlerwert" SG_ 968 GE_Sumpftemperatur 255;
BA_ "GenSigSendType" SG_ 968 GE_Zustand_Kuppltemp 0;
BA_ "GenSigSwitchedByIgnition" SG_ 968 GE_Zustand_Kuppltemp 0;
BA_ "GenSigSendType" SG_ 310 HAL_01_BZ 0;
BA_ "GenSigFuncType" SG_ 310 HAL_01_BZ 1;
BA_ "GenSigSwitchedByIgnition" SG_ 310 HAL_01_BZ 0;
BA_ "GenSigSendType" SG_ 310 HAL_01_CRC 0;
BA_ "GenSigFuncType" SG_ 310 HAL_01_CRC 2;
BA_ "GenSigSwitchedByIgnition" SG_ 310 HAL_01_CRC 0;
BA_ "GenSigSendType" SG_ 310 HAL_Charisma_FahrPr 0;
BA_ "GenSigSwitchedByIgnition" SG_ 310 HAL_Charisma_FahrPr 0;
BA_ "GenSigSendType" SG_ 310 HAL_Charisma_Status 0;
BA_ "GenSigSwitchedByIgnition" SG_ 310 HAL_Charisma_Status 0;
BA_ "GenSigSendType" SG_ 310 HAL_EFP_FahrPr 0;
BA_ "GenSigSwitchedByIgnition" SG_ 310 HAL_EFP_FahrPr 0;
BA_ "GenSigSendType" SG_ 310 HAL_Fahrerwunschwinkel_Soll 0;
BA_ "GenSigStartValue" SG_ 310 HAL_Fahrerwunschwinkel_Soll 1022;
BA_ "GenSigSwitchedByIgnition" SG_ 310 HAL_Fahrerwunschwinkel_Soll 0;
BA_ "Fehlerwert" SG_ 310 HAL_Fahrerwunschwinkel_Soll 1023;
BA_ "GenSigSendType" SG_ 310 HAL_max_Gradient 0;
BA_ "GenSigStartValue" SG_ 310 HAL_max_Gradient 126;
BA_ "GenSigSwitchedByIgnition" SG_ 310 HAL_max_Gradient 0;
BA_ "Fehlerwert" SG_ 310 HAL_max_Gradient 127;
BA_ "GenSigSendType" SG_ 310 HAL_QBit_Radwinkel 0;
BA_ "GenSigSwitchedByIgnition" SG_ 310 HAL_QBit_Radwinkel 0;
BA_ "GenSigSendType" SG_ 310 HAL_Radwinkel 0;
BA_ "GenSigStartValue" SG_ 310 HAL_Radwinkel 1022;
BA_ "GenSigSwitchedByIgnition" SG_ 310 HAL_Radwinkel 0;
BA_ "Fehlerwert" SG_ 310 HAL_Radwinkel 1023;
BA_ "GenSigSendType" SG_ 310 HAL_Status 0;
BA_ "GenSigSwitchedByIgnition" SG_ 310 HAL_Status 0;
BA_ "GenSigSendType" SG_ 310 HAL_Status_2 0;
BA_ "GenSigSwitchedByIgnition" SG_ 310 HAL_Status_2 0;
BA_ "GenSigSendType" SG_ 310 HAL_VZ_Fahrerwunschwinkel_Soll 0;
BA_ "GenSigSwitchedByIgnition" SG_ 310 HAL_VZ_Fahrerwunschwinkel_Soll 0;
BA_ "GenSigSendType" SG_ 310 HAL_VZ_Radwinkel 0;
BA_ "GenSigSwitchedByIgnition" SG_ 310 HAL_VZ_Radwinkel 0;
BA_ "GenSigSendType" SG_ 310 HAL_Warnungen 0;
BA_ "GenSigSwitchedByIgnition" SG_ 310 HAL_Warnungen 0;
BA_ "GenSigSendType" SG_ 310 HAL_Winkelbegrenzung 0;
BA_ "GenSigSwitchedByIgnition" SG_ 310 HAL_Winkelbegrenzung 0;
BA_ "GenSigSendType" SG_ 1524 AMB_Charisma_FahrPr 3;
BA_ "GenSigSwitchedByIgnition" SG_ 1524 AMB_Charisma_FahrPr 0;
BA_ "GenSigSendType" SG_ 1524 AMB_Charisma_Status 3;
BA_ "GenSigSwitchedByIgnition" SG_ 1524 AMB_Charisma_Status 0;
BA_ "GenSigSendType" SG_ 1524 BCM1_DI_Rampe_Innenlicht 3;
BA_ "GenSigSwitchedByIgnition" SG_ 1524 BCM1_DI_Rampe_Innenlicht 0;
BA_ "GenSigSendType" SG_ 1524 BCM1_DI_Rampe_Leselicht 3;
BA_ "GenSigSwitchedByIgnition" SG_ 1524 BCM1_DI_Rampe_Leselicht 0;
BA_ "GenSigSendType" SG_ 1524 BCM1_Innenlicht_gedimmt_H 3;
BA_ "GenSigSwitchedByIgnition" SG_ 1524 BCM1_Innenlicht_gedimmt_H 0;
BA_ "GenSigSendType" SG_ 1524 BCM1_Innenlicht_gedimmt_V 3;
BA_ "GenSigSwitchedByIgnition" SG_ 1524 BCM1_Innenlicht_gedimmt_V 0;
BA_ "GenSigSendType" SG_ 1524 BCM1_Innenlicht_H 3;
BA_ "GenSigSwitchedByIgnition" SG_ 1524 BCM1_Innenlicht_H 0;
BA_ "GenSigSendType" SG_ 1524 BCM1_Innenlicht_V 3;
BA_ "GenSigSwitchedByIgnition" SG_ 1524 BCM1_Innenlicht_V 0;
BA_ "GenSigSendType" SG_ 1524 BCM1_Leselicht_Anf_hl 3;
BA_ "GenSigSwitchedByIgnition" SG_ 1524 BCM1_Leselicht_Anf_hl 0;
BA_ "GenSigSendType" SG_ 1524 BCM1_Leselicht_Anf_hr 3;
BA_ "GenSigSwitchedByIgnition" SG_ 1524 BCM1_Leselicht_Anf_hr 0;
BA_ "GenSigSendType" SG_ 1524 BCM1_Leselicht_Anf_vl 3;
BA_ "GenSigSwitchedByIgnition" SG_ 1524 BCM1_Leselicht_Anf_vl 0;
BA_ "GenSigSendType" SG_ 1524 BCM1_Leselicht_Anf_vr 3;
BA_ "GenSigSwitchedByIgnition" SG_ 1524 BCM1_Leselicht_Anf_vr 0;
BA_ "GenSigSendType" SG_ 1524 BCM1_Leuchten_Aus 3;
BA_ "GenSigSwitchedByIgnition" SG_ 1524 BCM1_Leuchten_Aus 0;
BA_ "GenSigSendType" SG_ 1524 IL_Bel_BFS_Ausstieg 3;
BA_ "GenSigSwitchedByIgnition" SG_ 1524 IL_Bel_BFS_Ausstieg 0;
BA_ "GenSigSendType" SG_ 1524 IL_Bel_FS_Ausstieg 3;
BA_ "GenSigSwitchedByIgnition" SG_ 1524 IL_Bel_FS_Ausstieg 0;
BA_ "GenSigSendType" SG_ 1524 IL_Bel_HBFS_Ausstieg 3;
BA_ "GenSigSwitchedByIgnition" SG_ 1524 IL_Bel_HBFS_Ausstieg 0;
BA_ "GenSigSendType" SG_ 1524 IL_Bel_HFS_Ausstieg 3;
BA_ "GenSigSwitchedByIgnition" SG_ 1524 IL_Bel_HFS_Ausstieg 0;
BA_ "GenSigSendType" SG_ 1524 IL_Dimmung_H_Tuerkontur 3;
BA_ "GenSigSwitchedByIgnition" SG_ 1524 IL_Dimmung_H_Tuerkontur 0;
BA_ "GenSigSendType" SG_ 1524 IL_Dimmung_Lautspr 3;
BA_ "GenSigSwitchedByIgnition" SG_ 1524 IL_Dimmung_Lautspr 0;
BA_ "GenSigSendType" SG_ 1524 IL_Dimmung_Tuerinnengriff 3;
BA_ "GenSigSwitchedByIgnition" SG_ 1524 IL_Dimmung_Tuerinnengriff 0;
BA_ "GenSigSendType" SG_ 1524 IL_Dimmung_Umfeldbel 3;
BA_ "GenSigSwitchedByIgnition" SG_ 1524 IL_Dimmung_Umfeldbel 0;
BA_ "GenSigSendType" SG_ 1524 IL_Dimmung_V_Tuerkontur 3;
BA_ "GenSigSwitchedByIgnition" SG_ 1524 IL_Dimmung_V_Tuerkontur 0;
BA_ "GenSigSendType" SG_ 1524 IL_Innenlicht_aktiv 3;
BA_ "GenSigStartValue" SG_ 1524 IL_Innenlicht_aktiv 1;
BA_ "GenSigSwitchedByIgnition" SG_ 1524 IL_Innenlicht_aktiv 0;
BA_ "GenSigSendType" SG_ 1524 IL_Klemme_30G_aktiv 3;
BA_ "GenSigSwitchedByIgnition" SG_ 1524 IL_Klemme_30G_aktiv 0;
BA_ "GenSigSendType" SG_ 1838 ISO_AEM_Req_Data 3;
BA_ "GenSigFuncType" SG_ 1838 ISO_AEM_Req_Data 9;
BA_ "GenSigSwitchedByIgnition" SG_ 1838 ISO_AEM_Req_Data 0;
BA_ "GenSigSendType" SG_ 1944 ISO_AEM_Resp_Data 3;
BA_ "GenSigFuncType" SG_ 1944 ISO_AEM_Resp_Data 9;
BA_ "GenSigSendType" SG_ 1892 ISO_AGA_Req_Data 3;
BA_ "GenSigFuncType" SG_ 1892 ISO_AGA_Req_Data 9;
BA_ "GenSigSendType" SG_ 1998 ISO_AGA_Resp_Data 3;
BA_ "GenSigFuncType" SG_ 1998 ISO_AGA_Resp_Data 9;
BA_ "GenSigSendType" SG_ 1840 ISO_FLA_Req_Data 3;
BA_ "GenSigFuncType" SG_ 1840 ISO_FLA_Req_Data 9;
BA_ "GenSigSendType" SG_ 1946 ISO_FLA_Resp_Data 3;
BA_ "GenSigFuncType" SG_ 1946 ISO_FLA_Resp_Data 9;
BA_ "GenSigSendType" SG_ 1795 ISO_Funktionaler_Req_Abgas 3;
BA_ "GenSigFuncType" SG_ 1795 ISO_Funktionaler_Req_Abgas 9;
BA_ "GenSigSwitchedByIgnition" SG_ 1795 ISO_Funktionaler_Req_Abgas 0;
BA_ "GenSigSendType" SG_ 1792 ISO_ALL_01_Req_Data 3;
BA_ "GenSigFuncType" SG_ 1792 ISO_ALL_01_Req_Data 9;
BA_ "GenSigSwitchedByIgnition" SG_ 1792 ISO_ALL_01_Req_Data 0;
BA_ "GenSigSendType" SG_ 2015 ISO_OBD_Funktionaler_Req_Data 3;
BA_ "GenSigFuncType" SG_ 2015 ISO_OBD_Funktionaler_Req_Data 9;
BA_ "GenSigSwitchedByIgnition" SG_ 2015 ISO_OBD_Funktionaler_Req_Data 0;
BA_ "GenSigSendType" SG_ 1831 ISO_NightVision_Req_Data 3;
BA_ "GenSigFuncType" SG_ 1831 ISO_NightVision_Req_Data 9;
BA_ "GenSigSendType" SG_ 1937 ISO_NightVision_Resp_Data 3;
BA_ "GenSigFuncType" SG_ 1937 ISO_NightVision_Resp_Data 9;
BA_ "GenSigSendType" SG_ 1803 ISO_RDK_Req_Data 3;
BA_ "GenSigFuncType" SG_ 1803 ISO_RDK_Req_Data 9;
BA_ "GenSigSwitchedByIgnition" SG_ 1803 ISO_RDK_Req_Data 0;
BA_ "GenSigSendType" SG_ 1909 ISO_RDK_Resp_Data 3;
BA_ "GenSigFuncType" SG_ 1909 ISO_RDK_Resp_Data 9;
BA_ "GenSigSwitchedByIgnition" SG_ 1909 ISO_RDK_Resp_Data 0;
BA_ "GenSigSendType" SG_ 1897 ISO_Rearview_Req_Data 3;
BA_ "GenSigFuncType" SG_ 1897 ISO_Rearview_Req_Data 9;
BA_ "GenSigSwitchedByIgnition" SG_ 1897 ISO_Rearview_Req_Data 0;
BA_ "GenSigSendType" SG_ 2003 ISO_Rearview_Resp_Data 3;
BA_ "GenSigFuncType" SG_ 2003 ISO_Rearview_Resp_Data 9;
BA_ "GenSigSwitchedByIgnition" SG_ 2003 ISO_Rearview_Resp_Data 0;
BA_ "GenSigSendType" SG_ 1834 ISO_SCR_Req_Data 3;
BA_ "GenSigFuncType" SG_ 1834 ISO_SCR_Req_Data 9;
BA_ "GenSigSwitchedByIgnition" SG_ 1834 ISO_SCR_Req_Data 0;
BA_ "GenSigSendType" SG_ 1940 ISO_SCR_Resp_Data 3;
BA_ "GenSigFuncType" SG_ 1940 ISO_SCR_Resp_Data 9;
BA_ "GenSigSwitchedByIgnition" SG_ 1940 ISO_SCR_Resp_Data 0;
BA_ "GenSigSendType" SG_ 1820 ISO_Soundaktor_Req_Data 3;
BA_ "GenSigFuncType" SG_ 1820 ISO_Soundaktor_Req_Data 9;
BA_ "GenSigSendType" SG_ 1926 ISO_Soundaktor_Resp_Data 3;
BA_ "GenSigFuncType" SG_ 1926 ISO_Soundaktor_Resp_Data 9;
BA_ "GenSigSendType" SG_ 1898 ISO_STH_Req_Data 3;
BA_ "GenSigFuncType" SG_ 1898 ISO_STH_Req_Data 9;
BA_ "GenSigSwitchedByIgnition" SG_ 1898 ISO_STH_Req_Data 0;
BA_ "GenSigSendType" SG_ 2004 ISO_STH_Resp_Data 3;
BA_ "GenSigFuncType" SG_ 2004 ISO_STH_Resp_Data 9;
BA_ "GenSigSwitchedByIgnition" SG_ 2004 ISO_STH_Resp_Data 0;
BA_ "GenSigSendType" SG_ 1870 ISO_SWA_Req_Data 3;
BA_ "GenSigFuncType" SG_ 1870 ISO_SWA_Req_Data 9;
BA_ "GenSigSwitchedByIgnition" SG_ 1870 ISO_SWA_Req_Data 0;
BA_ "GenSigSendType" SG_ 1976 ISO_SWA_Resp_Data 3;
BA_ "GenSigFuncType" SG_ 1976 ISO_SWA_Resp_Data 9;
BA_ "GenSigSwitchedByIgnition" SG_ 1976 ISO_SWA_Resp_Data 0;
BA_ "GenSigSendType" SG_ 2549874826 ISOx_SWA_2_Req_Data 3;
BA_ "GenSigFuncType" SG_ 2549874826 ISOx_SWA_2_Req_Data 9;
BA_ "GenSigSwitchedByIgnition" SG_ 2549874826 ISOx_SWA_2_Req_Data 0;
BA_ "GenSigSendType" SG_ 2550005898 ISOx_SWA_2_Resp_Data 3;
BA_ "GenSigFuncType" SG_ 2550005898 ISOx_SWA_2_Resp_Data 9;
BA_ "GenSigSwitchedByIgnition" SG_ 2550005898 ISOx_SWA_2_Resp_Data 0;
BA_ "GenSigActiveRepetitions" SG_ 497 FBS_Aktivierung_Pilot_Parken 7;
BA_ "GenSigSendType" SG_ 497 FBS_Aktivierung_Pilot_Parken 2;
BA_ "GenSigSwitchedByIgnition" SG_ 497 FBS_Aktivierung_Pilot_Parken 0;
BA_ "GenSigActiveRepetitions" SG_ 497 FFB_FDF_Taste 7;
BA_ "GenSigSendType" SG_ 497 FFB_FDF_Taste 2;
BA_ "GenSigSwitchedByIgnition" SG_ 497 FFB_FDF_Taste 0;
BA_ "GenSigActiveRepetitions" SG_ 497 FFB_Joker_Taste 7;
BA_ "GenSigSendType" SG_ 497 FFB_Joker_Taste 2;
BA_ "GenSigSwitchedByIgnition" SG_ 497 FFB_Joker_Taste 0;
BA_ "GenSigActiveRepetitions" SG_ 497 FFB_Park_Taste 7;
BA_ "GenSigSendType" SG_ 497 FFB_Park_Taste 2;
BA_ "GenSigSwitchedByIgnition" SG_ 497 FFB_Park_Taste 0;
BA_ "GenSigActiveRepetitions" SG_ 497 FFB_Remotestart_Taste 7;
BA_ "GenSigSendType" SG_ 497 FFB_Remotestart_Taste 2;
BA_ "GenSigSwitchedByIgnition" SG_ 497 FFB_Remotestart_Taste 0;
BA_ "GenSigActiveRepetitions" SG_ 497 KY_Auf_Taste 7;
BA_ "GenSigSendType" SG_ 497 KY_Auf_Taste 2;
BA_ "GenSigSwitchedByIgnition" SG_ 497 KY_Auf_Taste 0;
BA_ "GenSigActiveRepetitions" SG_ 497 KY_Bereich 7;
BA_ "GenSigSendType" SG_ 497 KY_Bereich 2;
BA_ "GenSigStartValue" SG_ 497 KY_Bereich 7;
BA_ "GenSigSwitchedByIgnition" SG_ 497 KY_Bereich 0;
BA_ "GenSigActiveRepetitions" SG_ 497 KY_BT_Entriegelung_Autorisiert 7;
BA_ "GenSigSendType" SG_ 497 KY_BT_Entriegelung_Autorisiert 2;
BA_ "GenSigSwitchedByIgnition" SG_ 497 KY_BT_Entriegelung_Autorisiert 0;
BA_ "GenSigActiveRepetitions" SG_ 497 KY_BT_Verriegelung_Autorisiert 7;
BA_ "GenSigSendType" SG_ 497 KY_BT_Verriegelung_Autorisiert 2;
BA_ "GenSigSwitchedByIgnition" SG_ 497 KY_BT_Verriegelung_Autorisiert 0;
BA_ "GenSigSendType" SG_ 497 KY_EasyClose_Abbruch 3;
BA_ "GenSigSwitchedByIgnition" SG_ 497 KY_EasyClose_Abbruch 0;
BA_ "GenSigSendType" SG_ 497 KY_EasyClose_Status 3;
BA_ "GenSigSwitchedByIgnition" SG_ 497 KY_EasyClose_Status 0;
BA_ "GenSigActiveRepetitions" SG_ 497 KY_Front_Entr_Autorisiert 7;
BA_ "GenSigSendType" SG_ 497 KY_Front_Entr_Autorisiert 2;
BA_ "GenSigSwitchedByIgnition" SG_ 497 KY_Front_Entr_Autorisiert 0;
BA_ "GenSigActiveRepetitions" SG_ 497 KY_Front_Verr_Autorisiert 7;
BA_ "GenSigSendType" SG_ 497 KY_Front_Verr_Autorisiert 2;
BA_ "GenSigSwitchedByIgnition" SG_ 497 KY_Front_Verr_Autorisiert 0;
BA_ "GenSigActiveRepetitions" SG_ 497 KY_FT_Entriegelung_Autorisiert 7;
BA_ "GenSigSendType" SG_ 497 KY_FT_Entriegelung_Autorisiert 2;
BA_ "GenSigSwitchedByIgnition" SG_ 497 KY_FT_Entriegelung_Autorisiert 0;
BA_ "GenSigActiveRepetitions" SG_ 497 KY_FT_Verriegelung_Autorisiert 7;
BA_ "GenSigSendType" SG_ 497 KY_FT_Verriegelung_Autorisiert 2;
BA_ "GenSigSwitchedByIgnition" SG_ 497 KY_FT_Verriegelung_Autorisiert 0;
BA_ "GenSigActiveRepetitions" SG_ 497 KY_HBFS_Entriegelung_Autorisiert 7;
BA_ "GenSigSendType" SG_ 497 KY_HBFS_Entriegelung_Autorisiert 2;
BA_ "GenSigSwitchedByIgnition" SG_ 497 KY_HBFS_Entriegelung_Autorisiert 0;
BA_ "GenSigActiveRepetitions" SG_ 497 KY_HBFS_Verriegelung_Autorisiert 7;
BA_ "GenSigSendType" SG_ 497 KY_HBFS_Verriegelung_Autorisiert 2;
BA_ "GenSigSwitchedByIgnition" SG_ 497 KY_HBFS_Verriegelung_Autorisiert 0;
BA_ "GenSigActiveRepetitions" SG_ 497 KY_HD_Auffahrt 7;
BA_ "GenSigSendType" SG_ 497 KY_HD_Auffahrt 2;
BA_ "GenSigSwitchedByIgnition" SG_ 497 KY_HD_Auffahrt 0;
BA_ "GenSigActiveRepetitions" SG_ 497 KY_HD_Entriegelung_Autorisiert 7;
BA_ "GenSigSendType" SG_ 497 KY_HD_Entriegelung_Autorisiert 2;
BA_ "GenSigSwitchedByIgnition" SG_ 497 KY_HD_Entriegelung_Autorisiert 0;
BA_ "GenSigActiveRepetitions" SG_ 497 KY_HD_Verriegelung_Autorisiert 7;
BA_ "GenSigSendType" SG_ 497 KY_HD_Verriegelung_Autorisiert 2;
BA_ "GenSigSwitchedByIgnition" SG_ 497 KY_HD_Verriegelung_Autorisiert 0;
BA_ "GenSigActiveRepetitions" SG_ 497 KY_HD_Zufahrt 7;
BA_ "GenSigSendType" SG_ 497 KY_HD_Zufahrt 2;
BA_ "GenSigSwitchedByIgnition" SG_ 497 KY_HD_Zufahrt 0;
BA_ "GenSigActiveRepetitions" SG_ 497 KY_HDF_Taste 7;
BA_ "GenSigSendType" SG_ 497 KY_HDF_Taste 2;
BA_ "GenSigSwitchedByIgnition" SG_ 497 KY_HDF_Taste 0;
BA_ "GenSigActiveRepetitions" SG_ 497 KY_HFS_Entriegelung_Autorisiert 7;
BA_ "GenSigSendType" SG_ 497 KY_HFS_Entriegelung_Autorisiert 2;
BA_ "GenSigSwitchedByIgnition" SG_ 497 KY_HFS_Entriegelung_Autorisiert 0;
BA_ "GenSigActiveRepetitions" SG_ 497 KY_HFS_Verriegelung_Autorisiert 7;
BA_ "GenSigSendType" SG_ 497 KY_HFS_Verriegelung_Autorisiert 2;
BA_ "GenSigSwitchedByIgnition" SG_ 497 KY_HFS_Verriegelung_Autorisiert 0;
BA_ "GenSigActiveRepetitions" SG_ 497 KY_IDG_in_Reichweite 7;
BA_ "GenSigSendType" SG_ 497 KY_IDG_in_Reichweite 2;
BA_ "GenSigSwitchedByIgnition" SG_ 497 KY_IDG_in_Reichweite 0;
BA_ "GenSigActiveRepetitions" SG_ 497 KY_LKL_1_Autorisierung 7;
BA_ "GenSigSendType" SG_ 497 KY_LKL_1_Autorisierung 2;
BA_ "GenSigSwitchedByIgnition" SG_ 497 KY_LKL_1_Autorisierung 0;
BA_ "GenSigActiveRepetitions" SG_ 497 KY_LKL_2_Autorisierung 7;
BA_ "GenSigSendType" SG_ 497 KY_LKL_2_Autorisierung 2;
BA_ "GenSigSwitchedByIgnition" SG_ 497 KY_LKL_2_Autorisierung 0;
BA_ "GenSigActiveRepetitions" SG_ 497 KY_Panik_Taste 7;
BA_ "GenSigSendType" SG_ 497 KY_Panik_Taste 2;
BA_ "GenSigSwitchedByIgnition" SG_ 497 KY_Panik_Taste 0;
BA_ "GenSigActiveRepetitions" SG_ 497 KY_Position 7;
BA_ "GenSigSendType" SG_ 497 KY_Position 2;
BA_ "GenSigStartValue" SG_ 497 KY_Position 7;
BA_ "GenSigSwitchedByIgnition" SG_ 497 KY_Position 0;
BA_ "GenSigActiveRepetitions" SG_ 497 KY_Schluessel_im_Fzg 7;
BA_ "GenSigSendType" SG_ 497 KY_Schluessel_im_Fzg 2;
BA_ "GenSigSwitchedByIgnition" SG_ 497 KY_Schluessel_im_Fzg 0;
BA_ "GenSigActiveRepetitions" SG_ 497 KY_Zu_Taste 7;
BA_ "GenSigSendType" SG_ 497 KY_Zu_Taste 2;
BA_ "GenSigSwitchedByIgnition" SG_ 497 KY_Zu_Taste 0;
BA_ "GenSigActiveRepetitions" SG_ 497 KY_ZV_Signatur 7;
BA_ "GenSigSendType" SG_ 497 KY_ZV_Signatur 2;
BA_ "GenSigSwitchedByIgnition" SG_ 497 KY_ZV_Signatur 0;
BA_ "GenSigActiveRepetitions" SG_ 497 Schluesselnr_Personalisierung 7;
BA_ "GenSigSendType" SG_ 497 Schluesselnr_Personalisierung 2;
BA_ "GenSigStartValue" SG_ 497 Schluesselnr_Personalisierung 14;
BA_ "GenSigSwitchedByIgnition" SG_ 497 Schluesselnr_Personalisierung 0;
BA_ "Fehlerwert" SG_ 497 Schluesselnr_Personalisierung 15;
BA_ "GenSigSendType" SG_ 960 BCM_Ausparken_Betrieb 3;
BA_ "GenSigSwitchedByIgnition" SG_ 960 BCM_Ausparken_Betrieb 0;
BA_ "GenSigSendType" SG_ 960 BCM_Remotestart_Betrieb 3;
BA_ "GenSigSwitchedByIgnition" SG_ 960 BCM_Remotestart_Betrieb 0;
BA_ "GenSigSendType" SG_ 960 BCM_Remotestart_KL15_Anf 3;
BA_ "GenSigSwitchedByIgnition" SG_ 960 BCM_Remotestart_KL15_Anf 0;
BA_ "GenSigSendType" SG_ 960 BCM_Remotestart_MO_Start 3;
BA_ "GenSigSwitchedByIgnition" SG_ 960 BCM_Remotestart_MO_Start 0;
BA_ "GenSigSendType" SG_ 960 Klemmen_Status_01_BZ 0;
BA_ "GenSigFuncType" SG_ 960 Klemmen_Status_01_BZ 1;
BA_ "GenSigSwitchedByIgnition" SG_ 960 Klemmen_Status_01_BZ 0;
BA_ "GenSigSendType" SG_ 960 Klemmen_Status_01_CRC 0;
BA_ "GenSigFuncType" SG_ 960 Klemmen_Status_01_CRC 2;
BA_ "GenSigSwitchedByIgnition" SG_ 960 Klemmen_Status_01_CRC 0;
BA_ "GenSigSendType" SG_ 960 KST_Fahrerhinweis_1 3;
BA_ "GenSigSwitchedByIgnition" SG_ 960 KST_Fahrerhinweis_1 0;
BA_ "GenSigSendType" SG_ 960 KST_Fahrerhinweis_2 3;
BA_ "GenSigSwitchedByIgnition" SG_ 960 KST_Fahrerhinweis_2 0;
BA_ "GenSigSendType" SG_ 960 KST_Fahrerhinweis_4 3;
BA_ "GenSigSwitchedByIgnition" SG_ 960 KST_Fahrerhinweis_4 0;
BA_ "GenSigSendType" SG_ 960 KST_Fahrerhinweis_5 3;
BA_ "GenSigSwitchedByIgnition" SG_ 960 KST_Fahrerhinweis_5 0;
BA_ "GenSigSendType" SG_ 960 KST_Fahrerhinweis_6 3;
BA_ "GenSigSwitchedByIgnition" SG_ 960 KST_Fahrerhinweis_6 0;
BA_ "GenSigSendType" SG_ 960 KST_Warn_P1_ZST_def 3;
BA_ "GenSigSwitchedByIgnition" SG_ 960 KST_Warn_P1_ZST_def 0;
BA_ "GenSigSendType" SG_ 960 KST_Warn_P2_ZST_def 3;
BA_ "GenSigSwitchedByIgnition" SG_ 960 KST_Warn_P2_ZST_def 0;
BA_ "GenSigSendType" SG_ 960 RSt_Fahrerhinweise 3;
BA_ "GenSigSwitchedByIgnition" SG_ 960 RSt_Fahrerhinweise 0;
BA_ "GenSigSendType" SG_ 960 ZAS_Kl_15 3;
BA_ "NWM-WakeupAllowed" SG_ 960 ZAS_Kl_15 1;
BA_ "GenSigFuncType" SG_ 960 ZAS_Kl_15 6;
BA_ "GenSigSwitchedByIgnition" SG_ 960 ZAS_Kl_15 0;
BA_ "GenSigSendType" SG_ 960 ZAS_Kl_50_Startanforderung 3;
BA_ "GenSigSwitchedByIgnition" SG_ 960 ZAS_Kl_50_Startanforderung 0;
BA_ "GenSigSendType" SG_ 960 ZAS_Kl_Infotainment 3;
BA_ "GenSigSwitchedByIgnition" SG_ 960 ZAS_Kl_Infotainment 0;
BA_ "GenSigSendType" SG_ 960 ZAS_Kl_S 3;
BA_ "GenSigSwitchedByIgnition" SG_ 960 ZAS_Kl_S 0;
BA_ "GenSigSendType" SG_ 960 ZAS_Kl_X 3;
BA_ "GenSigSwitchedByIgnition" SG_ 960 ZAS_Kl_X 0;
BA_REL_ "GenSigTimeoutTime" BU_SG_REL_ AEM SG_ 253 OBD_Schlechtweg 500;
BA_REL_ "GenSigTimeoutTime" BU_SG_REL_ AEM SG_ 253 ESP_v_Signal 500;
BA_REL_ "GenSigTimeoutTime" BU_SG_REL_ AEM SG_ 960 ZAS_Kl_15 1000;
BA_REL_ "GenSigTimeoutTime" BU_SG_REL_ E_Sound SG_ 253 ESP_v_Signal 500;
BA_REL_ "GenSigTimeoutTime" BU_SG_REL_ E_Sound SG_ 968 GE_LaunchControl 800;
BA_REL_ "GenSigTimeoutTime" BU_SG_REL_ E_Sound SG_ 960 ZAS_Kl_15 1000;
BA_REL_ "GenSigTimeoutTime" BU_SG_REL_ FBK SG_ 253 ESP_v_Signal 500;
BA_REL_ "GenSigTimeoutTime" BU_SG_REL_ FBK SG_ 960 ZAS_Kl_15 1000;
BA_REL_ "GenSigTimeoutTime" BU_SG_REL_ FLA SG_ 253 ESP_v_Signal 500;
BA_REL_ "GenSigTimeoutTime" BU_SG_REL_ FLA SG_ 253 ESP_QBit_v_Signal 500;
BA_REL_ "GenSigTimeoutTime" BU_SG_REL_ FLA SG_ 1524 IL_Innenlicht_aktiv 5000;
BA_REL_ "GenSigTimeoutTime" BU_SG_REL_ ISE SG_ 253 ESP_v_Signal 500;
BA_REL_ "GenSigTimeoutTime" BU_SG_REL_ ISE SG_ 253 ESP_Eingriff 500;
BA_REL_ "GenSigTimeoutTime" BU_SG_REL_ ISE SG_ 968 GE_LaunchControl 800;
BA_REL_ "GenSigTimeoutTime" BU_SG_REL_ ISE SG_ 960 ZAS_Kl_15 1000;
BA_REL_ "GenSigTimeoutTime" BU_SG_REL_ NightVision SG_ 996 MKE_Texte 5000;
BA_REL_ "GenSigTimeoutTime" BU_SG_REL_ NightVision SG_ 996 MKE_FAS 5000;
BA_REL_ "GenSigTimeoutTime" BU_SG_REL_ NightVision SG_ 418 VZM_Status 2000;
BA_REL_ "GenSigTimeoutTime" BU_SG_REL_ NightVision SG_ 253 ESP_v_Signal 500;
BA_REL_ "GenSigTimeoutTime" BU_SG_REL_ NightVision SG_ 253 ESP_QBit_v_Signal 500;
BA_REL_ "GenSigTimeoutTime" BU_SG_REL_ NightVision SG_ 427 ESC_Prefill_aktiv 2000;
BA_REL_ "GenSigTimeoutTime" BU_SG_REL_ NightVision SG_ 427 ESC_Prefill_nicht_verfuegbar 2000;
BA_REL_ "GenSigTimeoutTime" BU_SG_REL_ NightVision SG_ 427 ESC_HBA_aktiv 2000;
BA_REL_ "GenSigTimeoutTime" BU_SG_REL_ NightVision SG_ 427 ESC_HBA_nicht_verfuegbar 2000;
BA_REL_ "GenSigTimeoutTime" BU_SG_REL_ NightVision SG_ 427 ESC_Konsistenz_NV 2000;
BA_REL_ "GenSigTimeoutTime" BU_SG_REL_ NightVision SG_ 2463978619 FAS_SollStatus_Fkt_NV 5000;
BA_REL_ "GenSigTimeoutTime" BU_SG_REL_ NightVision SG_ 1332 FCWO_Warnung 2000;
BA_REL_ "GenSigTimeoutTime" BU_SG_REL_ NightVision SG_ 1332 FCWP_Warnung 2000;
BA_REL_ "GenSigTimeoutTime" BU_SG_REL_ NightVision SG_ 497 Schluesselnr_Personalisierung 5000;
BA_REL_ "GenSigTimeoutTime" BU_SG_REL_ NightVision SG_ 960 ZAS_Kl_15 1000;
BA_REL_ "GenSigTimeoutTime" BU_SG_REL_ NightVision SG_ 960 BCM_Ausparken_Betrieb 1000;
BA_REL_ "GenSigTimeoutTime" BU_SG_REL_ RDK SG_ 1603 KBI_Einheit_Druck 5000;
BA_REL_ "GenSigTimeoutTime" BU_SG_REL_ RDK SG_ 1603 KBI_Einheit_Temp 5000;
BA_REL_ "GenSigTimeoutTime" BU_SG_REL_ RDK SG_ 278 ESP_QBit_Wegimpuls_VL 500;
BA_REL_ "GenSigTimeoutTime" BU_SG_REL_ RDK SG_ 278 ESP_QBit_Wegimpuls_VR 500;
BA_REL_ "GenSigTimeoutTime" BU_SG_REL_ RDK SG_ 278 ESP_QBit_Wegimpuls_HL 500;
BA_REL_ "GenSigTimeoutTime" BU_SG_REL_ RDK SG_ 278 ESP_QBit_Wegimpuls_HR 500;
BA_REL_ "GenSigTimeoutTime" BU_SG_REL_ RDK SG_ 278 ESP_Wegimpuls_VL 500;
BA_REL_ "GenSigTimeoutTime" BU_SG_REL_ RDK SG_ 278 ESP_Wegimpuls_VR 500;
BA_REL_ "GenSigTimeoutTime" BU_SG_REL_ RDK SG_ 278 ESP_Wegimpuls_HL 500;
BA_REL_ "GenSigTimeoutTime" BU_SG_REL_ RDK SG_ 278 ESP_Wegimpuls_HR 500;
BA_REL_ "GenSigTimeoutTime" BU_SG_REL_ RDK SG_ 278 ESP_VL_Fahrtrichtung 500;
BA_REL_ "GenSigTimeoutTime" BU_SG_REL_ RDK SG_ 278 ESP_VR_Fahrtrichtung 500;
BA_REL_ "GenSigTimeoutTime" BU_SG_REL_ RDK SG_ 278 ESP_HL_Fahrtrichtung 500;
BA_REL_ "GenSigTimeoutTime" BU_SG_REL_ RDK SG_ 278 ESP_HR_Fahrtrichtung 500;
BA_REL_ "GenSigTimeoutTime" BU_SG_REL_ RDK SG_ 253 ESP_v_Signal 500;
BA_REL_ "GenSigTimeoutTime" BU_SG_REL_ RDK SG_ 253 ESP_QBit_v_Signal 500;
BA_REL_ "GenSigTimeoutTime" BU_SG_REL_ RDK SG_ 960 ZAS_Kl_15 1000;
BA_REL_ "GenSigTimeoutTime" BU_SG_REL_ SAK SG_ 2527679980 eCall_Funktionsstatus_02 5000;
BA_REL_ "GenSigTimeoutTime" BU_SG_REL_ SAK SG_ 2527679980 eCall_Mute_Anf 5000;
BA_REL_ "GenSigTimeoutTime" BU_SG_REL_ SAK SG_ 253 ESP_v_Signal 500;
BA_REL_ "GenSigTimeoutTime" BU_SG_REL_ SAK SG_ 173 GE_Fahrstufe 1000;
BA_REL_ "GenSigTimeoutTime" BU_SG_REL_ SAK2 SG_ 2527679980 eCall_Funktionsstatus_02 5000;
BA_REL_ "GenSigTimeoutTime" BU_SG_REL_ SAK2 SG_ 2527679980 eCall_Mute_Anf 5000;
BA_REL_ "GenSigTimeoutTime" BU_SG_REL_ SAK2 SG_ 253 ESP_v_Signal 500;
BA_REL_ "GenSigTimeoutTime" BU_SG_REL_ SAK2 SG_ 173 GE_Fahrstufe 1000;
BA_REL_ "GenSigTimeoutTime" BU_SG_REL_ SCR SG_ 253 ESP_v_Signal 500;
BA_REL_ "GenSigTimeoutTime" BU_SG_REL_ SCR SG_ 253 ESP_QBit_v_Signal 500;
BA_REL_ "GenSigTimeoutTime" BU_SG_REL_ SCR SG_ 960 ZAS_Kl_15 1000;
BA_REL_ "GenSigTimeoutTime" BU_SG_REL_ SCR SG_ 960 BCM_Remotestart_KL15_Anf 1000;
BA_REL_ "GenSigTimeoutTime" BU_SG_REL_ STH_MLBevo SG_ 253 ESP_v_Signal 500;
BA_REL_ "GenSigTimeoutTime" BU_SG_REL_ STH_MLBevo SG_ 253 ESP_QBit_v_Signal 500;
BA_REL_ "GenSigTimeoutTime" BU_SG_REL_ STH_MLBevo SG_ 960 ZAS_Kl_15 1000;
BA_REL_ "GenSigTimeoutTime" BU_SG_REL_ TopView SG_ 259 ESP_VL_Radgeschw 500;
BA_REL_ "GenSigTimeoutTime" BU_SG_REL_ TopView SG_ 259 ESP_VR_Radgeschw 500;
BA_REL_ "GenSigTimeoutTime" BU_SG_REL_ TopView SG_ 259 ESP_HL_Radgeschw 500;
BA_REL_ "GenSigTimeoutTime" BU_SG_REL_ TopView SG_ 259 ESP_HR_Radgeschw 500;
BA_REL_ "GenSigTimeoutTime" BU_SG_REL_ TopView SG_ 278 ESP_QBit_Wegimpuls_VL 500;
BA_REL_ "GenSigTimeoutTime" BU_SG_REL_ TopView SG_ 278 ESP_QBit_Wegimpuls_VR 500;
BA_REL_ "GenSigTimeoutTime" BU_SG_REL_ TopView SG_ 278 ESP_QBit_Wegimpuls_HL 500;
BA_REL_ "GenSigTimeoutTime" BU_SG_REL_ TopView SG_ 278 ESP_QBit_Wegimpuls_HR 500;
BA_REL_ "GenSigTimeoutTime" BU_SG_REL_ TopView SG_ 278 ESP_Wegimpuls_VL 500;
BA_REL_ "GenSigTimeoutTime" BU_SG_REL_ TopView SG_ 278 ESP_Wegimpuls_VR 500;
BA_REL_ "GenSigTimeoutTime" BU_SG_REL_ TopView SG_ 278 ESP_Wegimpuls_HL 500;
BA_REL_ "GenSigTimeoutTime" BU_SG_REL_ TopView SG_ 278 ESP_Wegimpuls_HR 500;
BA_REL_ "GenSigTimeoutTime" BU_SG_REL_ TopView SG_ 278 ESP_VL_Fahrtrichtung 500;
BA_REL_ "GenSigTimeoutTime" BU_SG_REL_ TopView SG_ 278 ESP_VR_Fahrtrichtung 500;
BA_REL_ "GenSigTimeoutTime" BU_SG_REL_ TopView SG_ 278 ESP_HL_Fahrtrichtung 500;
BA_REL_ "GenSigTimeoutTime" BU_SG_REL_ TopView SG_ 278 ESP_HR_Fahrtrichtung 500;
BA_REL_ "GenSigTimeoutTime" BU_SG_REL_ TopView SG_ 1629 ESP_Zaehnezahl 1600;
BA_REL_ "GenSigTimeoutTime" BU_SG_REL_ TopView SG_ 1629 BR_QBit_Reifenumfang 1600;
BA_REL_ "GenSigTimeoutTime" BU_SG_REL_ TopView SG_ 1629 BR_Reifenumfang 1600;
BA_REL_ "GenSigTimeoutTime" BU_SG_REL_ TopView SG_ 253 ESP_v_Signal 500;
BA_REL_ "GenSigTimeoutTime" BU_SG_REL_ TopView SG_ 253 ASR_Tastung_passiv 500;
BA_REL_ "GenSigTimeoutTime" BU_SG_REL_ TopView SG_ 253 ESP_Tastung_passiv 500;
BA_REL_ "GenSigTimeoutTime" BU_SG_REL_ TopView SG_ 253 ESP_Systemstatus 500;
BA_REL_ "GenSigTimeoutTime" BU_SG_REL_ TopView SG_ 253 ESP_QBit_v_Signal 500;
BA_REL_ "GenSigTimeoutTime" BU_SG_REL_ TopView SG_ 253 ABS_Bremsung 500;
BA_REL_ "GenSigTimeoutTime" BU_SG_REL_ TopView SG_ 253 ASR_Anf 500;
BA_REL_ "GenSigTimeoutTime" BU_SG_REL_ TopView SG_ 253 MSR_Anf 500;
BA_REL_ "GenSigTimeoutTime" BU_SG_REL_ TopView SG_ 253 EBV_Eingriff 500;
BA_REL_ "GenSigTimeoutTime" BU_SG_REL_ TopView SG_ 253 EDS_Eingriff 500;
BA_REL_ "GenSigTimeoutTime" BU_SG_REL_ TopView SG_ 253 ESP_Eingriff 500;
BA_REL_ "GenSigTimeoutTime" BU_SG_REL_ TopView SG_ 264 FA_Hoehenwerte_kalibriert 5000;
BA_REL_ "GenSigTimeoutTime" BU_SG_REL_ TopView SG_ 264 FA_Hoehenwert_VL_00 5000;
BA_REL_ "GenSigTimeoutTime" BU_SG_REL_ TopView SG_ 264 FA_Hoehenwert_VR_00 5000;
BA_REL_ "GenSigTimeoutTime" BU_SG_REL_ TopView SG_ 264 FA_Hoehenwert_HL_00 5000;
BA_REL_ "GenSigTimeoutTime" BU_SG_REL_ TopView SG_ 264 FA_Hoehenwert_HR_00 5000;
BA_REL_ "GenSigTimeoutTime" BU_SG_REL_ TopView SG_ 310 HAL_VZ_Radwinkel 500;
BA_REL_ "GenSigTimeoutTime" BU_SG_REL_ TopView SG_ 310 HAL_QBit_Radwinkel 500;
BA_REL_ "GenSigTimeoutTime" BU_SG_REL_ TopView SG_ 310 HAL_Radwinkel 500;
BA_REL_ "GenSigTimeoutTime" BU_SG_REL_ TopView SG_ 960 ZAS_Kl_15 1000;
VAL_ 2527679980 eCall_Statuslicht_Farbe2 0 "Aus" 1 "Blinken_1" 2 "Blinken_2" 3 "An" ;
VAL_ 2527679980 eCall_Statuslicht_Farbe1 0 "Aus" 1 "Blinken_1" 2 "Blinken_2" 3 "An" ;
VAL_ 2527679980 bCall_active 0 "bcall_inactive" 1 "bcall_active" ;
VAL_ 2527679980 eCall_Funktionsstatus 0 "kein_Fehler" 1 "Fkt_eingeschraenkt" 2 "Fkt_eingeschraenkt_service" 3 "Fkt_nicht_verfuegbar" 4 "Fkt_Service" 5 "Fkt_deaktiviert" 6 "Fkt_aktiviert" 7 "init" ;
VAL_ 2527679980 eCall_Subscription 0 "Init" 1 "unsubscribed" 2 "subscribed" ;
VAL_ 2527679980 eCall_Funktionsstatus_02 0 "kein_Fehler" 1 "Manueller_Notruf_aktiv" 2 "Automatischer_Notruf_aktiv" 7 "Init" ;
VAL_ 2527679980 eCall_Mute_Anf 0 "kein_mute" 1 "mute" ;
VAL_ 996 EFF_Verbraucher_Balken 510 "Init" 511 "Fehler" ;
VAL_ 996 EFF_Verbraucher_Pos_1 0 "keine_Anzeige" 1 "Klimaautomatik" 2 "Standheizung" 3 "Heckscheibe" 4 "Sitzheizung_links" 5 "Sitzheizung_rechts" 6 "Sitzlueftung_links" 7 "Sitzlueftung_rechts" 8 "Nackenheizung_links" 9 "Nackenheizung_rechts" 10 "Nebellicht_vorne" 11 "Nebelschlussleuchte" 12 "Frontscheibenheizung" 13 "Lenkradheizung" 14 "Spiegelheizung" 15 "Sitzheizung_hinten" 16 "Sitzlueftung_hinten" ;
VAL_ 996 EFF_Verbraucher_Pos_2 0 "keine_Anzeige" 1 "Klimaautomatik" 2 "Standheizung" 3 "Heckscheibe" 4 "Sitzheizung_links" 5 "Sitzheizung_rechts" 6 "Sitzlueftung_links" 7 "Sitzlueftung_rechts" 8 "Nackenheizung_links" 9 "Nackenheizung_rechts" 10 "Nebellicht_vorne" 11 "Nebelschlussleuchte" 12 "Frontscheibenheizung" 13 "Lenkradheizung" 14 "Spiegelheizung" 15 "Sitzheizung_hinten" 16 "Sitzlueftung_hinten" ;
VAL_ 996 EFF_Verbraucher_Pos_3 0 "keine_Anzeige" 1 "Klimaautomatik" 2 "Standheizung" 3 "Heckscheibe" 4 "Sitzheizung_links" 5 "Sitzheizung_rechts" 6 "Sitzlueftung_links" 7 "Sitzlueftung_rechts" 8 "Nackenheizung_links" 9 "Nackenheizung_rechts" 10 "Nebellicht_vorne" 11 "Nebelschlussleuchte" 12 "Frontscheibenheizung" 13 "Lenkradheizung" 14 "Spiegelheizung" 15 "Sitzheizung_hinten" 16 "Sitzlueftung_hinten" ;
VAL_ 996 EFF_Einsparhinweis 0 "Init" 1 "Erhoehter_Luftwiderst_Fenster" 2 "Erhoehter_Luftwiderst_Schiebedach" 3 "Erhoehter_Luftwiderst_Fenst_Schiebed" 4 "Nutzung_Motorbremse" 5 "Gaspedal_bei_Motorstart" 6 "Schaltanzeige_beachten" 7 "StartStop_nutzen" 8 "StartStop_einschalten" 9 "Ineff_Betrieb_Klima_Fenster" 10 "Ineff_Betrieb_Klima_Schiebedach" 11 "Ineff_Betrieb_Klima_Fenst_Schiebed" 12 "Fahrstufe_D_verwenden" 13 "Gaspedal_im_Stand" ;
VAL_ 996 EFF_Verbrauch_STH 127 "Fehler" ;
VAL_ 996 MKE_Texte 0 "keine_Anzeige" 1 "Warnstufe_1" 2 "Warnstufe_2" ;
VAL_ 996 MKE_FAS 0 "keine_Anzeige" 1 "Warnstufe_1" 2 "Warnstufe_2" ;
VAL_ 996 MKE_Stufe 0 "deaktiviert" 1 "nicht_verfügbar" 2 "Stufe_1" 3 "Stufe_2" 4 "Stufe_3" 5 "Stufe_4" 6 "reserviert" 7 "reserviert" ;
VAL_ 996 MKE_FAS_Fkt_Status 0 "Init" 1 "Funktion_Ist_Ein" 2 "Funktion_Ist_Aus" 3 "Fehler" ;
VAL_ 996 MKE_Fehlercode 0 "Init" 1 "gueltig" 2 "eingeschraenkt_gueltig" 3 "ungueltig" 4 "nicht_verbaut" ;
VAL_ 1603 KBI_Einheit_Datum 0 "Tag/Monat/Jahr" 1 "Monat/Tag/Jahr" 2 "Jahr/Monat/Tag" 3 "reserviert" ;
VAL_ 1603 KBI_Einheit_Druck 0 "Druckangabe in bar" 1 "Druckangabe in psi" 2 "Druckangabe in kPa" 3 "tbd." ;
VAL_ 1603 KBI_Einheit_Streckenanz 0 "Kilometer" 1 "Meilen" ;
VAL_ 1603 KBI_MFA_v_Einheit_02 0 "kmh" 1 "mph" ;
VAL_ 1603 KBI_Einheit_Temp 0 "Grad Celsius °C" 1 "Grad Fahrenheit °F" ;
VAL_ 1603 KBI_Einheit_Uhrzeit 0 "24h" 1 " 12h AM/PM" ;
VAL_ 1603 KBI_Einheit_Verbrauch 0 "mpg UK" 1 "mpg USA" 2 "Liter/100km" 3 "km/Liter" ;
VAL_ 1603 KBI_Einheit_Volumen 0 "Liter" 1 "Gallonen UK" 2 "Gallonen USA" 3 "reserviert" ;
VAL_ 1603 KBI_Einheit_Verbrauch_elektr 0 "kWh_pro_100km" 1 "km_pro_kWh" 2 "kWh_pro_100mls" 3 "mls_pro_kWh" 4 "MPGe" ;
VAL_ 1603 KBI_Einheit_Verbrauch_Gas 0 "kg_per_100km" 1 "km_per_kg" 2 "m3_per_100km" 3 "km_per_m3" 4 "miles_per_lbs" 5 "miles_per_yard3" 6 "miles_per_kg" 7 "miles_per_m3" 8 "miles_per_gallon_equivalent_US" ;
VAL_ 1603 KBI_Einheit_Masse 0 "kg" 1 "lbs" 2 "reserviert" ;
VAL_ 259 ESP_VL_FR 0 "Vorwaerts" 1 "Rueckwaerts" ;
VAL_ 259 ESP_VR_FR 0 "Vorwaerts" 1 "Rueckwaerts" ;
VAL_ 259 ESP_HL_FR 0 "Vorwaerts" 1 "Rueckwaerts" ;
VAL_ 259 ESP_HR_FR 0 "Vorwaerts" 1 "Rueckwaerts" ;
VAL_ 259 ESP_VL_Radgeschw 4093 "Unterspannung" 4094 "Init" 4095 "Fehler" ;
VAL_ 259 ESP_VR_Radgeschw 4093 "Unterspannung" 4094 "Init" 4095 "Fehler" ;
VAL_ 259 ESP_HL_Radgeschw 4093 "Unterspannung" 4094 "Init" 4095 "Fehler" ;
VAL_ 259 ESP_HR_Radgeschw 4093 "Unterspannung" 4094 "Init" 4095 "Fehler" ;
VAL_ 278 ESP_QBit_Wegimpuls_VL 0 "gueltiger_Wert" 1 "Ersatz_Init_oder_Fehlerwert" ;
VAL_ 278 ESP_QBit_Wegimpuls_VR 0 "gueltiger_Wert" 1 "Ersatz_Init_oder_Fehlerwert" ;
VAL_ 278 ESP_QBit_Wegimpuls_HL 0 "gueltiger_Wert" 1 "Ersatz_Init_oder_Fehlerwert" ;
VAL_ 278 ESP_QBit_Wegimpuls_HR 0 "gueltiger_Wert" 1 "Ersatz_Init_oder_Fehlerwert" ;
VAL_ 278 ESP_Wegimpuls_VL 1021 "Init" 1022 "Unterspannung" 1023 "Fehler" ;
VAL_ 278 ESP_Wegimpuls_VR 1021 "Init" 1022 "Unterspannung" 1023 "Fehler" ;
VAL_ 278 ESP_Wegimpuls_HL 1021 "Init" 1022 "Unterspannung" 1023 "Fehler" ;
VAL_ 278 ESP_Wegimpuls_HR 1021 "Init" 1022 "Unterspannung" 1023 "Fehler" ;
VAL_ 278 ESP_VL_Fahrtrichtung 0 "Vorwaerts" 1 "Rueckwaerts" 2 "Init" 3 "ungueltig_oder_nicht_verbaut" ;
VAL_ 278 ESP_VR_Fahrtrichtung 0 "Vorwaerts" 1 "Rueckwaerts" 2 "Init" 3 "ungueltig_oder_nicht_verbaut" ;
VAL_ 278 ESP_HL_Fahrtrichtung 0 "Vorwaerts" 1 "Rueckwaerts" 2 "Init" 3 "ungueltig_oder_nicht_verbaut" ;
VAL_ 278 ESP_HR_Fahrtrichtung 0 "Vorwaerts" 1 "Rueckwaerts" 2 "Init" 3 "ungueltig_oder_nicht_verbaut" ;
VAL_ 418 HMS_P_beibehalten_GE 0 "P_nicht_beibehalten" 1 "P_beibehalten" 2 "Init" 3 "Fehler" ;
VAL_ 418 HMS_Konsistenz_GE 0 "kein_Fehler_erkannt" 1 "Fehler_erkannt" ;
VAL_ 418 HMS_Konsistenz_IPA 0 "kein_Fehler_erkannt" 1 "Fehler_erkannt" ;
VAL_ 418 HMS_Konsistenz_STA 0 "kein_Fehler_erkannt" 1 "Fehler_erkannt" ;
VAL_ 418 HMS_Konsistenz_MO 0 "kein_Fehler_erkannt" 1 "Fehler_erkannt" ;
VAL_ 418 HMS_halten_nicht_verfuegbar 0 "verfuegbar" 1 "nicht_verfuegbar" ;
VAL_ 418 NL_PRIM_STP_01_Status 0 "Notlauf_inaktiv" 1 "Notlauf_bereit" 2 "Notlauf_aktiv" 3 "Notlauf_nicht_verfuegbar" 4 "Notlauf_aktivierbar" ;
VAL_ 418 VMM_Warnblinken 0 "Aus" 1 "An" ;
VAL_ 418 VZM_Status 0 "Initialisierung" 1 "Verfuegbar" 2 "Verfuegbar_mit_eingeschraenkter_Performance" 3 "Nicht_Verfuegbar" 4 "Fehler" ;
VAL_ 418 HMS_Notstopp_Status 0 "Off_Init" 1 "Inaktiv" 2 "Ready" 3 "Aktiv" 4 "Pending" 7 "nicht_Verfuegbar" ;
VAL_ 418 HMS_parken_nicht_verfuegbar 0 "verfuegbar" 1 "nicht_verfuegbar" ;
VAL_ 418 HMS_Anforderung_GE 0 "keine_Anforderung" 1 "P_einlegen" ;
VAL_ 418 HMS_Systemstatus 0 "keine_Funktion_aktiv" 1 "Halten_aktiv" 2 "Parken_angefordert" 3 "Parken_aktiv" 4 "Parken_beibehalten_aktiv" 5 "Anfahren_aktiv" 6 "Loeseanforderung_aktiv" 7 "Loeseanforderung_durch_Fahrer" 8 "Abrutschen_erkannt" 9 "Halten_Standby_aktiv" 10 "Anfahren_Standby_aktiv" 14 "Init" 15 "Fehler" ;
VAL_ 418 HMS_Stillstand 0 "kein_Stillstand" 1 "Stillstand_frueh" 2 "Stillstand" 6 "Init" 7 "Fehler" ;
VAL_ 418 HMS_aktives_System 0 "kein_System__Init_Fehler" 1 "Fahreranforderung_aktiv" 2 "HMS_intern_aktiv" 3 "ACC_aktiv" 4 "Autohold_aktiv" 5 "HHC_aktiv" 6 "HVLM_aktiv" 7 "Getriebe_aktiv" 8 "EBKV_aktiv" 9 "ParkAssist_aktiv" 10 "ARA_aktiv" 11 "HTO_aktiv" 12 "autonomous_Hold_aktiv" 13 "STA_aktiv" 14 "Motor_aktiv" 15 "EA_aktiv" 16 "VLK_aktiv" 17 "RHP_aktiv" 18 "ORU_aktiv" ;
VAL_ 418 HMS_Konsistenz_HVLM 0 "kein_Fehler_erkannt" 1 "Fehler_erkannt" ;
VAL_ 418 HMS_Konsistenz_ACC 0 "kein_Fehler_erkannt" 1 "Fehler_erkannt" ;
VAL_ 418 HMS_Fehlerstatus 0 "kein_Fehler" 1 "Halten_nicht_moeglich" 2 "Sonderbetriebsmodus_aktiv" 3 "Systemeinschraenkung" 4 "Systemstoerung" ;
VAL_ 418 ESP_Index_Haltemoment 0 "Bremsmoment" 1 "Antriebsmoment" ;
VAL_ 418 ESP_Haltemoment 1022 "Init" 1023 "Fehler" ;
VAL_ 1629 BR_Systemart 0 "ABS" 1 "ABS_ASR" 2 "ESP" 3 "ESP_mit_integrierter_EPB" ;
VAL_ 1629 ESP_SpannungsAnf_02 0 "keine_Anforderung" 1 "Anforderung_Stufe1" 2 "Anforderung_Stufe2" 3 "Anforderung_Stufe3" ;
VAL_ 1629 ESP_Charisma_FahrPr 0 "keine_Funktion" 1 "Programm_1" 2 "Programm_2" 3 "Programm_3" 4 "Programm_4" 5 "Programm_5" 6 "Programm_6" 7 "Programm_7" 8 "Programm_8" 9 "Programm_9" 10 "Programm_10" 11 "Programm_11" 12 "Programm_12" 13 "Programm_13" 14 "Programm_14" 15 "Programm_15" ;
VAL_ 1629 ESP_Charisma_Status 0 "Init" 1 "verfuegbar" 2 "nicht_verfuegbar" 3 "asynchron_durch_Fahrerwunsch" ;
VAL_ 1629 ESP_Wiederstart_Anz_01 0 "keine_Anzeige" 1 "Rueckwaertsrollen" ;
VAL_ 1629 ESP_Wiederstart_Anz_02 0 "keine_Anzeige" 1 "Autohold_Rutschen" ;
VAL_ 1629 ESP_Wiederstart_Anz_03 0 "keine_Anzeige" 1 "Offroad_HDC" ;
VAL_ 1629 ESP_Wiederstart_Anz_04 0 "keine_Anzeige" 1 "ESC_Off" ;
VAL_ 1629 ESP_Stoppverbot_Anz_01 0 "keine_Anzeige" 1 "Notbremsung_aktiv" ;
VAL_ 1629 ESP_Stoppverbot_Anz_02 0 "keine_Anzeige" 1 "Autohold_AVH_Rutschen" ;
VAL_ 1629 ESP_Stoppverbot_Anz_03 0 "keine_Anzeige" 1 "Rueckwaertsrollen" ;
VAL_ 1629 ESP_Stoppverbot_Anz_04 0 "keine_Anzeige" 1 "ESP_Pumpenlauf" ;
VAL_ 1629 ESP_Stoppverbot_Anz_05 0 "keine_Anzeige" 1 "ESP_OFF" ;
VAL_ 1629 ESP_Stoppverbot_Anz_06 0 "keine_Anzeige" 1 "Offroad_HDC" ;
VAL_ 1629 ESP_Stoppverbot_Anz_07 0 "keine_Anzeige" 1 "ESP_Haltefunktion_nicht_verfuegbar" ;
VAL_ 1629 ESP_Stoppverbot_Anz_Std 0 "keine_Anzeige" 1 "Standard_Stoppvetogrund" ;
VAL_ 1629 ESP_Dachrelingsensor 0 "Sensor_nicht_verbaut" 1 "Quertraeger_montiert" 2 "Quertraeger_nicht_montiert" 3 "Fehler" ;
VAL_ 1629 ESP_Stoppverbot_Anz_08 0 "keine_Anzeige" 1 "Neigungsbegrenzung" ;
VAL_ 1629 HDC_Charisma_FahrPr 0 "keine_Funktion" 1 "Programm_1" 2 "Programm_2" 3 "Programm_3" 4 "Programm_4" 5 "Programm_5" 6 "Programm_6" 7 "Programm_7" 8 "Programm_8" 9 "Programm_9" 10 "Programm_10" 11 "Programm_11" 12 "Programm_12" 13 "Programm_13" 14 "Programm_14" 15 "Programm_15" ;
VAL_ 1629 HDC_Charisma_Status 0 "Init" 1 "verfuegbar" 2 "nicht_verfuegbar" 3 "asynchron_durch_Fahrerwunsch" ;
VAL_ 1629 BR_QBit_Reifenumfang 0 "gueltiger_Wert" 1 "Ersatz_Init_oder_Fehlerwert" ;
VAL_ 253 BR_Eingriffsmoment 1022 "Init" 1023 "Fehler" ;
VAL_ 253 MSR_verfuegbar 0 "verfuegbar" 1 "nicht_verfuegbar" ;
VAL_ 253 ESP_Diagnose 0 "ESP_nicht_in_Diagnose" 1 "ESP_in_Diagnose" ;
VAL_ 253 ESC_v_Signal_Qualifier_High_Low 0 "Gueteschwelle_kleiner_1kmh" 1 "Gueteschwelle_kleiner_3kmh" 2 "Gueteschwelle_kleiner_5kmh" 3 "Gueteschwelle_kleiner_10kmh" 4 "Gueteschwelle_kleiner_20kmh" 5 "Gueteschwelle_groessergleich_20kmh" 6 "Init" 7 "Fehler" ;
VAL_ 253 ESP_Vorsteuerung 0 "keine_Vorsteuerung_aktiv" 1 "Vorsteuerung_aktiv" ;
VAL_ 253 OBD_Schlechtweg 0 "kein_Schlechtweg_erkannt" 1 "Schlechtweg_erkannt" ;
VAL_ 253 OBD_QBit_Schlechtweg 0 "gueltiger_Wert" 1 "Ersatz_Init_oder_Fehlerwert" ;
VAL_ 253 ESP_v_Signal 65533 "Unterspannung" 65534 "Init" 65535 "Fehler" ;
VAL_ 253 ASR_Tastung_passiv 0 "ASR_aktiviert" 1 "ASR_passiv_getastet_oder_Schwellen_geaendert" ;
VAL_ 253 ESP_Tastung_passiv 0 "ESP_aktiviert" 1 "ESP_passiv_getastet_oder_Schwellen_geaendert" ;
VAL_ 253 ESP_Systemstatus 0 "iO" 1 "Fehler" ;
VAL_ 253 ASR_Schalteingriff 0 "keine_Anforderung" 1 "ASR_Schaltkennfeld" 2 "Rueckschaltung" 3 "Schaltverbot" ;
VAL_ 253 ESP_QBit_v_Signal 0 "gueltiger_Wert" 1 "Ersatz_Init_oder_Fehlerwert" ;
VAL_ 253 ABS_Bremsung 0 "keine_ABS_Regelung" 1 "ABS_Regelung_aktiv" ;
VAL_ 253 ASR_Anf 0 "keine_Anforderung" 1 "ASR_Anforderung" ;
VAL_ 253 MSR_Anf 0 "keine Anfoderung" 1 "MSR-Anforderung" ;
VAL_ 253 EBV_Eingriff 0 "kein_EBV_Eingriff" 1 "EBV_Eingriff" ;
VAL_ 253 EDS_Eingriff 0 "kein_EDS_Eingriff" 1 "EDS_Eingriff" ;
VAL_ 253 ESP_Eingriff 0 "kein_ESP_Eingriff" 1 "ESP_Eingriff_aktiv" ;
VAL_ 253 ESP_ASP 0 "inaktiv" 1 "aktiv" ;
VAL_ 253 ESC_Neutralschaltung 0 "keine_Anforderung" 1 "Neutralschaltung_angefordert" ;
VAL_ 427 ESC_AHW_aktiv 0 "keine_Aktivitaet" 1 "Aktivitaet_durch_IPA" 2 "Aktivitaet_durch_ARA" 3 "Aktivitaet_durch_ACC" 4 "tbd" 5 "tbd" 6 "tbd" 7 "tbd" ;
VAL_ 427 ESC_AHW_nicht_verfuegbar 0 "verfuegbar" 1 "nicht_verfuegbar" ;
VAL_ 427 ESC_ANB_CM_aktiv 0 "keine_Aktivitaet" 1 "Aktivitaet_durch_AWV" ;
VAL_ 427 ESC_ANB_CM_nicht_verfuegbar 0 "verfuegbar" 1 "nicht_verfuegbar" ;
VAL_ 427 ESC_Warnruck_aktiv 0 "keine_Aktivitaet" 1 "Aktivitaet_durch_AWV" 2 "Aktivitaet_durch_vFGS" 3 "Aktivitaet_durch_RCTA" 4 "Aktivitaet_durch_FCWO" 5 "Aktivitaet_durch_FCWP" 6 "Aktivitaet_durch_EA" 7 "Aktivitaet_durch_PCF" 8 "Aktivitaet_durch_KAS" 9 "Aktivitaet_durch_AGW" ;
VAL_ 427 ESC_Warnruck_nicht_verfuegbar 0 "verfuegbar" 1 "nicht_verfuegbar" ;
VAL_ 427 ESC_Prefill_aktiv 0 "keine_Aktivitaet" 1 "Prefill_aktiv" ;
VAL_ 427 ESC_Prefill_nicht_verfuegbar 0 "verfuegbar" 1 "nicht_verfuegbar" ;
VAL_ 427 ESC_HBA_aktiv 0 "keine_Aktivitaet" 1 "HBA_aktiv" ;
VAL_ 427 ESC_HBA_nicht_verfuegbar 0 "verfuegbar" 1 "nicht_verfuegbar" ;
VAL_ 427 ESC_TSK_SRBM_Anf 0 "keine_Aktivitaet" 1 "Aktivitaet_durch_TSK" ;
VAL_ 427 ESC_TSK_SRBM_nicht_verfuegbar 0 "verfuegbar" 1 "nicht_verfuegbar" ;
VAL_ 427 ESC_Verz_Reg_aktiv 0 "keine_Aktivitaet" 1 "Aktivitaet_TB_durch_AWV" 2 "Aktivitaet_ZB_durch_AWV" 3 "Aktivitaet_durch_vFGS" 4 "Aktivitaet_durch_TSK" 5 "Aktivitaet_durch_RCTA" 6 "Aktivitaet_durch_PLA_IPA" 7 "Aktivitaet_durch_STA" 8 "Aktivitaet_durch_ARA" 9 "Aktivitaet_durch_MKB" 10 "Aktivitaet_durch_BFF" 11 "Aktivitaet_durch_FAS_VK" 12 "Aktivitaet_durch_PCF" 13 "Aktivitaet_durch_KAS" 14 "Aktivitaet_durch_BRS_intern" 15 "reserviert" ;
VAL_ 427 ESC_Verz_Reg_nicht_verfuegbar 0 "verfuegbar" 1 "nicht_verfuegbar" ;
VAL_ 427 ESC_Verz_Reg_TB_nicht_verfuegbar 0 "verfuegbar" 1 "nicht_verfuegbar" ;
VAL_ 427 ESC_Verz_Reg_ZB_nicht_verfuegbar 0 "verfuegbar" 1 "nicht_verfuegbar" ;
VAL_ 427 ESC_Bremslicht_unplausibel 0 "plausibel" 1 "unplausibel" ;
VAL_ 427 ESC_Konsistenz_ACC 0 "konsistent" 1 "nicht_konsistent" ;
VAL_ 427 ESC_Konsistenz_AWV 0 "konsistent" 1 "nicht_konsistent" ;
VAL_ 427 ESC_Konsistenz_ARA 0 "konsistent" 1 "nicht_konsistent" ;
VAL_ 427 ESC_Konsistenz_IPA 0 "konsistent" 1 "nicht_konsistent" ;
VAL_ 427 ESC_Konsistenz_FCW 0 "konsistent" 1 "nicht_konsistent" ;
VAL_ 427 ESC_Konsistenz_NV 0 "konsistent" 1 "nicht_konsistent" ;
VAL_ 427 ESC_Konsistenz_RCTA 0 "konsistent" 1 "nicht_konsistent" ;
VAL_ 427 ESC_Konsistenz_TSK 0 "konsistent" 1 "nicht_konsistent" ;
VAL_ 427 ESC_Konsistenz_vFGS 0 "konsistent" 1 "nicht_konsistent" ;
VAL_ 427 ESC_Konsistenz_STA 0 "konsistent" 1 "nicht_konsistent" ;
VAL_ 427 ESC_Fahrer_Bremsdruck_bestimmend 0 "Fahrer_nicht_Bremsdruck_bestimmend" 1 "Fahrer_Bremsdruck_bestimmend" ;
VAL_ 427 ESC_Konsistenz_EA 0 "konsistent" 1 "nicht_konsistent" ;
VAL_ 427 ESC_Konsistenz_BFF 0 "konsistent" 1 "nicht_konsistent" ;
VAL_ 427 ESC_Konsistenz_MKB 0 "konsistent" 1 "nicht_konsistent" ;
VAL_ 427 ESC_Verz_ASIL_Verfuegbarkeit 0 "Nicht_verfuegbar" 1 "Verfuegbar_ab_ASIL_QM" 2 "Verfuegbar_ab_ASIL_A" 3 "Verfuegbar_ab_ASIL_B" 4 "Verfuegbar_ab_ASIL_C" 5 "reserved" 6 "reserved" 7 "reserved" ;
VAL_ 427 ESC_Pumpenanlauf_aktiv 0 "inaktiv" 1 "aktiv" ;
VAL_ 427 ESC_Konsistenz_AGW 0 "konsistent" 1 "nicht_konsistent" ;
VAL_ 427 ESC_Konsistenz_KAS 0 "konsistent" 1 "nicht_konsistent" ;
VAL_ 427 ESC_Konsistenz_PCF 0 "konsistent" 1 "nicht_konsistent" ;
VAL_ 427 ESC_Konsistenz_FAS_VK 0 "konsistent" 1 "nicht_konsistent" ;
VAL_ 427 ESC_Verz_Begrenzung 0 "keine_Begrenzung" 1 "Begrenzung_aktiv" ;
VAL_ 427 ESC_Konsistenz_AWA 0 "konsistent" 1 "nicht_konsistent" ;
VAL_ 264 FA_Hoehenwerte_kalibriert 0 "kalibrierte_Hoehenwerte_in_mm" 1 "Rohwerte" ;
VAL_ 264 EFP_Anf_Bremsenkuehlung 0 "keine_Anforderung" 1 "SKE_oeffnen" 2 "SKE_oeffnen_Luefter_ansteuern" ;
VAL_ 264 FA_Hoehenwert_VL_00 254 "nicht initialisiert" 255 "Fehler" ;
VAL_ 264 FA_Hoehenwert_VR_00 254 "nicht initialisiert" 255 "Fehler" ;
VAL_ 264 FA_Hoehenwert_HL_00 254 "nicht initialisiert" 255 "Fehler" ;
VAL_ 264 FA_Hoehenwert_HR_00 254 "nicht initialisiert" 255 "Fehler" ;
VAL_ 264 FA_Fahrbahnunebenheit 254 "Init" 255 "Fehler" ;
VAL_ 264 EFP_Reibwert_dyn 62 "Init" 63 "Fehler" ;
VAL_ 2463978619 FAS_SollStatus_Fkt_ASW 0 "Init" 1 "Funktion_ein" 2 "Funktion_aus" ;
VAL_ 2463978619 FAS_SollStatus_Fkt_SWA 0 "Init" 1 "Funktion_ein" 2 "Funktion_aus" ;
VAL_ 2463978619 FAS_SollStatus_Fkt_MKE 0 "Init" 1 "Funktion_ein" 2 "Funktion_aus" ;
VAL_ 2463978619 FAS_SollStatus_Fkt_NV 0 "Init" 1 "Funktion_ein" 2 "Funktion_aus" ;
VAL_ 2463978619 FAS_SollStatus_Fkt_AbstWarn_MV 0 "Init" 1 "Funktion_ein" 2 "Funktion_aus" ;
VAL_ 2463978619 FAS_SollStatus_Fkt_STP 0 "Init" 1 "Funktion_ein" 2 "Funktion_aus" ;
VAL_ 2463978619 FAS_SollStatus_Fkt_PreCrash 0 "Init" 1 "Funktion_ein" 2 "Funktion_aus" ;
VAL_ 2463978619 FAS_SollStatus_Fkt_LGI 0 "Init" 1 "Funktion_ein" 2 "Funktion_aus" ;
VAL_ 2463978619 FAS_SollStatus_Fkt_AbstWarn_LRR 0 "Init" 1 "Funktion_ein" 2 "Funktion_aus" ;
VAL_ 1332 FCWO_Texte 0 "keine_Anzeige" 1 "Systemstoerung" 2 "keine_Sensorsicht" 3 "Demomodus" 4 "System_aus" 5 "nicht_definiert" 6 "ESC_aus" 7 "zurzeit_eingeschraenkt" ;
VAL_ 1332 FCWO_Warnung 0 "keine_Anzeige" 1 "latente_Vorwarnung" 2 "Vorwarnung" 3 "Akutwarnung" 4 "nicht_definiert" 5 "nicht_definiert" 6 "nicht_definiert" 7 "nicht_definiert" ;
VAL_ 1332 FCWP_Texte 0 "keine_Anzeige" 1 "Systemstoerung" 2 "keine_Sensorsicht" 3 "Demomodus" 4 "System_aus" 5 "nicht_definiert" 6 "ESC_aus" 7 "zurzeit_eingeschraenkt" ;
VAL_ 1332 FCWP_Warnung 0 "keine_Anzeige" 1 "latente_Vorwarnung" 2 "Vorwarnung" 3 "Akutwarnung" 4 "nicht_definiert" 5 "nicht_definiert" 6 "nicht_definiert" 7 "nicht_definiert" ;
VAL_ 1332 FCWO_LED_Leiste 0 "keine_Anzeige" 1 "Stufe_1_glimmen" 2 "Stufe_2_leuchten" 3 "nicht_definiert" ;
VAL_ 1332 FCWP_LED_Leiste 0 "keine_Anzeige" 1 "Stufe_1_glimmen" 2 "Stufe_2_leuchten" 3 "nicht_definiert" ;
VAL_ 1332 FCWO_Warnlevel 0 "keine Gefährdung" 63 "max. Gefährdung" ;
VAL_ 1332 FCWP_Warnlevel 0 "keine Gefährdung" 63 "max. Gefährdung" ;
VAL_ 1332 FCWO_Charisma_FahrPr 0 "keine_Funktion" 1 "Programm_1" 2 "Programm_2" 3 "Programm_3" 4 "Programm_4" 5 "Programm_5" 6 "Programm_6" 7 "Programm_7" 8 "Programm_8" 9 "Programm_9" 10 "Programm_10" 11 "Programm_11" 12 "Programm_12" 13 "Programm_13" 14 "Programm_14" 15 "Programm_15" ;
VAL_ 1332 FCWO_Charisma_Status 0 "Init" 1 "verfuegbar" 2 "nicht_verfuegbar" 3 "asynchron_durch_Fahrerwunsch" ;
VAL_ 1332 FCWP_Charisma_Status 0 "Init" 1 "verfuegbar" 2 "nicht_verfuegbar" 3 "asynchron_durch_Fahrerwunsch" ;
VAL_ 1332 FCWP_Charisma_FahrPr 0 "keine_Funktion" 1 "Programm_1" 2 "Programm_2" 3 "Programm_3" 4 "Programm_4" 5 "Programm_5" 6 "Programm_6" 7 "Programm_7" 8 "Programm_8" 9 "Programm_9" 10 "Programm_10" 11 "Programm_11" 12 "Programm_12" 13 "Programm_13" 14 "Programm_14" 15 "Programm_15" ;
VAL_ 1605 FLA_aktiv 0 "inaktiv" 1 "aktiv" ;
VAL_ 1605 FLA_ISP_defekt 0 "iO" 1 "defekt" ;
VAL_ 1605 FLA_Sensor_blockiert 0 "Sensor in Ordnung" 1 "Sensor blockiert" ;
VAL_ 1605 FLA_Abblendursache 0 "nichts erkannt (Init-Wert)" 1 "enentgegenkommendes Fahrzeug (Scheinwerfer erkannt)" 2 "vorausfahrendes Fahrzeug (Heckleuchten erkannt)" 4 "Geschwindigkeitslimit unterschritten" 8 "Ort_oder_Infrastruktur_erkannt" 16 "Umgebungshelligkeit_generell_zu_hell" 32 "Nebel_oder_Sensor_blockiert" 64 "Übertemperatur Imager" 128 "Verzögerungsbedingung" 255 "Fehler" ;
VAL_ 1605 FLA_Fernlicht_PWM 127 "Fehler" ;
VAL_ 1605 ISP_EC_Lichtwert_vorne 62 "Init" 63 "Fehler" ;
VAL_ 1605 ISP_EC_Lichtwert_hinten 62 "Init" 63 "Fehler" ;
VAL_ 1605 ISP_Himmelsrichtung 30 "nicht verfuegbar bzw. Init" 31 "Fehler" ;
VAL_ 1605 ISP_Taste_betaetigt 0 "nicht_betaetigt" 1 "betaetigt" ;
VAL_ 1605 ISP_EC_aktiv 0 "inaktiv" 1 "aktiv" ;
VAL_ 1605 ISP_Kompass_aktiv 0 "inaktiv" 1 "aktiv" ;
VAL_ 1605 FLA_Aufblenden 0 "nicht_aufblenden" 1 "aufblenden" ;
VAL_ 1605 FLA_SAE_Mode 0 "Init" 1 "FLA_Icon_invertiert" ;
VAL_ 2589283684 FoD_Transmission_Info 0 "Initwert" 1 "start_transmission" 2 "finish_transmission" ;
VAL_ 2589283684 FoD_Anz_Funktionsabschaltung 0 "Init" 1 "Popup_aufschalten" ;
VAL_ 173 GE_MMom_Soll_02 1022 "keine_Anforderung_Init" 1023 "Fehler" ;
VAL_ 173 GE_MMom_Vorhalt_02 1022 "Init" 1023 "Fehler" ;
VAL_ 173 GE_Uefkt 1023 "Fehler" ;
VAL_ 173 GE_Fahrstufe 0 "Zwischenstellung" 1 "Init" 5 "Position_P" 6 "Position_R" 7 "Position_N" 8 "Position_D" 9 "Position_S" 10 "Effizienz" 13 "Tipp_in_S" 14 "Tipp_in_D" 15 "Fehler" ;
VAL_ 173 GE_Schaltablauf 0 "keine_Schaltung" 1 "Momentenueberschneidung" 2 "Befuellphase" 3 "Drehzahlueberfuehrung" ;
VAL_ 173 GE_Uefkt_unplausibel 0 "Uefkt_plausibel" 1 "Uefkt_unplausibel" ;
VAL_ 173 GE_MMom_Status_02 0 "kein_Eingriff" 1 "abs_reduzierender_Eingriff_auf_Gesamt_Antrieb_nur_schneller_Pfad" 2 "abs_erhoehender_Eingriff_auf_Gesamt_Antrieb" 3 "relativer_Eingriff_auf_Gesamt_Antrieb" 4 "relativer_Eingriff_auf_E_Maschine" 5 "abs_red_Eingr_auf_Gesamt_Antrieb_nur_Luftpfad" 6 "abs_red_Eingr_auf_Gesamt_Antrieb_Luft-_und_schnellen_Pfad" 7 "abs_Eingriff_auf_Gesamtantrieb_erhoehend_und_reduzierend" ;
VAL_ 173 GE_Status_Kraftschluss 0 "offen_kein_Kraftschluss" 1 "offen_mit_Kraftschluss" 2 "schlupfend_geregelt" 3 "abgesichert_offen_kein_Kraftschl" 4 "geschlossen_mit_Mikroschlupf" 5 "geschlossen_mit_Ueberanpressung" 6 "sonstige_Fehler" 7 "fehlerhaft_geschlossen" ;
VAL_ 173 GE_MMom_Status 0 "keine Anforderung" 1 "reduzierender Getriebeeingriff" 2 "erhöhender Getriebeeingriff" 3 "Änderung mit Sprung" ;
VAL_ 173 GE_Freig_MMom_Vorhalt 0 "nicht_freigegeben" 1 "freigegeben" ;
VAL_ 173 GE_Verbot_Ausblendung 0 "kein_Verbot" 1 "Verbot" ;
VAL_ 173 GE_Zielgang 0 "Gang P/N (ausgekuppelt)" 1 "Gang 1" 2 "Gang 2" 3 "Gang 3" 4 "Gang 4" 5 "Gang 5" 6 "Gang 6" 7 "Gang 7" 8 "Gang R" 11 "Gang 8" 12 "Gang 9" 13 "Gang10" 14 "Istgang nicht definiert" 15 "Fehler" ;
VAL_ 968 GE_OBD_AbsperrVent 0 "kein Fehler / Init / nicht verbaut" 1 "KS- (Kurzschluss nach minus)" 2 "KS+ (Kurzschluss nach plus)" 3 "OC (Leitungsunterbrechung)" 4 "OOR+ (Signal zu gross)" 5 "OOR- (Signal zu klein)" 6 "RC+ (Signal unplausibel zu gross)" 7 "RC- (Signal unplausibel zu klein)" 8 "KS+/OC (Kurzschluss nach plus/Unterbrechung)" 9 "KS-/OC  (Kurzschluss nach minus/Unterbrechung)" 10 "KS-/KS+  (Kurzschluss nach minus/plus)" 11 "KS-/KS+/OC (Kurzschluss nach minus/plus/Unterbrechung)" 12 "Position_unbekannt" 13 "Failsafe_Position" 14 "Referenzfahrt_aktiv" 15 "frei" ;
VAL_ 968 GE_amax_moeglich 511 "nicht_definiert" ;
VAL_ 968 GE_Charisma_FahrPr 0 "keine_Funktion" 1 "Programm_1" 2 "Programm_2" 3 "Programm_3" 4 "Programm_4" 5 "Programm_5" 6 "Programm_6" 7 "Programm_7" 8 "Programm_8" 9 "Programm_9" 10 "Programm_10" 11 "Programm_11" 12 "Programm_12" 13 "Programm_13" 14 "Programm_14" 15 "Programm_15" ;
VAL_ 968 GE_Charisma_Status 0 "Init" 1 "verfuegbar" 2 "nicht_verfuegbar" 3 "asynchron_durch_Fahrerwunsch" ;
VAL_ 968 GE_Freigabe_Verfallsinfo_WFS 0 "Aus" 1 "Ein" ;
VAL_ 968 GE_LaunchControl_LB 0 "init" 1 "LC_not_available" 2 "LCperformance_not_possible" 3 "LCperformance_possible" 4 "LCperformance_armed" 5 "LCperformance_preparation" 6 "LCperformance_launch" 7 "LCperformance_aborted" 8 "LCsmoke_not_possible" 9 "LCsmoke_possible" 10 "LCsmoke_armed" 11 "LCsmoke_launch" 12 "LCsmoke_aborted" 13 "reserved" 14 "reserved" ;
VAL_ 968 GE_Status_PaddleNeutral 0 "Paddle_Neutral_inaktiv" 1 "Paddle_Neutral_aktiv" 2 "Paddle_Neutral_Ende_Timer_aktiv" 3 "Paddle_Neutral_Zwangsausstieg" ;
VAL_ 968 GE_Remotestart_Betrieb 0 "GSG_nicht_bereit_fuer_RS" 1 "GSG_bereit_fuer_oder_im_RS" ;
VAL_ 968 Freilauf_Charisma_FahrPr 0 "keine_Funktion" 1 "Programm_1" 2 "Programm_2" 3 "Programm_3" 4 "Programm_4" 5 "Programm_5" 6 "Programm_6" 7 "Programm_7" 8 "Programm_8" 9 "Programm_9" 10 "Programm_10" 11 "Programm_11" 12 "Programm_12" 13 "Programm_13" 14 "Programm_14" 15 "Programm_15" ;
VAL_ 968 Freilauf_Charisma_Status 0 "Init" 1 "verfuegbar" 2 "nicht_verfuegbar" 3 "asynchron_durch_Fahrerwunsch" ;
VAL_ 968 GE_Freigabe_Info_WFS 0 "ungueltig" 1 "gueltig" ;
VAL_ 968 GE_Sperr_Info_WFS 0 "nicht_gesperrt" 1 "gesperrt" ;
VAL_ 968 GE_Zustand_Kuppltemp 0 "Init" 1 "Kupplungstemp_normal" 2 "Kupplungstemp_hoch" 3 "Kupplungsschutz_aktivieren" ;
VAL_ 968 GE_Codierung_MSG 0 "Codierung iO / Init" 1 "Codierung niO" ;
VAL_ 968 GE_LaunchControl 0 "inaktiv" 1 "aktiv" ;
VAL_ 968 GE_Heizwunsch 0 "maximaler_Waermebedarf" 1 "kein_Waermebedarf" 2 "Kuehlbedarf" 3 "Notfall_(maximaler_Kuehlbedarf)" ;
VAL_ 968 GE_OBD_Status 0 "MIL aus" 1 "MIL ein" ;
VAL_ 968 GE_LFR_Adaption 0 "fuer_Adaption_geeignet" 1 "fuer_Adaption_nicht_geeignet" ;
VAL_ 968 GE_Sumpftemperatur 255 "Fehler" ;
VAL_ 310 HAL_Status 0 "Normalbetrieb" 1 "Lenkungsausfall" 2 "Derating_aktiv" 3 "Lenkung_manuell_deaktiviert" ;
VAL_ 310 HAL_VZ_Radwinkel 0 "positiv_Lenkeinschlag_links" 1 "negativ_Lenkeinschlag_rechts" ;
VAL_ 310 HAL_QBit_Radwinkel 0 "gueltiger_Wert" 1 "Ersatz_Init_oder_Fehlerwert" ;
VAL_ 310 HAL_Radwinkel 1020 "Unterspannung" 1021 "nicht_kalibriert" 1022 "Init" 1023 "Fehler" ;
VAL_ 310 HAL_Warnungen 0 "keine_Warnung" 1 "Ausfall_rote_Warnung" 2 "Systemstoerung_gelbe_Warnung" 3 "HAL_deaktiviert" ;
VAL_ 310 HAL_Winkelbegrenzung 0 "nicht_aktiv" 1 "Lenkwinkelbegrenzung_aktiv" ;
VAL_ 310 HAL_VZ_Fahrerwunschwinkel_Soll 0 "positiv" 1 "negativ" ;
VAL_ 310 HAL_Fahrerwunschwinkel_Soll 1022 "Init" 1023 "Fehler" ;
VAL_ 310 HAL_max_Gradient 126 "Init" 127 "Fehler" ;
VAL_ 310 HAL_EFP_FahrPr 0 "keine_Funktion" 1 "Programm_1" 2 "Programm_2" 3 "Programm_3" 4 "Programm_4" 5 "Programm_5" 6 "Programm_6" 7 "Programm_7" 8 "Programm_8" 9 "Programm_9" 10 "Programm_10" 11 "Programm_11" 12 "Programm_12" 13 "Programm_13" 14 "Programm_14" 15 "Programm_15" ;
VAL_ 310 HAL_Status_2 0 "Init" 1 "Fahrbereit" 2 "Symmetriefahrt" 3 "Gelbe_Warnung" 4 "Rote_Warnung" 5 "Hinterachlenkung_deaktiviert" ;
VAL_ 310 HAL_Charisma_Status 0 "Init" 1 "verfuegbar" 2 "nicht_verfuegbar" 3 "asynchron_durch_Fahrerwunsch" ;
VAL_ 310 HAL_Charisma_FahrPr 0 "keine_Funktion" 1 "Programm_1" 2 "Programm_2" 3 "Programm_3" 4 "Programm_4" 5 "Programm_5" 6 "Programm_6" 7 "Programm_7" 8 "Programm_8" 9 "Programm_9" 10 "Programm_10" 11 "Programm_11" 12 "Programm_12" 13 "Programm_13" 14 "Programm_14" 15 "Programm_15" ;
VAL_ 1524 IL_Bel_FS_Ausstieg 0 "inaktiv" 1 "aktiv" ;
VAL_ 1524 IL_Bel_BFS_Ausstieg 0 "inaktiv" 1 "aktiv" ;
VAL_ 1524 IL_Bel_HFS_Ausstieg 0 "inaktiv" 1 "aktiv" ;
VAL_ 1524 IL_Bel_HBFS_Ausstieg 0 "inaktiv" 1 "aktiv" ;
VAL_ 1524 BCM1_Innenlicht_gedimmt_V 0 "100% Innenlicht" 1 "gedimmtes Innenlicht" ;
VAL_ 1524 BCM1_Innenlicht_gedimmt_H 0 "100% Innenlicht" 1 "gedimmtes Innenlicht" ;
VAL_ 1524 IL_Innenlicht_aktiv 0 "Innenlicht inaktiv" 1 "Innenlicht aktiv" ;
VAL_ 1524 IL_Klemme_30G_aktiv 0 "Kl_30G_abgeschaltet" 1 "eingeschaltet" ;
VAL_ 1524 BCM1_DI_Rampe_Innenlicht 0 "Dimmrampe 0" 1 "Dimmrampe 1" ;
VAL_ 1524 BCM1_DI_Rampe_Leselicht 0 "Dimmrampe 0" 1 "Dimmrampe 1" ;
VAL_ 1524 BCM1_Innenlicht_H 0 "Aus" 1 "Ein" ;
VAL_ 1524 BCM1_Innenlicht_V 0 "Aus" 1 "Ein" ;
VAL_ 1524 BCM1_Leselicht_Anf_hl 0 "Aus" 1 "Ein" ;
VAL_ 1524 BCM1_Leselicht_Anf_hr 0 "Aus" 1 "Ein" ;
VAL_ 1524 BCM1_Leselicht_Anf_vl 0 "Aus" 1 "Ein" ;
VAL_ 1524 BCM1_Leselicht_Anf_vr 0 "Aus" 1 "Ein" ;
VAL_ 1524 BCM1_Leuchten_Aus 0 "keine Aenderung" 1 "Aus" ;
VAL_ 1524 AMB_Charisma_FahrPr 0 "keine_Funktion" 1 "Programm_1" 2 "Programm_2" 3 "Programm_3" 4 "Programm_4" 5 "Programm_5" 6 "Programm_6" 7 "Programm_7" 8 "Programm_8" 9 "Programm_9" 10 "Programm_10" 11 "Programm_11" 12 "Programm_12" 13 "Programm_13" 14 "Programm_14" 15 "Programm_15" ;
VAL_ 1524 AMB_Charisma_Status 0 "Init" 1 "verfuegbar" 2 "nicht_verfuegbar" 3 "asynchron_durch_Fahrerwunsch" ;
VAL_ 497 KY_IDG_in_Reichweite 0 "ausser_Reichweite_bzw_nicht_ermittelbar" 1 "innerhalb_Reichweite" ;
VAL_ 497 KY_Auf_Taste 0 "Taste_nicht_betaetigt" 1 "Oeffnentaste_betaetigt" ;
VAL_ 497 KY_HDF_Taste 0 "Taste_nicht_betaetigt" 1 "HDF_Taste_am_Funkschluessel_betaetigt" ;
VAL_ 497 KY_Panik_Taste 0 "Taste_nicht_betaetigt" 1 "Panik_Taste_am_Funkschluessel_betaetigt" ;
VAL_ 497 KY_Zu_Taste 0 "Taste_nicht_betaetigt" 1 "Zu_Taste_am_Funkschluessel_betaetigt" ;
VAL_ 497 KY_FT_Entriegelung_Autorisiert 0 "kein_Keylessschluessel_erkannt" 1 "Keyless_Schluessel_erkannt_und_authorisiert" ;
VAL_ 497 KY_FT_Verriegelung_Autorisiert 0 "kein_Verriegelungssensor_erkannt" 1 "Verriegelungssensor_erkannt_und_authorisiert" ;
VAL_ 497 KY_BT_Entriegelung_Autorisiert 0 "kein_Keylessschluessel_erkannt" 1 "Keyless_Schluessel_erkannt_und_authorisiert" ;
VAL_ 497 KY_BT_Verriegelung_Autorisiert 0 "kein_Verriegelungssensor_erkannt" 1 "Verriegelungssensor_erkannt_und_authorisiert" ;
VAL_ 497 KY_HFS_Entriegelung_Autorisiert 0 "kein_Keylessschluessel_erkannt" 1 "Keyless_Schluessel_erkannt_und_authorisiert" ;
VAL_ 497 KY_HFS_Verriegelung_Autorisiert 0 "kein_Verriegelungssensor_erkannt" 1 "Verriegelungssensor_erkannt_und_authorisiert" ;
VAL_ 497 KY_HBFS_Entriegelung_Autorisiert 0 "kein_Keylessschluessel_erkannt" 1 "Keyless_Schluessel_erkannt_und_authorisiert" ;
VAL_ 497 KY_HBFS_Verriegelung_Autorisiert 0 "kein_Verriegelungssensor_erkannt" 1 "Verriegelungssensor_erkannt_und_authorisiert" ;
VAL_ 497 KY_Front_Entr_Autorisiert 0 "kein_Keylessschluessel_erkannt" 1 "Keyless_Schluessel_erkannt_und_authorisiert" ;
VAL_ 497 KY_Front_Verr_Autorisiert 0 "kein_Verriegelungssensor_erkannt" 1 "Verriegelungssensor_erkannt_und_authorisiert" ;
VAL_ 497 KY_HD_Entriegelung_Autorisiert 0 "kein_Keylessschluessel_erkannt" 1 "Keyless_Schluessel_erkannt_und_authorisiert" ;
VAL_ 497 KY_HD_Verriegelung_Autorisiert 0 "nicht_autorisiert" 1 "autorisiert" ;
VAL_ 497 KY_Bereich 0 "Bereich_0" 1 "Bereich_1" 2 "Bereich_2" 3 "Bereich_3" 4 "Bereich_4" 5 "Bereich_5" 6 "Kein_Schluessel_gefunden" 7 "Init" ;
VAL_ 497 KY_Position 0 "Position_0" 1 "Postition_1" 2 "Postition_2" 3 "Postition_3" 4 "Postition_4" 6 "Kein_Schluessel_gefunden" 7 "Init" ;
VAL_ 497 Schluesselnr_Personalisierung 1 "Schluesselnummer_eins_aktiv" 2 "Schluesselnummer_zwei_aktiv" 3 "Schluesselnummer_drei_aktiv" 4 "Schluesselnummer_vier_aktiv" 5 "Schluesselnummer_fuenf_aktiv" 6 "Schluesselnummer_sechs_aktiv" 7 "Schluesselnummer_sieben_aktiv" 8 "Schluesselnummer_acht_aktiv" 14 "Init" 15 "Fehler" ;
VAL_ 497 FFB_FDF_Taste 0 "Taste_nicht_betaetigt" 1 "FDF_Taste_am_Funkschluessel_betaetigt" ;
VAL_ 497 FFB_Joker_Taste 0 "Taste_nicht_betaetigt" 1 "Joker_Taste_an_FFFB_betaetigt" ;
VAL_ 497 FFB_Park_Taste 0 "Taste_nicht_betaetigt" 1 "Park_Taste_betaetigt" ;
VAL_ 497 FFB_Remotestart_Taste 0 "Taste_nicht_betaetigt" 1 "Remotestart_Taste_betaetigt" ;
VAL_ 497 FBS_Aktivierung_Pilot_Parken 0 "keine_Funktionsaktivierung" 1 "Aktivierung_FFB_erkannt" ;
VAL_ 497 KY_Schluessel_im_Fzg 0 "Schluessel_nicht_im_Fahrzeug" 1 "Schluessel_im_Fahrzeug" ;
VAL_ 497 KY_EasyClose_Abbruch 0 "EasyClose_kein_Abbruch" 1 "EasyClose_Abbruch" ;
VAL_ 497 KY_EasyClose_Status 0 "Lampe_AUS" 1 "Lampe_EIN" 2 "Lampe_NORMAL" 3 "Lampe_HEKTIK" 4 "Akustik_Verweigerung" ;
VAL_ 497 KY_HD_Auffahrt 0 "keine_Anforderung" 1 "HD_Auffahrt_angefordert" ;
VAL_ 497 KY_HD_Zufahrt 0 "keine_Anforderung" 1 "HD_Zufahrt_angefordert" ;
VAL_ 497 KY_LKL_1_Autorisierung 0 "Kein_Zugang_LKL_1_erkannt" 1 "Zugang_LKL_1_erkannt" ;
VAL_ 497 KY_LKL_2_Autorisierung 0 "Kein_Zugang_LKL_2_erkannt" 1 "Zugang_LKL_2_erkannt" ;
VAL_ 960 RSt_Fahrerhinweise 0 "Init" 1 "Fahreruebernahme_Hinweis_ZAT_Automat_ohne_Gong" 2 "Fahreruebernahme_Hinweis_ZAT_Automat_mit_Gong" 3 "Fahreruebernahme_Hinweis_ZAT_Handschalter_ohne_Gong" 4 "Fahreruebernahme_Hinweis_ZAT_Handschalter_mit_Gong" 5 "Fahreruebernahme_Hinweis_ZAS_Automat_ohne_Gong" 6 "Fahreruebernahme_Hinweis_ZAS_Automat_mit_Gong" 7 "Fahreruebernahme_Hinweis_ZAS_Handschalter_ohne_Gong" 8 "Fahreruebernahme_Hinweis_ZAS_Handschalter_mit_Gong" 9 "RemoteStart_aktiv_ohne_Gong" 10 "RemoteStart_aktiv_mit_Gong" 11 "void" 12 "void" 13 "void" 14 "void" 15 "void" ;
VAL_ 960 ZAS_Kl_S 0 "aus" 1 "S_Kontakt_ein" ;
VAL_ 960 ZAS_Kl_15 0 "aus" 1 "ein" ;
VAL_ 960 ZAS_Kl_X 0 "aus" 1 "ein" ;
VAL_ 960 ZAS_Kl_50_Startanforderung 0 "aus" 1 "KL50_ein_Startwunsch_Fahrer" ;
VAL_ 960 BCM_Remotestart_Betrieb 0 "kein_RS_Betrieb" 1 "RS_Betrieb" ;
VAL_ 960 ZAS_Kl_Infotainment 0 "inaktiv" 1 "aktiv" ;
VAL_ 960 BCM_Remotestart_KL15_Anf 0 "inaktiv" 1 "aktiv" ;
VAL_ 960 BCM_Remotestart_MO_Start 0 "nicht_angefordert" 1 "angefordert" ;
VAL_ 960 KST_Warn_P1_ZST_def 0 "nicht_defekt" 1 "defekt" ;
VAL_ 960 KST_Warn_P2_ZST_def 0 "nicht_defekt" 1 "defekt" ;
VAL_ 960 KST_Fahrerhinweis_1 0 "inaktiv" 1 "aktiv" ;
VAL_ 960 KST_Fahrerhinweis_2 0 "inaktiv" 1 "aktiv" ;
VAL_ 960 BCM_Ausparken_Betrieb 0 "kein_Betrieb" 1 "Ausparkvorgang_aktiv" ;
VAL_ 960 KST_Fahrerhinweis_4 0 "inaktiv" 1 "aktiv" ;
VAL_ 960 KST_Fahrerhinweis_5 0 "inaktiv" 1 "aktiv" ;
VAL_ 960 KST_Fahrerhinweis_6 0 "inaktiv" 1 "aktiv" ;
